VERSION "dbc-export 1 2026.26.6.5"

NS_ :

BS_:

BU_: ADSP APSB CMP DAS EPAS3P GTW OCS1P PTC RCM TCU TCU2 TRCM UDS UI UIS VCLEFT

BO_ 971 APSB_status: 8 APSB
 SG_ APSB_appStatusMonitorState : 0|3@1+ (1,0) [0|7] "" Vector__XXX
 SG_ APSB_vehBehaviorState : 4|4@1+ (1,0) [0|15] "" Vector__XXX
 SG_ APSB_canMaster : 8|2@1+ (1,0) [0|2] "" Vector__XXX
 SG_ APSB_appGpioState : 10|2@1+ (1,0) [0|3] "" Vector__XXX
 SG_ APSB_eacInternalState : 12|3@1+ (1,0) [0|7] "" Vector__XXX
 SG_ APSB_switchState : 15|1@1+ (1,0) [0|1] "" Vector__XXX
 SG_ APSB_apbStatusMonitorState : 16|3@1+ (1,0) [0|7] "" Vector__XXX
 SG_ APSB_apbGpioState : 20|2@1+ (1,0) [0|3] "" Vector__XXX
 SG_ APSB_statusCounter : 22|4@1+ (1,0) [0|15] "" Vector__XXX
 SG_ APSB_locLimitReason : 26|3@1+ (1,0) [0|7] "" Vector__XXX
 SG_ APSB_appPowerStateRequest : 29|2@1+ (1,0) [0|3] "" Vector__XXX
 SG_ APSB_appPowerStateReason : 31|4@1+ (1,0) [0|15] "" Vector__XXX
 SG_ APSB_apbPowerStateRequest : 36|2@1+ (1,0) [0|3] "" Vector__XXX
 SG_ APSB_apbPowerStateReason : 38|4@1+ (1,0) [0|15] "" Vector__XXX
 SG_ APSB_heaterStateDebug : 43|3@1+ (1,0) [0|6] "" Vector__XXX
 SG_ APSB_autosummonCounter : 46|3@1+ (1,0) [0|7] "" Vector__XXX
 SG_ APSB_autosummonAlert : 49|1@1+ (1,0) [0|1] "" Vector__XXX
 SG_ APSB_gpsAntennaState : 50|2@1+ (1,0) [0|3] "" Vector__XXX
 SG_ APSB_arbState : 52|3@1+ (1,0) [0|7] "" Vector__XXX
 SG_ APSB_socPowerOperatingMode : 55|2@1+ (1,0) [0|3] "" Vector__XXX

BO_ 845 APSB_warningMatrix0: 8 APSB
 SG_ APSB_w001_DEPRECATED : 0|1@1+ (1,0) [0|1] "" Vector__XXX
 SG_ APSB_w002_ldwDisabled : 1|1@1+ (1,0) [0|1] "" Vector__XXX
 SG_ APSB_w003_isaDisabled : 2|1@1+ (1,0) [0|1] "" Vector__XXX
 SG_ APSB_w004_accDisabled : 3|1@1+ (1,0) [0|1] "" Vector__XXX
 SG_ APSB_w005_fcwCancelled : 4|1@1+ (1,0) [0|1] "" Vector__XXX
 SG_ APSB_w006_aebCancelled : 5|1@1+ (1,0) [0|1] "" Vector__XXX
 SG_ APSB_w007_ahlbDisabled : 6|1@1+ (1,0) [0|1] "" Vector__XXX
 SG_ APSB_w008_parkDisabled : 7|1@1+ (1,0) [0|1] "" Vector__XXX
 SG_ APSB_w009_aebFault : 8|1@1+ (1,0) [0|1] "" Vector__XXX
 SG_ APSB_w010_radcCalibIssue : 9|1@1+ (1,0) [0|1] "" Vector__XXX
 SG_ APSB_w011_scaEvent : 10|1@1+ (1,0) [0|1] "" Vector__XXX
 SG_ APSB_w012_Cam_BootFailure : 11|1@1+ (1,0) [0|1] "" Vector__XXX
 SG_ APSB_w013_Cam_Watchdog : 12|1@1+ (1,0) [0|1] "" Vector__XXX
 SG_ APSB_w014_swAssert : 13|1@1+ (1,0) [0|1] "" Vector__XXX
 SG_ APSB_w015_Camera_Failsafes : 14|1@1+ (1,0) [0|1] "" Vector__XXX
 SG_ APSB_w016_aeb_e_event : 15|1@1+ (1,0) [0|1] "" Vector__XXX
 SG_ APSB_w017_Cam_Msg_MIA : 16|1@1+ (1,0) [0|1] "" Vector__XXX
 SG_ APSB_w018_ECU_Power_Issue : 17|1@1+ (1,0) [0|1] "" Vector__XXX
 SG_ APSB_w019_ECU_Stack_Overflow : 18|1@1+ (1,0) [0|1] "" Vector__XXX
 SG_ APSB_w020_ECU_checkstopError : 19|1@1+ (1,0) [0|1] "" Vector__XXX
 SG_ APSB_w021_ECU_Temperature_Issue : 20|1@1+ (1,0) [0|1] "" Vector__XXX
 SG_ APSB_w022_ECU_EEPROM_Failure : 21|1@1+ (1,0) [0|1] "" Vector__XXX
 SG_ APSB_w023_ECU_Cam_Statemismatc : 22|1@1+ (1,0) [0|1] "" Vector__XXX
 SG_ APSB_w024_ECU_Watchdog_Reset : 23|1@1+ (1,0) [0|1] "" Vector__XXX
 SG_ APSB_w025_LC_Steering_Override : 24|1@1+ (1,0) [0|1] "" Vector__XXX
 SG_ APSB_w026_ECU_timingIssue : 25|1@1+ (1,0) [0|1] "" Vector__XXX
 SG_ APSB_w027_ECU_Reset_Fault : 26|1@1+ (1,0) [0|1] "" Vector__XXX
 SG_ APSB_w028_spi_rx_error : 27|1@1+ (1,0) [0|1] "" Vector__XXX
 SG_ APSB_w029_spi_tx_error : 28|1@1+ (1,0) [0|1] "" Vector__XXX
 SG_ APSB_w030_Heater_Issue : 29|1@1+ (1,0) [0|1] "" Vector__XXX
 SG_ APSB_w031_canRxError : 30|1@1+ (1,0) [0|1] "" Vector__XXX
 SG_ APSB_w032_canTxError : 31|1@1+ (1,0) [0|1] "" Vector__XXX
 SG_ APSB_w033_gtwMia : 32|1@1+ (1,0) [0|1] "" Vector__XXX
 SG_ APSB_w034_sccmMia : 33|1@1+ (1,0) [0|1] "" Vector__XXX
 SG_ APSB_w035_espMia : 34|1@1+ (1,0) [0|1] "" Vector__XXX
 SG_ APSB_w036_bdyMia : 35|1@1+ (1,0) [0|1] "" Vector__XXX
 SG_ APSB_w037_camTacIssue : 36|1@1+ (1,0) [0|1] "" Vector__XXX
 SG_ APSB_w038_camFailure : 37|1@1+ (1,0) [0|1] "" Vector__XXX
 SG_ APSB_w039_sdm_rcm_Mia : 38|1@1+ (1,0) [0|1] "" Vector__XXX
 SG_ APSB_w040_autopilotAngleSaturate : 39|1@1+ (1,0) [0|1] "" Vector__XXX
 SG_ APSB_w041_autopilotRateSaturated : 40|1@1+ (1,0) [0|1] "" Vector__XXX
 SG_ APSB_w042_autopilotAborting : 41|1@1+ (1,0) [0|1] "" Vector__XXX
 SG_ APSB_w043_camLongRunTime : 42|1@1+ (1,0) [0|1] "" Vector__XXX
 SG_ APSB_w044_appMobileyeFailure : 43|1@1+ (1,0) [0|1] "" Vector__XXX
 SG_ APSB_w045_radMia : 44|1@1+ (1,0) [0|1] "" Vector__XXX
 SG_ APSB_w046_eepromRecordAbsent : 45|1@1+ (1,0) [0|1] "" Vector__XXX
 SG_ APSB_w047_edrEvent : 46|1@1+ (1,0) [0|1] "" Vector__XXX
 SG_ APSB_w048_DAS_Features_Disabled : 47|1@1+ (1,0) [0|1] "" Vector__XXX
 SG_ APSB_w049_eyeqVersionMismatch : 48|1@1+ (1,0) [0|1] "" Vector__XXX
 SG_ APSB_w050_aeb_event : 49|1@1+ (1,0) [0|1] "" Vector__XXX
 SG_ APSB_w051_radcEcuIssue : 50|1@1+ (1,0) [0|1] "" Vector__XXX
 SG_ APSB_w052_radcSensorIssue : 51|1@1+ (1,0) [0|1] "" Vector__XXX
 SG_ APSB_w053_radcCommIssue : 52|1@1+ (1,0) [0|1] "" Vector__XXX
 SG_ APSB_w054_camAutofix : 53|1@1+ (1,0) [0|1] "" Vector__XXX
 SG_ APSB_w055_radcVersionMismatch : 54|1@1+ (1,0) [0|1] "" Vector__XXX
 SG_ APSB_w056_diMia : 55|1@1+ (1,0) [0|1] "" Vector__XXX
 SG_ APSB_w057_mcuMia : 56|1@1+ (1,0) [0|1] "" Vector__XXX
 SG_ APSB_w058_epbMia : 57|1@1+ (1,0) [0|1] "" Vector__XXX
 SG_ APSB_w059_parkMia : 58|1@1+ (1,0) [0|1] "" Vector__XXX
 SG_ APSB_w060_fcw_event : 59|1@1+ (1,0) [0|1] "" Vector__XXX
 SG_ APSB_w061_tasMia : 60|1@1+ (1,0) [0|1] "" Vector__XXX
 SG_ APSB_w062_radcAlignment : 61|1@1+ (1,0) [0|1] "" Vector__XXX
 SG_ APSB_w063_parkVersionMismatch : 62|1@1+ (1,0) [0|1] "" Vector__XXX
 SG_ APSB_w064_epasMia : 63|1@1+ (1,0) [0|1] "" Vector__XXX

BO_ 1143 APSB_warningMatrix1: 8 APSB
 SG_ APSB_w065_deserializerOvercurren : 0|1@1+ (1,0) [0|1] "" Vector__XXX
 SG_ APSB_w066_deserializerLockLost : 1|1@1+ (1,0) [0|1] "" Vector__XXX
 SG_ APSB_w067_steeringAlignment : 2|1@1+ (1,0) [0|1] "" Vector__XXX
 SG_ APSB_w068_vlInconsistency : 3|1@1+ (1,0) [0|1] "" Vector__XXX
 SG_ APSB_w069_apcSpaceMasked : 4|1@1+ (1,0) [0|1] "" Vector__XXX
 SG_ APSB_w070_apcIncompleteCal : 5|1@1+ (1,0) [0|1] "" Vector__XXX
 SG_ APSB_w071_selfparkStarted : 6|1@1+ (1,0) [0|1] "" Vector__XXX
 SG_ APSB_w072_selfparkComplete : 7|1@1+ (1,0) [0|1] "" Vector__XXX
 SG_ APSB_w073_issueEscalatedLDW : 8|1@1+ (1,0) [0|1] "" Vector__XXX
 SG_ APSB_w074_inPathStationaryObst : 9|1@1+ (1,0) [0|1] "" Vector__XXX
 SG_ APSB_w075_scMia : 10|1@1+ (1,0) [0|1] "" Vector__XXX
 SG_ APSB_w076_mobilEyeSetC : 11|1@1+ (1,0) [0|1] "" Vector__XXX
 SG_ APSB_w077_pmmActive : 12|1@1+ (1,0) [0|1] "" Vector__XXX
 SG_ APSB_w078_pmmActive2 : 13|1@1+ (1,0) [0|1] "" Vector__XXX
 SG_ APSB_w079_edrAvailable : 14|1@1+ (1,0) [0|1] "" Vector__XXX
 SG_ APSB_w080_accFailedActivation : 15|1@1+ (1,0) [0|1] "" Vector__XXX
 SG_ APSB_w081_pmmActiveBraking : 16|1@1+ (1,0) [0|1] "" Vector__XXX
 SG_ APSB_w082_inPathFSviolation : 17|1@1+ (1,0) [0|1] "" Vector__XXX
 SG_ APSB_w083_inPathRADObject : 18|1@1+ (1,0) [0|1] "" Vector__XXX
 SG_ APSB_w084_pmmIPSO : 19|1@1+ (1,0) [0|1] "" Vector__XXX
 SG_ APSB_w085_pmmSteering : 20|1@1+ (1,0) [0|1] "" Vector__XXX
 SG_ APSB_w086_robCollision : 21|1@1+ (1,0) [0|1] "" Vector__XXX
 SG_ APSB_w087_DEPRECATED : 22|1@1+ (1,0) [0|1] "" Vector__XXX
 SG_ APSB_w088_DEPRECATED : 23|1@1+ (1,0) [0|1] "" Vector__XXX
 SG_ APSB_w089_DEPRECATED : 24|1@1+ (1,0) [0|1] "" Vector__XXX
 SG_ APSB_w090_DEPRECATED : 25|1@1+ (1,0) [0|1] "" Vector__XXX
 SG_ APSB_w091_DEPRECATED : 26|1@1+ (1,0) [0|1] "" Vector__XXX
 SG_ APSB_w092_DEPRECATED : 27|1@1+ (1,0) [0|1] "" Vector__XXX
 SG_ APSB_w093_DEPRECATED : 28|1@1+ (1,0) [0|1] "" Vector__XXX
 SG_ APSB_w094_DEPRECATED : 29|1@1+ (1,0) [0|1] "" Vector__XXX
 SG_ APSB_w095_DEPRECATED : 30|1@1+ (1,0) [0|1] "" Vector__XXX
 SG_ APSB_w096_DEPRECATED : 31|1@1+ (1,0) [0|1] "" Vector__XXX
 SG_ APSB_w097_DEPRECATED : 32|1@1+ (1,0) [0|1] "" Vector__XXX
 SG_ APSB_w098_DEPRECATED : 33|1@1+ (1,0) [0|1] "" Vector__XXX
 SG_ APSB_w099_DEPRECATED : 34|1@1+ (1,0) [0|1] "" Vector__XXX
 SG_ APSB_w100_DEPRECATED : 35|1@1+ (1,0) [0|1] "" Vector__XXX
 SG_ APSB_w101_DEPRECATED : 36|1@1+ (1,0) [0|1] "" Vector__XXX
 SG_ APSB_w102_DEPRECATED : 37|1@1+ (1,0) [0|1] "" Vector__XXX
 SG_ APSB_w103_robExperimentalAEB : 38|1@1+ (1,0) [0|1] "" Vector__XXX
 SG_ APSB_w104_DEPRECATED : 39|1@1+ (1,0) [0|1] "" Vector__XXX
 SG_ APSB_w105_DEPRECATED : 40|1@1+ (1,0) [0|1] "" Vector__XXX
 SG_ APSB_w106_torsionBarOffset : 41|1@1+ (1,0) [0|1] "" Vector__XXX

BO_ 942 APSB_warningMatrix2: 8 APSB
 SG_ APSB_w129_ECU_Power_Issue : 0|1@1+ (1,0) [0|1] "" Vector__XXX
 SG_ APSB_w130_ECU_Thermal_Issue : 1|1@1+ (1,0) [0|1] "" Vector__XXX
 SG_ APSB_w131_trap_exception : 2|1@1+ (1,0) [0|1] "" Vector__XXX
 SG_ APSB_w132_appVersionMismatch : 3|1@1+ (1,0) [0|1] "" Vector__XXX
 SG_ APSB_w133_ETHSwitchError : 4|1@1+ (1,0) [0|1] "" Vector__XXX
 SG_ APSB_w134_appMia : 5|1@1+ (1,0) [0|1] "" Vector__XXX
 SG_ APSB_w135_appCritical : 6|1@1+ (1,0) [0|1] "" Vector__XXX
 SG_ APSB_w136_gpsDisabled : 7|1@1+ (1,0) [0|1] "" Vector__XXX
 SG_ APSB_w137_gpsFaultReset : 8|1@1+ (1,0) [0|1] "" Vector__XXX
 SG_ APSB_w138_gpsComIssue : 9|1@1+ (1,0) [0|1] "" Vector__XXX
 SG_ APSB_w139_udpBufferOverflow : 10|1@1+ (1,0) [0|1] "" Vector__XXX
 SG_ APSB_w140_vcfrontMiaVehicleBus : 11|1@1+ (1,0) [0|1] "" Vector__XXX
 SG_ APSB_w141_rcmMiaPartyBus : 12|1@1+ (1,0) [0|1] "" Vector__XXX
 SG_ APSB_w142_diMiaPartyBus : 13|1@1+ (1,0) [0|1] "" Vector__XXX
 SG_ APSB_w143_espMiaPartyBus : 14|1@1+ (1,0) [0|1] "" Vector__XXX
 SG_ APSB_w144_vcleftMiaPartyBus : 15|1@1+ (1,0) [0|1] "" Vector__XXX
 SG_ APSB_w145_vcrightMiaPartyBus : 16|1@1+ (1,0) [0|1] "" Vector__XXX
 SG_ APSB_w146_epas3pMiaPartyBus : 17|1@1+ (1,0) [0|1] "" Vector__XXX
 SG_ APSB_w147_vcleftMiaVehBus : 18|1@1+ (1,0) [0|1] "" Vector__XXX
 SG_ APSB_w148_vcrightMiaVehBus : 19|1@1+ (1,0) [0|1] "" Vector__XXX
 SG_ APSB_w149_epblMiaVehBus : 20|1@1+ (1,0) [0|1] "" Vector__XXX
 SG_ APSB_w150_sccmMiaVehBus : 21|1@1+ (1,0) [0|1] "" Vector__XXX
 SG_ APSB_w151_apRecovered : 22|1@1+ (1,0) [0|1] "" Vector__XXX
 SG_ APSB_w152_gpsFusionStatus : 23|1@1+ (1,0) [0|1] "" Vector__XXX
 SG_ APSB_w153_eacInhibit : 24|1@1+ (1,0) [0|1] "" Vector__XXX
 SG_ APSB_w155_ethLwipError : 26|1@1+ (1,0) [0|1] "" Vector__XXX
 SG_ APSB_w156_lwipAssert : 27|1@1+ (1,0) [0|1] "" Vector__XXX
 SG_ APSB_w157_autopilotReboot : 28|1@1+ (1,0) [0|1] "" Vector__XXX
 SG_ APSB_w158_apbMia : 29|1@1+ (1,0) [0|1] "" Vector__XXX
 SG_ APSB_w159_apbCritical : 30|1@1+ (1,0) [0|1] "" Vector__XXX
 SG_ APSB_w160_apbVersionMismatch : 31|1@1+ (1,0) [0|1] "" Vector__XXX
 SG_ APSB_w161_gpsAntennaDisconnected : 32|1@1+ (1,0) [0|1] "" Vector__XXX
 SG_ APSB_w162_TurboA_DisRegPgoodErr : 33|1@1+ (1,0) [0|1] "" Vector__XXX
 SG_ APSB_w163_TurboA_DisRegNFault : 34|1@1+ (1,0) [0|1] "" Vector__XXX
 SG_ APSB_w164_TurboA_12VFuseFault : 35|1@1+ (1,0) [0|1] "" Vector__XXX
 SG_ APSB_w165_TurboA_Temp_NOS : 36|1@1+ (1,0) [0|1] "" Vector__XXX
 SG_ APSB_w166_TurboA_SMSLockStepErr : 37|1@1+ (1,0) [0|1] "" Vector__XXX
 SG_ APSB_w167_TurboA_TMU_Throttle : 38|1@1+ (1,0) [0|1] "" Vector__XXX
 SG_ APSB_w168_TurboA_SMS_WDOG : 39|1@1+ (1,0) [0|1] "" Vector__XXX
 SG_ APSB_w169_TurboA_SCS_LKUP : 40|1@1+ (1,0) [0|1] "" Vector__XXX
 SG_ APSB_w170_TurboA_A72_watchdog : 41|1@1+ (1,0) [0|1] "" Vector__XXX
 SG_ APSB_w171_TurboA_SMS_taskUtilErr : 42|1@1+ (1,0) [0|1] "" Vector__XXX
 SG_ APSB_w172_apFeaturesUnavailable : 43|1@1+ (1,0) [0|1] "" Vector__XXX
 SG_ APSB_w178_TurboB_DisRegPgoodErr : 49|1@1+ (1,0) [0|1] "" Vector__XXX
 SG_ APSB_w179_TurboB_DisRegNFault : 50|1@1+ (1,0) [0|1] "" Vector__XXX
 SG_ APSB_w180_TurboB_12VFuseFault : 51|1@1+ (1,0) [0|1] "" Vector__XXX
 SG_ APSB_w181_TurboB_Temp_NOS : 52|1@1+ (1,0) [0|1] "" Vector__XXX
 SG_ APSB_w182_TurboB_SMSLockStepErr : 53|1@1+ (1,0) [0|1] "" Vector__XXX
 SG_ APSB_w183_TurboB_TMU_Throttle : 54|1@1+ (1,0) [0|1] "" Vector__XXX
 SG_ APSB_w184_TurboB_SMS_WDOG : 55|1@1+ (1,0) [0|1] "" Vector__XXX
 SG_ APSB_w185_TurboB_SCS_LKUP : 56|1@1+ (1,0) [0|1] "" Vector__XXX
 SG_ APSB_w186_TurboB_A72_watchdog : 57|1@1+ (1,0) [0|1] "" Vector__XXX
 SG_ APSB_w187_TurboB_SMS_taskUtilErr : 58|1@1+ (1,0) [0|1] "" Vector__XXX
 SG_ APSB_w188_otherTurboUartMIA : 59|1@1+ (1,0) [0|1] "" Vector__XXX
 SG_ APSB_w189_vcfrontMiaPartyBus : 60|1@1+ (1,0) [0|1] "" Vector__XXX
 SG_ APSB_w190_iboosterMia : 61|1@1+ (1,0) [0|1] "" Vector__XXX
 SG_ APSB_w191_timesyncError : 62|1@1+ (1,0) [0|1] "" Vector__XXX
 SG_ APSB_w192_CANFault : 63|1@1+ (1,0) [0|1] "" Vector__XXX

BO_ 976 APSB_warningMatrix3: 8 APSB
 SG_ APSB_w193_camWindshieldUnclean : 0|1@1+ (1,0) [0|1] "" Vector__XXX
 SG_ APSB_w194_accDriverResumeRqrd : 1|1@1+ (1,0) [0|1] "" Vector__XXX
 SG_ APSB_w195_scwUnavailable : 2|1@1+ (1,0) [0|1] "" Vector__XXX
 SG_ APSB_w196_stopSignWarning : 3|1@1+ (1,0) [0|1] "" Vector__XXX
 SG_ APSB_w197_redLightWarning : 4|1@1+ (1,0) [0|1] "" Vector__XXX
 SG_ APSB_w198_tsrUnavailable : 5|1@1+ (1,0) [0|1] "" Vector__XXX
 SG_ APSB_w199_apcAbort : 6|1@1+ (1,0) [0|1] "" Vector__XXX
 SG_ APSB_w200_lcSlowdown : 7|1@1+ (1,0) [0|1] "" Vector__XXX
 SG_ APSB_w201_lcAborting : 8|1@1+ (1,0) [0|1] "" Vector__XXX
 SG_ APSB_w202_scwNoisyEnvironment : 9|1@1+ (1,0) [0|1] "" Vector__XXX
 SG_ APSB_w203_apcActivation : 10|1@1+ (1,0) [0|1] "" Vector__XXX
 SG_ APSB_w204_apcFinalFront : 11|1@1+ (1,0) [0|1] "" Vector__XXX
 SG_ APSB_w205_apcFinalRear : 12|1@1+ (1,0) [0|1] "" Vector__XXX
 SG_ APSB_w206_autosteerNotEnabled : 13|1@1+ (1,0) [0|1] "" Vector__XXX
 SG_ APSB_w207_autosteerUnavailable : 14|1@1+ (1,0) [0|1] "" Vector__XXX
 SG_ APSB_w208_rackDetected : 15|1@1+ (1,0) [0|1] "" Vector__XXX
 SG_ APSB_w209_autoSummonRequest : 16|1@1+ (1,0) [0|1] "" Vector__XXX
 SG_ APSB_w210_camObstrcted : 17|1@1+ (1,0) [0|1] "" Vector__XXX
 SG_ APSB_w211_accNoSeatBelt : 18|1@1+ (1,0) [0|1] "" Vector__XXX
 SG_ APSB_w212_lcUnavailableStrikeOut : 19|1@1+ (1,0) [0|1] "" Vector__XXX
 SG_ APSB_w213_autosteerStruckOut : 20|1@1+ (1,0) [0|1] "" Vector__XXX
 SG_ APSB_w214_driverNotIntracting : 21|1@1+ (1,0) [0|1] "" Vector__XXX
 SG_ APSB_w215_contDriverNotIntractin : 22|1@1+ (1,0) [0|1] "" Vector__XXX
 SG_ APSB_w216_driverOverriding : 23|1@1+ (1,0) [0|1] "" Vector__XXX
 SG_ APSB_w217_lcUnavailableSpeeding : 24|1@1+ (1,0) [0|1] "" Vector__XXX
 SG_ APSB_w218_lcSpeedExceededLimit : 25|1@1+ (1,0) [0|1] "" Vector__XXX
 SG_ APSB_w219_lcTempUnavailableSpeed : 26|1@1+ (1,0) [0|1] "" Vector__XXX
 SG_ APSB_w220_lcTempUnavailableRoad : 27|1@1+ (1,0) [0|1] "" Vector__XXX
 SG_ APSB_w221_accRadarBlind : 28|1@1+ (1,0) [0|1] "" Vector__XXX
 SG_ APSB_w222_accCameraBlind : 29|1@1+ (1,0) [0|1] "" Vector__XXX
 SG_ APSB_w223_accObjectInPath : 30|1@1+ (1,0) [0|1] "" Vector__XXX
 SG_ APSB_w224_accCameraCalibration : 31|1@1+ (1,0) [0|1] "" Vector__XXX
 SG_ APSB_w225_lcDegradedVisSpeedLmt : 32|1@1+ (1,0) [0|1] "" Vector__XXX
 SG_ APSB_w226_lcCamCalNeededSpeedLmt : 33|1@1+ (1,0) [0|1] "" Vector__XXX
 SG_ APSB_w227_virtualWallBlocked : 34|1@1+ (1,0) [0|1] "" Vector__XXX
 SG_ APSB_w228_DEPRECATED : 35|1@1+ (1,0) [0|1] "" Vector__XXX
 SG_ APSB_w229_alcUltrasoundDamaged : 36|1@1+ (1,0) [0|1] "" Vector__XXX
 SG_ APSB_w230_alcUltrasoundBlocked : 37|1@1+ (1,0) [0|1] "" Vector__XXX
 SG_ APSB_w231_idfEvent : 38|1@1+ (1,0) [0|1] "" Vector__XXX
 SG_ APSB_w232_laneChangeRequested : 39|1@1+ (1,0) [0|1] "" Vector__XXX
 SG_ APSB_w235_a72LoopDetected : 42|1@1+ (1,0) [0|1] "" Vector__XXX
 SG_ APSB_w236_canSharedMemError : 43|1@1+ (1,0) [0|1] "" Vector__XXX
 SG_ APSB_w237_faultMgrEventDetected : 44|1@1+ (1,0) [0|1] "" Vector__XXX
 SG_ APSB_w238_resetReason : 45|1@1+ (1,0) [0|1] "" Vector__XXX
 SG_ APSB_w241_ddrInitFailures : 48|1@1+ (1,0) [0|1] "" Vector__XXX
 SG_ APSB_w242_tripMBISTFailure : 49|1@1+ (1,0) [0|1] "" Vector__XXX
 SG_ APSB_w243_tripHWErrorStatus : 50|1@1+ (1,0) [0|1] "" Vector__XXX
 SG_ APSB_w244_gpuHWFaultStatus : 51|1@1+ (1,0) [0|1] "" Vector__XXX
 SG_ APSB_w245_eloopRxFromUnexpectedS : 52|1@1+ (1,0) [0|1] "" Vector__XXX
 SG_ APSB_w246_ethloopSwitchPortLinkD : 53|1@1+ (1,0) [0|1] "" Vector__XXX
 SG_ APSB_w247_ethernetFrameError : 54|1@1+ (1,0) [0|1] "" Vector__XXX
 SG_ APSB_w248_ethloopSwitchPoorSqi : 55|1@1+ (1,0) [0|1] "" Vector__XXX
 SG_ APSB_w249_ufsFailures : 56|1@1+ (1,0) [0|1] "" Vector__XXX
 SG_ APSB_w250_ethloopSwitchMemUsageT : 57|1@1+ (1,0) [0|1] "" Vector__XXX
 SG_ APSB_w251_ethloopSwitchMemUsageT : 58|1@1+ (1,0) [0|1] "" Vector__XXX
 SG_ APSB_w252_ethSwitchPortLinkDown : 59|1@1+ (1,0) [0|1] "" Vector__XXX
 SG_ APSB_w253_powerStateTimeout : 60|1@1+ (1,0) [0|1] "" Vector__XXX
 SG_ APSB_w254_sleepStateTimeout : 61|1@1+ (1,0) [0|1] "" Vector__XXX
 SG_ APSB_w255_bootHealth : 62|1@1+ (1,0) [0|1] "" Vector__XXX

BO_ 1003 APSB_warningMatrix4: 8 APSB
 SG_ APSB_w257_assertFailure : 0|1@1+ (1,0) [0|1] "" Vector__XXX
 SG_ APSB_w258_qspiFlashSectorChecksu : 1|1@1+ (1,0) [0|1] "" Vector__XXX
 SG_ APSB_w259_qspiFailure : 2|1@1+ (1,0) [0|1] "" Vector__XXX
 SG_ APSB_w260_pgoodFailure : 3|1@1+ (1,0) [0|1] "" Vector__XXX
 SG_ APSB_w261_vrmFaultGrpA : 4|1@1+ (1,0) [0|1] "" Vector__XXX
 SG_ APSB_w262_vrmFaultGrpB : 5|1@1+ (1,0) [0|1] "" Vector__XXX
 SG_ APSB_w263_vrmFaultGrpC : 6|1@1+ (1,0) [0|1] "" Vector__XXX
 SG_ APSB_w264_ddrPhy0Failures : 7|1@1+ (1,0) [0|1] "" Vector__XXX
 SG_ APSB_w265_ddrPhy1Failures : 8|1@1+ (1,0) [0|1] "" Vector__XXX
 SG_ APSB_w266_ddrPhy2Failures : 9|1@1+ (1,0) [0|1] "" Vector__XXX
 SG_ APSB_w267_ddrPhy3Failures : 10|1@1+ (1,0) [0|1] "" Vector__XXX
 SG_ APSB_w268_ddrControllerFailures : 11|1@1+ (1,0) [0|1] "" Vector__XXX
 SG_ APSB_w269_ethSwitchRxPageCountTo : 12|1@1+ (1,0) [0|1] "" Vector__XXX
 SG_ APSB_w270_ethSwitchRxPageCountTo : 13|1@1+ (1,0) [0|1] "" Vector__XXX
 SG_ APSB_w271_ddrScheduler0EccErrors : 14|1@1+ (1,0) [0|1] "" Vector__XXX
 SG_ APSB_w272_ddrScheduler1EccErrors : 15|1@1+ (1,0) [0|1] "" Vector__XXX
 SG_ APSB_w273_ddrScheduler2EccErrors : 16|1@1+ (1,0) [0|1] "" Vector__XXX
 SG_ APSB_w274_ddrScheduler3EccErrors : 17|1@1+ (1,0) [0|1] "" Vector__XXX
 SG_ APSB_w275_ddrScheduler4EccErrors : 18|1@1+ (1,0) [0|1] "" Vector__XXX
 SG_ APSB_w276_ddrScheduler5EccErrors : 19|1@1+ (1,0) [0|1] "" Vector__XXX
 SG_ APSB_w277_ddrScheduler6EccErrors : 20|1@1+ (1,0) [0|1] "" Vector__XXX
 SG_ APSB_w278_ddrScheduler7EccErrors : 21|1@1+ (1,0) [0|1] "" Vector__XXX
 SG_ APSB_w279_ufsPartitionError : 22|1@1+ (1,0) [0|1] "" Vector__XXX
 SG_ APSB_w280_pepsMia : 23|1@1+ (1,0) [0|1] "" Vector__XXX
 SG_ APSB_w281_rsaMia : 24|1@1+ (1,0) [0|1] "" Vector__XXX
 SG_ APSB_w282_smmuError : 25|1@1+ (1,0) [0|1] "" Vector__XXX
 SG_ APSB_w283_psfaMia : 26|1@1+ (1,0) [0|1] "" Vector__XXX
 SG_ APSB_w284_cam12VBuckBoostAPwrIss : 27|1@1+ (1,0) [0|1] "" Vector__XXX
 SG_ APSB_w285_cam12VBuckBoostBPwrIss : 28|1@1+ (1,0) [0|1] "" Vector__XXX
 SG_ APSB_w286_cam12VEFuseAPrimaryIss : 29|1@1+ (1,0) [0|1] "" Vector__XXX
 SG_ APSB_w287_cam12VEFuseASecondaryI : 30|1@1+ (1,0) [0|1] "" Vector__XXX
 SG_ APSB_w288_brakeboosterMia : 31|1@1+ (1,0) [0|1] "" Vector__XXX
 SG_ APSB_w289_turboTemperatureWarnin : 32|1@1+ (1,0) [0|1] "" Vector__XXX
 SG_ APSB_w290_cam12VBuckBoostBPwrRin : 33|1@1+ (1,0) [0|1] "" Vector__XXX
 SG_ APSB_w291_eplannerError : 34|1@1+ (1,0) [0|1] "" Vector__XXX
 SG_ APSB_w292_CH_busOff : 35|1@1+ (1,0) [0|1] "" Vector__XXX
 SG_ APSB_w293_PARTY_busOff : 36|1@1+ (1,0) [0|1] "" Vector__XXX
 SG_ APSB_w294_VEH_busOff : 37|1@1+ (1,0) [0|1] "" Vector__XXX
 SG_ APSB_w295_PT_busOff : 38|1@1+ (1,0) [0|1] "" Vector__XXX
 SG_ APSB_w296_wdogMonTaskDeadlineMis : 39|1@1+ (1,0) [0|1] "" Vector__XXX
 SG_ APSB_w297_earlyWDogAlert : 40|1@1+ (1,0) [0|1] "" Vector__XXX
 SG_ APSB_w298_cpuToApCanSharedMemErr : 41|1@1+ (1,0) [0|1] "" Vector__XXX
 SG_ APSB_w299_apToCpuCanSharedMemErr : 42|1@1+ (1,0) [0|1] "" Vector__XXX
 SG_ APSB_w300_sharedMemoryAccessErro : 43|1@1+ (1,0) [0|1] "" Vector__XXX
 SG_ APSB_w301_nocTimeoutDetected : 44|1@1+ (1,0) [0|1] "" Vector__XXX
 SG_ APSB_w302_canAPShmFifoFull : 45|1@1+ (1,0) [0|1] "" Vector__XXX
 SG_ APSB_w303_canAPShmFifoEmpty : 46|1@1+ (1,0) [0|1] "" Vector__XXX
 SG_ APSB_w304_dataAbort : 47|1@1+ (1,0) [0|1] "" Vector__XXX
 SG_ APSB_w305_gpsPgoodFailure : 48|1@1+ (1,0) [0|1] "" Vector__XXX
 SG_ APSB_w306_ethPgoodFailure : 49|1@1+ (1,0) [0|1] "" Vector__XXX
 SG_ APSB_w307_eccEventDetected : 50|1@1+ (1,0) [0|1] "" Vector__XXX
 SG_ APSB_w308_pmicErrorDetected : 51|1@1+ (1,0) [0|1] "" Vector__XXX
 SG_ APSB_w309_ethBridgeDown : 52|1@1+ (1,0) [0|1] "" Vector__XXX
 SG_ APSB_w310_wakeBootMetrics : 53|1@1+ (1,0) [0|1] "" Vector__XXX
 SG_ APSB_w311_apbdgDasMia : 54|1@1+ (1,0) [0|1] "" Vector__XXX
 SG_ APSB_w312_apbdgApMia : 55|1@1+ (1,0) [0|1] "" Vector__XXX
 SG_ APSB_w313_BDY_busOff : 56|1@1+ (1,0) [0|1] "" Vector__XXX
 SG_ APSB_w315_epas3pMiaBdyBus : 58|1@1+ (1,0) [0|1] "" Vector__XXX
 SG_ APSB_w316_apBootHealth : 59|1@1+ (1,0) [0|1] "" Vector__XXX
 SG_ APSB_w317_uiMia : 60|1@1+ (1,0) [0|1] "" Vector__XXX
 SG_ APSB_w318_ethernetNetworkBufferH : 61|1@1+ (1,0) [0|1] "" Vector__XXX
 SG_ APSB_w319_vehDasImposterDetected : 62|1@1+ (1,0) [0|1] "" Vector__XXX
 SG_ APSB_w320_eplannerPreconditionsM : 63|1@1+ (1,0) [0|1] "" Vector__XXX

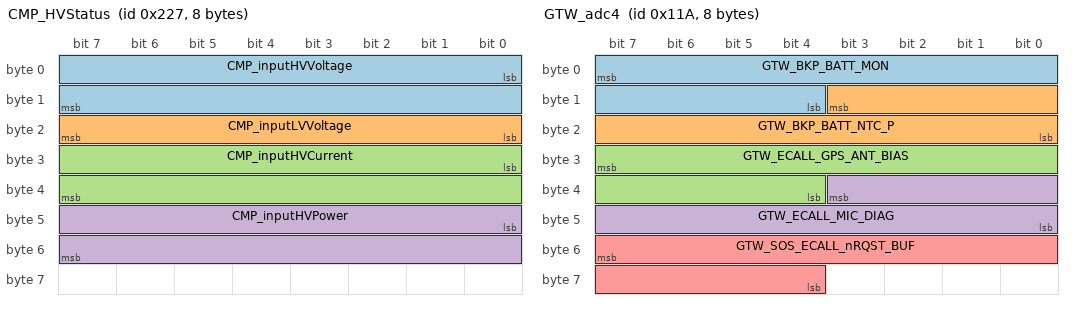
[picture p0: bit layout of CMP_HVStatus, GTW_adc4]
BO_ 551 CMP_HVStatus: 8 CMP
 SG_ CMP_inputHVVoltage : 0|16@1+ (0.1,0) [0|6553.4] "V" Vector__XXX
 SG_ CMP_inputLVVoltage : 16|8@1+ (0.1,0) [0|25.5] "V" Vector__XXX
 SG_ CMP_inputHVCurrent : 24|16@1+ (0.1,0) [0|6553.4] "A" Vector__XXX
 SG_ CMP_inputHVPower : 40|16@1+ (1,0) [0|65534] "W" Vector__XXX

BO_ 778 DAS_object: 8 DAS
 SG_ DAS_objectId M : 0|3@1+ (1,0) [0|7] "" Vector__XXX
 SG_ DAS_leadVehType m0 : 3|3@1+ (1,0) [0|7] "" Vector__XXX
 SG_ DAS_leadVehRelevantForControl m0 : 7|1@1+ (1,0) [0|1] "" Vector__XXX
 SG_ DAS_leadVehDx m0 : 8|8@1+ (0.5,0) [0|127] "m" Vector__XXX
 SG_ DAS_leadVehVxRel m0 : 16|4@1+ (4,-30) [-30|26] "m/s" Vector__XXX
 SG_ DAS_leadVehDy m0 : 20|7@1+ (0.35,-22.05) [-22.05|22.4] "m" Vector__XXX
 SG_ DAS_leadVehId m0 : 27|7@1+ (1,0) [0|126] "" Vector__XXX
 SG_ DAS_leadVeh2Type m0 : 34|3@1+ (1,0) [0|7] "" Vector__XXX
 SG_ DAS_leadVeh2RelevantForControl m0 : 38|1@1+ (1,0) [0|1] "" Vector__XXX
 SG_ DAS_leadVeh2Dx m0 : 39|8@1+ (0.5,0) [0|127] "m" Vector__XXX
 SG_ DAS_leadVeh2VxRel m0 : 47|4@1+ (4,-30) [-30|26] "m/s" Vector__XXX
 SG_ DAS_leadVeh2Dy m0 : 51|7@1+ (0.35,-22.05) [-22.05|22.4] "m" Vector__XXX
 SG_ DAS_leadVeh2Id m0 : 58|6@1+ (1,0) [1|63] "" Vector__XXX
 SG_ DAS_leftVehType m1 : 3|3@1+ (1,0) [0|7] "" Vector__XXX
 SG_ DAS_leftVehRelevantForControl m1 : 7|1@1+ (1,0) [0|1] "" Vector__XXX
 SG_ DAS_leftVehDx m1 : 8|8@1+ (0.5,0) [0|127] "m" Vector__XXX
 SG_ DAS_leftVehVxRel m1 : 16|4@1+ (4,-30) [-30|26] "m/s" Vector__XXX
 SG_ DAS_leftVehDy m1 : 20|7@1+ (0.35,-22.05) [-22.05|22.4] "m" Vector__XXX
 SG_ DAS_leftVehId m1 : 27|7@1+ (1,0) [0|126] "" Vector__XXX
 SG_ DAS_leftVeh2Type m1 : 34|3@1+ (1,0) [0|7] "" Vector__XXX
 SG_ DAS_leftVeh2RelevantForControl m1 : 38|1@1+ (1,0) [0|1] "" Vector__XXX
 SG_ DAS_leftVeh2Dx m1 : 39|8@1+ (0.5,0) [0|127] "m" Vector__XXX
 SG_ DAS_leftVeh2VxRel m1 : 47|4@1+ (4,-30) [-30|26] "m/s" Vector__XXX
 SG_ DAS_leftVeh2Dy m1 : 51|7@1+ (0.35,-22.05) [-22.05|22.4] "m" Vector__XXX
 SG_ DAS_leftVeh2Id m1 : 58|6@1+ (1,0) [1|63] "" Vector__XXX
 SG_ DAS_rightVehType m2 : 3|3@1+ (1,0) [0|7] "" Vector__XXX
 SG_ DAS_rightVehRelevantForControl m2 : 7|1@1+ (1,0) [0|1] "" Vector__XXX
 SG_ DAS_rightVehDx m2 : 8|8@1+ (0.5,0) [0|127] "m" Vector__XXX
 SG_ DAS_rightVehVxRel m2 : 16|4@1+ (4,-30) [-30|26] "m/s" Vector__XXX
 SG_ DAS_rightVehDy m2 : 20|7@1+ (0.35,-22.05) [-22.05|22.4] "m" Vector__XXX
 SG_ DAS_rightVehId m2 : 27|7@1+ (1,0) [0|126] "" Vector__XXX
 SG_ DAS_rightVeh2Type m2 : 34|3@1+ (1,0) [0|7] "" Vector__XXX
 SG_ DAS_rightVeh2RelevantForControl m2 : 38|1@1+ (1,0) [0|1] "" Vector__XXX
 SG_ DAS_rightVeh2Dx m2 : 39|8@1+ (0.5,0) [0|127] "m" Vector__XXX
 SG_ DAS_rightVeh2VxRel m2 : 47|4@1+ (4,-30) [-30|26] "m/s" Vector__XXX
 SG_ DAS_rightVeh2Dy m2 : 51|7@1+ (0.35,-22.05) [-22.05|22.4] "m" Vector__XXX
 SG_ DAS_rightVeh2Id m2 : 58|6@1+ (1,0) [1|63] "" Vector__XXX
 SG_ DAS_cutinVehType m3 : 3|3@1+ (1,0) [0|7] "" Vector__XXX
 SG_ DAS_cutinVehRelevantForControl m3 : 7|1@1+ (1,0) [0|1] "" Vector__XXX
 SG_ DAS_cutinVehDx m3 : 8|8@1+ (0.5,0) [0|127] "m" Vector__XXX
 SG_ DAS_cutinVehVxRel m3 : 16|4@1+ (4,-30) [-30|26] "m/s" Vector__XXX
 SG_ DAS_cutinVehDy m3 : 20|7@1+ (0.35,-22.05) [-22.05|22.4] "m" Vector__XXX
 SG_ DAS_cutinVehId m3 : 27|7@1+ (1,0) [0|126] "" Vector__XXX
 SG_ DAS_roadSignColor m4 : 3|3@1+ (1,0) [0|7] "" Vector__XXX
 SG_ DAS_roadSignId m4 : 6|8@1+ (1,0) [0|254] "" Vector__XXX
 SG_ DAS_roadSignStopLineDist m4 : 14|10@1+ (0.2,-20) [-20|184.4] "m" Vector__XXX
 SG_ DAS_roadSignControlActive m4 : 24|1@1+ (1,0) [0|1] "" Vector__XXX
 SG_ DAS_roadSignSource m4 : 25|2@1+ (1,0) [0|3] "" Vector__XXX
 SG_ DAS_roadSignArrow m4 : 27|3@1+ (1,0) [0|7] "" Vector__XXX
 SG_ DAS_roadSignOrientation m4 : 30|2@1+ (1,0) [0|3] "" Vector__XXX

BO_ 781 DAS_positioningEngineStatus: 8 DAS
 SG_ DAS_positioningEngineStatusMulti M : 0|4@1+ (1,0) [0|15] "" Vector__XXX
 SG_ DAS_meoSolverNumRuns m2 : 4|2@1+ (1,0) [0|3] "" Vector__XXX
 SG_ DAS_meoSolverReportTerminationTy m2 : 6|3@1+ (1,0) [0|7] "" Vector__XXX
 SG_ DAS_meoSolverReportTotalTimeS m2 : 9|3@1+ (1,0) [0|7] "" Vector__XXX
 SG_ DAS_meoHorizontalAccuracyM m2 : 12|6@1+ (1,0) [0|63] "m" Vector__XXX
 SG_ DAS_meoVerticalAccuracyM m2 : 18|6@1+ (1,0) [0|63] "m" Vector__XXX
 SG_ DAS_meoHeadingAccuracyDeg m2 : 24|3@1+ (1,0) [0|7] "deg" Vector__XXX
 SG_ DAS_meoHeadingValid m2 : 27|1@1+ (1,0) [0|1] "" Vector__XXX
 SG_ DAS_meoNumSatellitesUsed m2 : 28|5@1+ (1,0) [0|31] "" Vector__XXX
 SG_ DAS_meoGpsQualityLevel m2 : 33|3@1+ (1,0) [0|7] "" Vector__XXX
 SG_ DAS_meoFixType m2 : 36|3@1+ (1,0) [0|7] "" Vector__XXX
 SG_ DAS_meoResetCount m2 : 39|3@1+ (1,0) [0|7] "" Vector__XXX
 SG_ DAS_lastMeoResetReason m2 : 42|2@1+ (1,0) [0|3] "" Vector__XXX
 SG_ DAS_vioMultiGpsSelectedSource m3 : 4|3@1+ (1,0) [0|7] "" Vector__XXX
 SG_ DAS_vioMultiGpsPeCooldownActive m3 : 7|1@1+ (1,0) [0|1] "" Vector__XXX
 SG_ DAS_vioMultiGpsPeSppTdcpConsiste m3 : 8|1@1+ (1,0) [0|1] "" Vector__XXX
 SG_ DAS_vioMultiGpsPeMeoConsistentWi m3 : 9|1@1+ (1,0) [0|1] "" Vector__XXX
 SG_ DAS_vioMultiGpsPeSppTdcpVsR_0001 m3 : 10|4@1+ (1,0) [0|15] "m" Vector__XXX
 SG_ DAS_vioMultiGpsPeMeoVsRawGpsTran m3 : 14|4@1+ (1,0) [0|15] "m" Vector__XXX
 SG_ DAS_vioMultiGpsPeSppTdcpVsRawGps m3 : 18|3@1+ (1,0) [0|7] "deg" Vector__XXX
 SG_ DAS_vioMultiGpsPeMeoVsRawGpsRotD m3 : 21|3@1+ (1,0) [0|7] "deg" Vector__XXX
 SG_ DAS_publishedGpsSource m3 : 24|2@1+ (1,0) [0|3] "" Vector__XXX
 SG_ DAS_bluefinEnabled m3 : 26|1@1+ (1,0) [0|1] "" Vector__XXX
 SG_ DAS_orioleDisabled m3 : 27|1@1+ (1,0) [0|1] "" Vector__XXX
 SG_ DAS_disableMonarch m3 : 28|1@1+ (1,0) [0|1] "" Vector__XXX

BO_ 1548 DAS_telemetryRadar: 8 DAS
 SG_ DAS_TR_ObjIndex M : 0|5@1+ (1,0) [0|31] "" Vector__XXX
 SG_ DAS_TR_Counter : 54|2@1+ (1,0) [0|3] "" Vector__XXX
 SG_ DAS_TR_Obj00_Class m0 : 5|3@1+ (1,0) [0|7] "" Vector__XXX
 SG_ DAS_TR_Obj00_Dx m0 : 8|10@1+ (0.15625,0) [0|159.84375] "m" Vector__XXX
 SG_ DAS_TR_Obj00_Dy m0 : 18|6@1+ (0.5,-15.5) [-15.5|16] "m" Vector__XXX
 SG_ DAS_TR_Obj00_Vx m0 : 24|8@1+ (0.5,-63.5) [-63.5|64] "m/s" Vector__XXX
 SG_ DAS_TR_Obj00_RCS m0 : 32|8@1+ (0.25,-14) [-14|49.75] "dB" Vector__XXX
 SG_ DAS_TR_Obj00_Length m0 : 40|6@1+ (0.125,0) [0|7.875] "m" Vector__XXX
 SG_ DAS_TR_Obj00_MovingState m0 : 46|2@1+ (1,0) [0|3] "" Vector__XXX
 SG_ DAS_TR_Obj00_Dz m0 : 48|6@1+ (0.25,-5) [-5|10.75] "m" Vector__XXX
 SG_ DAS_TR_Obj00_Exist m0 : 56|5@1+ (3.125,0) [0|96.875] "%" Vector__XXX

BO_ 1592 EPAS3P_udsResponseCH: 8 EPAS3P
 SG_ EPAS3P_udsResponseDataCH : 7|64@0+ (1,0) [0|1.84467440737e+19] "" Vector__XXX

BO_ 888 GTW_ECall: 1 GTW
 SG_ GTW_GTW_SOS_ECALL_RQST : 0|1@1+ (1,0) [0|1] "" Vector__XXX
 SG_ GTW_LTE_ECALL_LOCK : 1|1@1+ (1,0) [0|1] "" Vector__XXX

BO_ 282 GTW_adc4: 8 GTW
 SG_ GTW_BKP_BATT_MON : 7|12@0+ (1,0) [0|4094] "mV" Vector__XXX
 SG_ GTW_BKP_BATT_NTC_P : 11|12@0+ (1,0) [0|4094] "mV" Vector__XXX
 SG_ GTW_ECALL_GPS_ANT_BIAS : 31|12@0+ (1,0) [0|4094] "mV" Vector__XXX
 SG_ GTW_ECALL_MIC_DIAG : 35|12@0+ (1,0) [0|4094] "mV" Vector__XXX
 SG_ GTW_SOS_ECALL_nRQST_BUF : 55|12@0+ (1,0) [0|4094] "mV" Vector__XXX

BO_ 1384 GTW_alertLog: 8 GTW
 SG_ GTW_alertID M : 0|9@1+ (1,0) [0|511] "" Vector__XXX
 SG_ GTW_alertState : 15|1@1+ (1,0) [0|1] "" Vector__XXX
 SG_ GTW_a014_crcVersion m14 : 16|32@1+ (1,0) [0|4294967295] "" Vector__XXX
 SG_ GTW_a015_crcVersion m15 : 16|32@1+ (1,0) [0|4294967295] "" Vector__XXX
 SG_ GTW_a016_crcVersion m16 : 16|32@1+ (1,0) [0|4294967295] "" Vector__XXX
 SG_ GTW_a017_crcVersion m17 : 16|32@1+ (1,0) [0|4294967295] "" Vector__XXX
 SG_ GTW_a018_crcVersion m18 : 16|32@1+ (1,0) [0|4294967295] "" Vector__XXX
 SG_ GTW_a019_crcVersion m19 : 16|32@1+ (1,0) [0|4294967295] "" Vector__XXX
 SG_ GTW_a020_crcVersion m20 : 16|32@1+ (1,0) [0|4294967295] "" Vector__XXX
 SG_ GTW_a021_crcVersion m21 : 16|32@1+ (1,0) [0|4294967295] "" Vector__XXX
 SG_ GTW_a022_crcVersion m22 : 16|32@1+ (1,0) [0|4294967295] "" Vector__XXX
 SG_ GTW_a023_crcVersion m23 : 16|32@1+ (1,0) [0|4294967295] "" Vector__XXX
 SG_ GTW_a024_crcVersion m24 : 16|32@1+ (1,0) [0|4294967295] "" Vector__XXX
 SG_ GTW_a025_crcVersion m25 : 16|32@1+ (1,0) [0|4294967295] "" Vector__XXX
 SG_ GTW_a026_crcVersion m26 : 16|32@1+ (1,0) [0|4294967295] "" Vector__XXX
 SG_ GTW_a027_crcVersion m27 : 16|32@1+ (1,0) [0|4294967295] "" Vector__XXX
 SG_ GTW_a028_crcVersion m28 : 16|32@1+ (1,0) [0|4294967295] "" Vector__XXX
 SG_ GTW_a029_crcVersion m29 : 16|32@1+ (1,0) [0|4294967295] "" Vector__XXX
 SG_ GTW_a030_crcVersion m30 : 16|32@1+ (1,0) [0|4294967295] "" Vector__XXX
 SG_ GTW_a031_crcVersion m31 : 16|32@1+ (1,0) [0|4294967295] "" Vector__XXX
 SG_ GTW_a032_crcVersion m32 : 16|32@1+ (1,0) [0|4294967295] "" Vector__XXX
 SG_ GTW_a033_crcVersion m33 : 16|32@1+ (1,0) [0|4294967295] "" Vector__XXX
 SG_ GTW_a034_crcVersion m34 : 16|32@1+ (1,0) [0|4294967295] "" Vector__XXX
 SG_ GTW_a035_crcVersion m35 : 16|32@1+ (1,0) [0|4294967295] "" Vector__XXX
 SG_ GTW_a036_crcVersion m36 : 16|32@1+ (1,0) [0|4294967295] "" Vector__XXX
 SG_ GTW_a037_crcVersion m37 : 16|32@1+ (1,0) [0|4294967295] "" Vector__XXX
 SG_ GTW_a038_crcVersion m38 : 16|32@1+ (1,0) [0|4294967295] "" Vector__XXX
 SG_ GTW_a039_crcVersion m39 : 16|32@1+ (1,0) [0|4294967295] "" Vector__XXX
 SG_ GTW_a040_crcVersion m40 : 16|32@1+ (1,0) [0|4294967295] "" Vector__XXX
 SG_ GTW_a041_crcVersion m41 : 16|32@1+ (1,0) [0|4294967295] "" Vector__XXX
 SG_ GTW_a042_crcVersion m42 : 16|32@1+ (1,0) [0|4294967295] "" Vector__XXX
 SG_ GTW_a043_crcVersion m43 : 16|32@1+ (1,0) [0|4294967295] "" Vector__XXX
 SG_ GTW_a045_crcVersion m45 : 16|32@1+ (1,0) [0|4294967295] "" Vector__XXX
 SG_ GTW_a046_crcVersion m46 : 16|32@1+ (1,0) [0|4294967295] "" Vector__XXX
 SG_ GTW_a047_crcVersion m47 : 16|32@1+ (1,0) [0|4294967295] "" Vector__XXX
 SG_ GTW_a048_crcVersion m48 : 16|32@1+ (1,0) [0|4294967295] "" Vector__XXX
 SG_ GTW_a049_headerError m49 : 16|2@1+ (1,0) [0|3] "" Vector__XXX
 SG_ GTW_a054_crcVersion m54 : 16|32@1+ (1,0) [0|4294967295] "" Vector__XXX
 SG_ GTW_a055_crcVersion m55 : 16|32@1+ (1,0) [0|4294967295] "" Vector__XXX
 SG_ GTW_a062_bmpWatchdogReason m62 : 16|3@1+ (1,0) [0|7] "" Vector__XXX
 SG_ GTW_a063_VEH_faultConfinement m63 : 16|2@1+ (1,0) [0|3] "" Vector__XXX
 SG_ GTW_a064_CH_faultConfinement m64 : 16|2@1+ (1,0) [0|3] "" Vector__XXX
 SG_ GTW_a065_PARTY_faultConfinement m65 : 16|2@1+ (1,0) [0|3] "" Vector__XXX
 SG_ GTW_a066_type m66 : 16|5@1+ (1,0) [0|31] "" Vector__XXX
 SG_ GTW_a066_exceptionCfgId m66 : 21|8@1+ (1,0) [0|255] "" Vector__XXX
 SG_ GTW_a066_uptime m66 : 29|32@1+ (1,0) [0|4294967295] "" Vector__XXX
 SG_ GTW_a066_core m66 : 61|3@1+ (1,0) [0|7] "" Vector__XXX
 SG_ GTW_a068_codeKeyMissing m68 : 16|1@1+ (1,0) [0|1] "" Vector__XXX
 SG_ GTW_a068_cmdKeyMissing m68 : 17|1@1+ (1,0) [0|1] "" Vector__XXX
 SG_ GTW_a069_sdIntStatusErrs m69 : 16|1@1+ (1,0) [0|1] "" Vector__XXX
 SG_ GTW_a069_sdTimeout m69 : 17|1@1+ (1,0) [0|1] "" Vector__XXX
 SG_ GTW_a069_sdCmdErr m69 : 18|1@1+ (1,0) [0|1] "" Vector__XXX
 SG_ GTW_a069_sdWriteErr m69 : 19|1@1+ (1,0) [0|1] "" Vector__XXX
 SG_ GTW_a069_sdReadErr m69 : 20|1@1+ (1,0) [0|1] "" Vector__XXX
 SG_ GTW_a069_autoCmd12Err m69 : 21|1@1+ (1,0) [0|1] "" Vector__XXX
 SG_ GTW_a072_updtFailureMask m72 : 16|32@1+ (1,0) [0|4294967295] "" Vector__XXX
 SG_ GTW_a073_SOCResetRequestor m73 : 16|3@1+ (1,0) [0|7] "" Vector__XXX
 SG_ GTW_a077_bmpPmicErrorType m77 : 16|3@1+ (1,0) [0|7] "" Vector__XXX
 SG_ GTW_a097_crcVersion m97 : 16|32@1+ (1,0) [0|4294967295] "" Vector__XXX
 SG_ GTW_a098_crcVersion m98 : 16|32@1+ (1,0) [0|4294967295] "" Vector__XXX
 SG_ GTW_a099_crcVersion m99 : 16|32@1+ (1,0) [0|4294967295] "" Vector__XXX
 SG_ GTW_a100_crcVersion m100 : 16|32@1+ (1,0) [0|4294967295] "" Vector__XXX
 SG_ GTW_a101_switchStuck m101 : 16|1@1+ (1,0) [0|1] "" Vector__XXX
 SG_ GTW_a101_ETH_SW_nINT m101 : 17|1@1+ (1,0) [0|1] "" Vector__XXX
 SG_ GTW_a106_crcVersion m106 : 16|32@1+ (1,0) [0|4294967295] "" Vector__XXX
 SG_ GTW_a107_crcVersion m107 : 16|32@1+ (1,0) [0|4294967295] "" Vector__XXX
 SG_ GTW_a108_crcVersion m108 : 16|32@1+ (1,0) [0|4294967295] "" Vector__XXX
 SG_ GTW_a117_MC_RGM_DES m117 : 16|32@1+ (1,0) [0|4294967295] "" Vector__XXX
 SG_ GTW_a118_MC_RGM_FES m118 : 16|32@1+ (1,0) [0|4294967295] "" Vector__XXX
 SG_ GTW_a122_BDY_faultConfinement m122 : 16|2@1+ (1,0) [0|3] "" Vector__XXX
 SG_ GTW_a129_crcVersion m129 : 16|32@1+ (1,0) [0|4294967295] "" Vector__XXX
 SG_ GTW_a138_sdLifetimeUsed m138 : 16|8@1+ (1,0) [0|255] "" Vector__XXX
 SG_ GTW_a139_crcVersion m139 : 16|32@1+ (1,0) [0|4294967295] "" Vector__XXX
 SG_ GTW_a150_crcVersion m150 : 16|32@1+ (1,0) [0|4294967295] "" Vector__XXX
 SG_ GTW_a151_crcVersion m151 : 16|32@1+ (1,0) [0|4294967295] "" Vector__XXX
 SG_ GTW_a155_crcVersion m155 : 16|32@1+ (1,0) [0|4294967295] "" Vector__XXX
 SG_ GTW_a164_crcVersion m164 : 16|32@1+ (1,0) [0|4294967295] "" Vector__XXX
 SG_ GTW_a165_crcVersion m165 : 16|32@1+ (1,0) [0|4294967295] "" Vector__XXX
 SG_ GTW_a169_TPMS_pressureFL m169 : 16|8@1+ (1,0) [0|255] "" Vector__XXX
 SG_ GTW_a170_TPMS_pressureFR m170 : 16|8@1+ (1,0) [0|255] "" Vector__XXX
 SG_ GTW_a171_TPMS_pressureRL m171 : 16|8@1+ (1,0) [0|255] "" Vector__XXX
 SG_ GTW_a172_TPMS_pressureRR m172 : 16|8@1+ (1,0) [0|255] "" Vector__XXX
 SG_ GTW_a173_TPMS_pressureFL m173 : 16|8@1+ (1,0) [0|255] "" Vector__XXX
 SG_ GTW_a174_TPMS_pressureFR m174 : 16|8@1+ (1,0) [0|255] "" Vector__XXX
 SG_ GTW_a175_TPMS_pressureRL m175 : 16|8@1+ (1,0) [0|255] "" Vector__XXX
 SG_ GTW_a176_TPMS_pressureRR m176 : 16|8@1+ (1,0) [0|255] "" Vector__XXX
 SG_ GTW_a219_crcVersion m219 : 16|32@1+ (1,0) [0|4294967295] "" Vector__XXX
 SG_ GTW_a223_crcVersion m223 : 16|32@1+ (1,0) [0|4294967295] "" Vector__XXX
 SG_ GTW_a226_crcVersion m226 : 16|32@1+ (1,0) [0|4294967295] "" Vector__XXX
 SG_ GTW_a227_crcVersion m227 : 16|32@1+ (1,0) [0|4294967295] "" Vector__XXX
 SG_ GTW_a228_crcVersion m228 : 16|32@1+ (1,0) [0|4294967295] "" Vector__XXX
 SG_ GTW_a244_crcVersion m244 : 16|32@1+ (1,0) [0|4294967295] "" Vector__XXX
 SG_ GTW_a245_page0ControlValue m245 : 16|16@1+ (1,0) [0|65535] "" Vector__XXX
 SG_ GTW_a245_page1ControlValue m245 : 32|16@1+ (1,0) [0|65535] "" Vector__XXX
 SG_ GTW_a261_failureReason m261 : 16|3@1+ (1,0) [0|7] "" Vector__XXX
 SG_ GTW_a261_failureData1 m261 : 24|16@1+ (1,0) [0|65535] "" Vector__XXX
 SG_ GTW_a261_failureData2 m261 : 40|16@1+ (1,0) [0|65535] "" Vector__XXX
 SG_ GTW_a273_crcVersion m273 : 16|32@1+ (1,0) [0|4294967295] "" Vector__XXX
 SG_ GTW_a274_crcVersion m274 : 16|32@1+ (1,0) [0|4294967295] "" Vector__XXX
 SG_ GTW_a277_mitigationFailureReason m277 : 16|3@1+ (1,0) [0|7] "" Vector__XXX
 SG_ GTW_a279_repeatCount m279 : 16|8@1+ (1,0) [0|255] "" Vector__XXX
 SG_ GTW_a279_failureReason m279 : 24|3@1+ (1,0) [0|7] "" Vector__XXX
 SG_ GTW_a279_failureData1 m279 : 32|16@1+ (1,0) [0|65535] "" Vector__XXX
 SG_ GTW_a279_failureData2 m279 : 48|16@1+ (1,0) [0|65535] "" Vector__XXX
 SG_ GTW_a309_crcVersion m309 : 16|32@1+ (1,0) [0|4294967295] "" Vector__XXX
 SG_ GTW_a317_status m317 : 16|3@1+ (1,0) [0|7] "" Vector__XXX
 SG_ GTW_a317_errorCode m317 : 19|5@1+ (1,0) [0|31] "" Vector__XXX
 SG_ GTW_a329_crcVersion m329 : 16|32@1+ (1,0) [0|4294967295] "" Vector__XXX
 SG_ GTW_a330_crcVersion m330 : 16|32@1+ (1,0) [0|4294967295] "" Vector__XXX
 SG_ GTW_a331_crcVersion m331 : 16|32@1+ (1,0) [0|4294967295] "" Vector__XXX
 SG_ GTW_a342_crcVersion m342 : 16|32@1+ (1,0) [0|4294967295] "" Vector__XXX
 SG_ GTW_a348_crcVersion m348 : 16|32@1+ (1,0) [0|4294967295] "" Vector__XXX
 SG_ GTW_a349_crcVersion m349 : 16|32@1+ (1,0) [0|4294967295] "" Vector__XXX
 SG_ GTW_a354_crcVersion m354 : 16|32@1+ (1,0) [0|4294967295] "" Vector__XXX
 SG_ GTW_a355_crcVersion m355 : 16|32@1+ (1,0) [0|4294967295] "" Vector__XXX
 SG_ GTW_a358_crcVersion m358 : 16|32@1+ (1,0) [0|4294967295] "" Vector__XXX
 SG_ GTW_a359_crcVersion m359 : 16|32@1+ (1,0) [0|4294967295] "" Vector__XXX
 SG_ GTW_a360_crcVersion m360 : 16|32@1+ (1,0) [0|4294967295] "" Vector__XXX
 SG_ GTW_a361_crcVersion m361 : 16|32@1+ (1,0) [0|4294967295] "" Vector__XXX
 SG_ GTW_a362_crcVersion m362 : 16|32@1+ (1,0) [0|4294967295] "" Vector__XXX
 SG_ GTW_a363_crcVersion m363 : 16|32@1+ (1,0) [0|4294967295] "" Vector__XXX
 SG_ GTW_a364_crcVersion m364 : 16|32@1+ (1,0) [0|4294967295] "" Vector__XXX
 SG_ GTW_a380_crcVersion m380 : 16|32@1+ (1,0) [0|4294967295] "" Vector__XXX
 SG_ GTW_a381_crcVersion m381 : 16|32@1+ (1,0) [0|4294967295] "" Vector__XXX
 SG_ GTW_a382_crcVersion m382 : 16|32@1+ (1,0) [0|4294967295] "" Vector__XXX
 SG_ GTW_a383_crcVersion m383 : 16|32@1+ (1,0) [0|4294967295] "" Vector__XXX
 SG_ GTW_a384_crcVersion m384 : 16|32@1+ (1,0) [0|4294967295] "" Vector__XXX
 SG_ GTW_a385_crcVersion m385 : 16|32@1+ (1,0) [0|4294967295] "" Vector__XXX
 SG_ GTW_a386_crcVersion m386 : 16|32@1+ (1,0) [0|4294967295] "" Vector__XXX
 SG_ GTW_a394_crcVersion m394 : 16|32@1+ (1,0) [0|4294967295] "" Vector__XXX
 SG_ GTW_a401_crcVersion m401 : 16|32@1+ (1,0) [0|4294967295] "" Vector__XXX
 SG_ GTW_a402_crcVersion m402 : 16|32@1+ (1,0) [0|4294967295] "" Vector__XXX
 SG_ GTW_a409_RES_CAUSE m409 : 16|32@1+ (1,0) [0|4294967295] "" Vector__XXX
 SG_ GTW_a410_RES_CAUSE2 m410 : 16|32@1+ (1,0) [0|4294967295] "" Vector__XXX
 SG_ GTW_a418_crcVersion m418 : 16|32@1+ (1,0) [0|4294967295] "" Vector__XXX
 SG_ GTW_a427_crcVersion m427 : 16|32@1+ (1,0) [0|4294967295] "" Vector__XXX
 SG_ GTW_a428_crcVersion m428 : 16|32@1+ (1,0) [0|4294967295] "" Vector__XXX
 SG_ GTW_a429_crcVersion m429 : 16|32@1+ (1,0) [0|4294967295] "" Vector__XXX
 SG_ GTW_a439_crcVersion m439 : 16|32@1+ (1,0) [0|4294967295] "" Vector__XXX

BO_ 62 GTW_alertMatrix: 8 GTW
 SG_ GTW_matrixIndex M : 0|4@1+ (1,0) [0|15] "" Vector__XXX
 SG_ GTW_w001_canEthTxQueue m0 : 4|1@1+ (1,0) [0|1] "" Vector__XXX
 SG_ GTW_w002_taskError m0 : 5|1@1+ (1,0) [0|1] "" Vector__XXX
 SG_ GTW_w003_logWriteRecord m0 : 6|1@1+ (1,0) [0|1] "" Vector__XXX
 SG_ GTW_w004_mallocHook m0 : 7|1@1+ (1,0) [0|1] "" Vector__XXX
 SG_ GTW_w005_stackOverflowHook m0 : 8|1@1+ (1,0) [0|1] "" Vector__XXX
 SG_ GTW_w006_ifTxOutputFull m0 : 9|1@1+ (1,0) [0|1] "" Vector__XXX
 SG_ GTW_w007_ifRxBufError m0 : 10|1@1+ (1,0) [0|1] "" Vector__XXX
 SG_ GTW_w008_ifPbufAllocError m0 : 11|1@1+ (1,0) [0|1] "" Vector__XXX
 SG_ GTW_w009_lateTask m0 : 12|1@1+ (1,0) [0|1] "" Vector__XXX
 SG_ GTW_w010_wdTaskCount m0 : 13|1@1+ (1,0) [0|1] "" Vector__XXX
 SG_ GTW_w011_cancoreWatchdog m0 : 14|1@1+ (1,0) [0|1] "" Vector__XXX
 SG_ GTW_w012_maincoreWatchdog m0 : 15|1@1+ (1,0) [0|1] "" Vector__XXX
 SG_ GTW_w014_APSversionMismatch m0 : 17|1@1+ (1,0) [0|1] "" Vector__XXX
 SG_ GTW_w015_DIFversionMismatch m0 : 18|1@1+ (1,0) [0|1] "" Vector__XXX
 SG_ GTW_w016_BLEEPCENTERversionMisma m0 : 19|1@1+ (1,0) [0|1] "" Vector__XXX
 SG_ GTW_w017_BMSversionMismatch m0 : 20|1@1+ (1,0) [0|1] "" Vector__XXX
 SG_ GTW_w018_CMPversionMismatch m0 : 21|1@1+ (1,0) [0|1] "" Vector__XXX
 SG_ GTW_w019_CPversionMismatch m0 : 22|1@1+ (1,0) [0|1] "" Vector__XXX
 SG_ GTW_w020_DIRversionMismatch m0 : 23|1@1+ (1,0) [0|1] "" Vector__XXX
 SG_ GTW_w021_EPAS3PversionMismatch m0 : 24|1@1+ (1,0) [0|1] "" Vector__XXX
 SG_ GTW_w022_EPBLversionMismatch m0 : 25|1@1+ (1,0) [0|1] "" Vector__XXX
 SG_ GTW_w023_EPBRversionMismatch m0 : 26|1@1+ (1,0) [0|1] "" Vector__XXX
 SG_ GTW_w024_ESPversionMismatch m0 : 27|1@1+ (1,0) [0|1] "" Vector__XXX
 SG_ GTW_w025_ESPCALversionMismatch m0 : 28|1@1+ (1,0) [0|1] "" Vector__XXX
 SG_ GTW_w026_GTWversionMismatch m0 : 29|1@1+ (1,0) [0|1] "" Vector__XXX
 SG_ GTW_w027_HVPversionMismatch m0 : 30|1@1+ (1,0) [0|1] "" Vector__XXX
 SG_ GTW_w028_IBSTversionMismatch m0 : 31|1@1+ (1,0) [0|1] "" Vector__XXX
 SG_ GTW_w029_IBSTCALversionMismatch m0 : 32|1@1+ (1,0) [0|1] "" Vector__XXX
 SG_ GTW_w030_OCS1PversionMismatch m0 : 33|1@1+ (1,0) [0|1] "" Vector__XXX
 SG_ GTW_w031_PARKversionMismatch m0 : 34|1@1+ (1,0) [0|1] "" Vector__XXX
 SG_ GTW_w032_PCSversionMismatch m0 : 35|1@1+ (1,0) [0|1] "" Vector__XXX
 SG_ GTW_w033_PCSCPU2versionMismatch m0 : 36|1@1+ (1,0) [0|1] "" Vector__XXX
 SG_ GTW_w034_PMRversionMismatch m0 : 37|1@1+ (1,0) [0|1] "" Vector__XXX
 SG_ GTW_w035_PMFversionMismatch m0 : 38|1@1+ (1,0) [0|1] "" Vector__XXX
 SG_ GTW_w036_PTCversionMismatch m0 : 39|1@1+ (1,0) [0|1] "" Vector__XXX
 SG_ GTW_w037_RADCversionMismatch m0 : 40|1@1+ (1,0) [0|1] "" Vector__XXX
 SG_ GTW_w038_RCMversionMismatch m0 : 41|1@1+ (1,0) [0|1] "" Vector__XXX
 SG_ GTW_w039_RCMCALversionMismatch m0 : 42|1@1+ (1,0) [0|1] "" Vector__XXX
 SG_ GTW_w040_SCCMversionMismatch m0 : 43|1@1+ (1,0) [0|1] "" Vector__XXX
 SG_ GTW_w041_VCSECversionMismatch m0 : 44|1@1+ (1,0) [0|1] "" Vector__XXX
 SG_ GTW_w042_TASversionMismatch m0 : 45|1@1+ (1,0) [0|1] "" Vector__XXX
 SG_ GTW_w043_THSversionMismatch m0 : 46|1@1+ (1,0) [0|1] "" Vector__XXX
 SG_ GTW_w045_VCFRONTversionMismatch m0 : 48|1@1+ (1,0) [0|1] "" Vector__XXX
 SG_ GTW_w046_VCLEFTversionMismatch m0 : 49|1@1+ (1,0) [0|1] "" Vector__XXX
 SG_ GTW_w047_VCRIGHTversionMismatch m0 : 50|1@1+ (1,0) [0|1] "" Vector__XXX
 SG_ GTW_w048_EPAS3SversionMismatch m0 : 51|1@1+ (1,0) [0|1] "" Vector__XXX
 SG_ GTW_w049_corruptedManifest m0 : 52|1@1+ (1,0) [0|1] "" Vector__XXX
 SG_ GTW_w050_sdCardInitFailure m0 : 53|1@1+ (1,0) [0|1] "" Vector__XXX
 SG_ GTW_w051_sdCardFileSystemFailure m0 : 54|1@1+ (1,0) [0|1] "" Vector__XXX
 SG_ GTW_w052_ifTxSpans m0 : 55|1@1+ (1,0) [0|1] "" Vector__XXX
 SG_ GTW_w053_busSleepFailure m0 : 56|1@1+ (1,0) [0|1] "" Vector__XXX
 SG_ GTW_w054_OPCRversionMismatch m0 : 57|1@1+ (1,0) [0|1] "" Vector__XXX
 SG_ GTW_w055_OPCFversionMismatch m0 : 58|1@1+ (1,0) [0|1] "" Vector__XXX
 SG_ GTW_w057_i2cFailure m0 : 60|1@1+ (1,0) [0|1] "" Vector__XXX
 SG_ GTW_w058_rtcAlarmFailure m0 : 61|1@1+ (1,0) [0|1] "" Vector__XXX
 SG_ GTW_w059_inFactoryMode m0 : 62|1@1+ (1,0) [0|1] "" Vector__XXX
 SG_ GTW_w060_unFused m0 : 63|1@1+ (1,0) [0|1] "" Vector__XXX
 SG_ GTW_w061_bmpSleepFailure m1 : 4|1@1+ (1,0) [0|1] "" Vector__XXX
 SG_ GTW_w062_bmpWatchdog m1 : 5|1@1+ (1,0) [0|1] "" Vector__XXX
 SG_ GTW_w063_VEH_canFault m1 : 6|1@1+ (1,0) [0|1] "" Vector__XXX
 SG_ GTW_w064_CH_canFault m1 : 7|1@1+ (1,0) [0|1] "" Vector__XXX
 SG_ GTW_w065_PARTY_canFault m1 : 8|1@1+ (1,0) [0|1] "" Vector__XXX
 SG_ GTW_w066_exception m1 : 9|1@1+ (1,0) [0|1] "" Vector__XXX
 SG_ GTW_w067_tcpDebug m1 : 10|1@1+ (1,0) [0|1] "" Vector__XXX
 SG_ GTW_w068_prodKeyMissing m1 : 11|1@1+ (1,0) [0|1] "" Vector__XXX
 SG_ GTW_w069_diskioErr m1 : 12|1@1+ (1,0) [0|1] "" Vector__XXX
 SG_ GTW_w070_hrlDump m1 : 13|1@1+ (1,0) [0|1] "" Vector__XXX
 SG_ GTW_w071_hrlTrigger m1 : 14|1@1+ (1,0) [0|1] "" Vector__XXX
 SG_ GTW_w072_updateFailure m1 : 15|1@1+ (1,0) [0|1] "" Vector__XXX
 SG_ GTW_w073_steeringWheelReset m1 : 16|1@1+ (1,0) [0|1] "" Vector__XXX
 SG_ GTW_w074_epas3pMIA m1 : 17|1@1+ (1,0) [0|1] "" Vector__XXX
 SG_ GTW_w075_epas3sMIA m1 : 18|1@1+ (1,0) [0|1] "" Vector__XXX
 SG_ GTW_w076_ethInterfaceReset m1 : 19|1@1+ (1,0) [0|1] "" Vector__XXX
 SG_ GTW_w077_bmpPmicError m1 : 20|1@1+ (1,0) [0|1] "" Vector__XXX
 SG_ GTW_w078_VEHbusOverloaded m1 : 21|1@1+ (1,0) [0|1] "" Vector__XXX
 SG_ GTW_w079_PARTYbusOverloaded m1 : 22|1@1+ (1,0) [0|1] "" Vector__XXX
 SG_ GTW_w080_CHbusOverloaded m1 : 23|1@1+ (1,0) [0|1] "" Vector__XXX
 SG_ GTW_w081_udsMessageRejected m1 : 24|1@1+ (1,0) [0|1] "" Vector__XXX
 SG_ GTW_w082_sdCardBSCorrupted m1 : 25|1@1+ (1,0) [0|1] "" Vector__XXX
 SG_ GTW_w083_udsMsgDroppedByTcpStack m1 : 26|1@1+ (1,0) [0|1] "" Vector__XXX
 SG_ GTW_w084_canFrameDropped m1 : 27|1@1+ (1,0) [0|1] "" Vector__XXX
 SG_ GTW_w085_fuseStateUnknown m1 : 28|1@1+ (1,0) [0|1] "" Vector__XXX
 SG_ GTW_w086_ocu m1 : 29|1@1+ (1,0) [0|1] "" Vector__XXX
 SG_ GTW_w087_ocuInProgress m1 : 30|1@1+ (1,0) [0|1] "" Vector__XXX
 SG_ GTW_w088_sdCardInvReqParallel m1 : 31|1@1+ (1,0) [0|1] "" Vector__XXX
 SG_ GTW_w089_sdCardWatchdog m1 : 32|1@1+ (1,0) [0|1] "" Vector__XXX
 SG_ GTW_w090_ocuFailed m1 : 33|1@1+ (1,0) [0|1] "" Vector__XXX
 SG_ GTW_w091_lowStack m1 : 34|1@1+ (1,0) [0|1] "" Vector__XXX
 SG_ GTW_w092_sdCardInvReqZero m1 : 35|1@1+ (1,0) [0|1] "" Vector__XXX
 SG_ GTW_w093_sdCardInvReqOverflowBas m1 : 36|1@1+ (1,0) [0|1] "" Vector__XXX
 SG_ GTW_w094_sdCardInvReqOverflowCou m1 : 37|1@1+ (1,0) [0|1] "" Vector__XXX
 SG_ GTW_w095_sdCardFull m1 : 38|1@1+ (1,0) [0|1] "" Vector__XXX
 SG_ GTW_w096_sdCardFatCorrupted m1 : 39|1@1+ (1,0) [0|1] "" Vector__XXX
 SG_ GTW_w097_HCMLversionMismatch m1 : 40|1@1+ (1,0) [0|1] "" Vector__XXX
 SG_ GTW_w098_HCMRversionMismatch m1 : 41|1@1+ (1,0) [0|1] "" Vector__XXX
 SG_ GTW_w099_SWCversionMismatch m1 : 42|1@1+ (1,0) [0|1] "" Vector__XXX
 SG_ GTW_w100_CBCversionMismatch m1 : 43|1@1+ (1,0) [0|1] "" Vector__XXX
 SG_ GTW_w101_switchWatchdog m1 : 44|1@1+ (1,0) [0|1] "" Vector__XXX
 SG_ GTW_w103_sdCardFormatted m1 : 46|1@1+ (1,0) [0|1] "" Vector__XXX
 SG_ GTW_w104_sdCardDriverArgCorrupte m1 : 47|1@1+ (1,0) [0|1] "" Vector__XXX
 SG_ GTW_w105_eBuckConfigured m1 : 48|1@1+ (1,0) [0|1] "" Vector__XXX
 SG_ GTW_w106_BLEEPLEFTversionMismatc m1 : 49|1@1+ (1,0) [0|1] "" Vector__XXX
 SG_ GTW_w107_BLEEPRIGHTversionMismat m1 : 50|1@1+ (1,0) [0|1] "" Vector__XXX
 SG_ GTW_w108_BLEEPREARversionMismatc m1 : 51|1@1+ (1,0) [0|1] "" Vector__XXX
 SG_ GTW_w109_failedToStartUpdater m1 : 52|1@1+ (1,0) [0|1] "" Vector__XXX
 SG_ GTW_w110_readMdioFailed m1 : 53|1@1+ (1,0) [0|1] "" Vector__XXX
 SG_ GTW_w111_writeMdioFailed m1 : 54|1@1+ (1,0) [0|1] "" Vector__XXX
 SG_ GTW_w112_z4bDisabled m1 : 55|1@1+ (1,0) [0|1] "" Vector__XXX
 SG_ GTW_w113_unrecognizedCanMessage m1 : 56|1@1+ (1,0) [0|1] "" Vector__XXX
 SG_ GTW_w114_updtRetried m1 : 57|1@1+ (1,0) [0|1] "" Vector__XXX
 SG_ GTW_w115_hrlEventFileAvail m1 : 58|1@1+ (1,0) [0|1] "" Vector__XXX
 SG_ GTW_w116_switchInitFailed m1 : 59|1@1+ (1,0) [0|1] "" Vector__XXX
 SG_ GTW_w117_unexpectedDestructiveRe m1 : 60|1@1+ (1,0) [0|1] "" Vector__XXX
 SG_ GTW_w118_unexpectedFunctionalRes m1 : 61|1@1+ (1,0) [0|1] "" Vector__XXX
 SG_ GTW_w120_switchUnlocked m1 : 63|1@1+ (1,0) [0|1] "" Vector__XXX
 SG_ GTW_w122_BDY_canFault m2 : 5|1@1+ (1,0) [0|1] "" Vector__XXX
 SG_ GTW_w123_BDYbusOverloaded m2 : 6|1@1+ (1,0) [0|1] "" Vector__XXX
 SG_ GTW_w125_switchReplayUnlocked m2 : 8|1@1+ (1,0) [0|1] "" Vector__XXX
 SG_ GTW_w127_noFilePointersAvailable m2 : 10|1@1+ (1,0) [0|1] "" Vector__XXX
 SG_ GTW_w129_ICRversionMismatch m2 : 12|1@1+ (1,0) [0|1] "" Vector__XXX
 SG_ GTW_w133_adspFaultDetected m2 : 16|1@1+ (1,0) [0|1] "" Vector__XXX
 SG_ GTW_w134_disableFeatureFailed m2 : 17|1@1+ (1,0) [0|1] "" Vector__XXX
 SG_ GTW_w135_canLogQueueFull m2 : 18|1@1+ (1,0) [0|1] "" Vector__XXX
 SG_ GTW_w136_hrlGameModeFileAvail m2 : 19|1@1+ (1,0) [0|1] "" Vector__XXX
 SG_ GTW_w137_lowHeap m2 : 20|1@1+ (1,0) [0|1] "" Vector__XXX
 SG_ GTW_w138_sdCardEndOfLife m2 : 21|1@1+ (1,0) [0|1] "" Vector__XXX
 SG_ GTW_w139_CMPDversionMismatch m2 : 22|1@1+ (1,0) [0|1] "" Vector__XXX
 SG_ GTW_w140_cancoreHeartbeat m2 : 23|1@1+ (1,0) [0|1] "" Vector__XXX
 SG_ GTW_w141_teleCANETHis m2 : 24|1@1+ (1,0) [0|1] "" Vector__XXX
 SG_ GTW_w143_possibleCanWakeIssue m2 : 26|1@1+ (1,0) [0|1] "" Vector__XXX
 SG_ GTW_w144_hrlStateMachine m2 : 27|1@1+ (1,0) [0|1] "" Vector__XXX
 SG_ GTW_w145_carConfigsNotWritten m2 : 28|1@1+ (1,0) [0|1] "" Vector__XXX
 SG_ GTW_w146_performancePackageMisma m2 : 29|1@1+ (1,0) [0|1] "" Vector__XXX
 SG_ GTW_w147_updateAbortFor12v m2 : 30|1@1+ (1,0) [0|1] "" Vector__XXX
 SG_ GTW_w149_rtcTimeSetInPast m2 : 32|1@1+ (1,0) [0|1] "" Vector__XXX
 SG_ GTW_w150_HCM3LversionMismatch m2 : 33|1@1+ (1,0) [0|1] "" Vector__XXX
 SG_ GTW_w151_HCM3RversionMismatch m2 : 34|1@1+ (1,0) [0|1] "" Vector__XXX
 SG_ GTW_w153_externalRtcAlarmFailure m2 : 36|1@1+ (1,0) [0|1] "" Vector__XXX
 SG_ GTW_w155_PMversionMismatch m2 : 38|1@1+ (1,0) [0|1] "" Vector__XXX
 SG_ GTW_w164_VCBATTversionMismatch m2 : 47|1@1+ (1,0) [0|1] "" Vector__XXX
 SG_ GTW_w165_USMversionMismatch m2 : 48|1@1+ (1,0) [0|1] "" Vector__XXX
 SG_ GTW_w166_nErrCanFaultVeh m2 : 49|1@1+ (1,0) [0|1] "" Vector__XXX
 SG_ GTW_w167_nErrCanFaultCh m2 : 50|1@1+ (1,0) [0|1] "" Vector__XXX
 SG_ GTW_w168_nErrCanFaultParty m2 : 51|1@1+ (1,0) [0|1] "" Vector__XXX
 SG_ GTW_w169_TPMSsoftWarnFrontLeft m2 : 52|1@1+ (1,0) [0|1] "" Vector__XXX
 SG_ GTW_w170_TPMSsoftWarnFrontRight m2 : 53|1@1+ (1,0) [0|1] "" Vector__XXX
 SG_ GTW_w171_TPMSsoftWarnRearLeft m2 : 54|1@1+ (1,0) [0|1] "" Vector__XXX
 SG_ GTW_w172_TPMSsoftWarnRearRight m2 : 55|1@1+ (1,0) [0|1] "" Vector__XXX
 SG_ GTW_w173_TPMShardWarnFrontLeft m2 : 56|1@1+ (1,0) [0|1] "" Vector__XXX
 SG_ GTW_w174_TPMShardWarnFrontRight m2 : 57|1@1+ (1,0) [0|1] "" Vector__XXX
 SG_ GTW_w175_TPMShardWarnRearLeft m2 : 58|1@1+ (1,0) [0|1] "" Vector__XXX
 SG_ GTW_w176_TPMShardWarnRearRight m2 : 59|1@1+ (1,0) [0|1] "" Vector__XXX
 SG_ GTW_w186_swrPrecaution m3 : 9|1@1+ (1,0) [0|1] "" Vector__XXX
 SG_ GTW_w218_switchOTPIncorrect m3 : 41|1@1+ (1,0) [0|1] "" Vector__XXX
 SG_ GTW_w219_CMPSversionMismatch m3 : 42|1@1+ (1,0) [0|1] "" Vector__XXX
 SG_ GTW_w223_LVBMSversionMismatch m3 : 46|1@1+ (1,0) [0|1] "" Vector__XXX
 SG_ GTW_w224_sdCardUpgradeNeeded m3 : 47|1@1+ (1,0) [0|1] "" Vector__XXX
 SG_ GTW_w225_resetOnSleepWake m3 : 48|1@1+ (1,0) [0|1] "" Vector__XXX
 SG_ GTW_w226_DISPversionMismatch m3 : 49|1@1+ (1,0) [0|1] "" Vector__XXX
 SG_ GTW_w227_DISPTOUCHversionMismatc m3 : 50|1@1+ (1,0) [0|1] "" Vector__XXX
 SG_ GTW_w228_DISPOSDversionMismatch m3 : 51|1@1+ (1,0) [0|1] "" Vector__XXX
 SG_ GTW_w229_displaySoftsetConnectio m3 : 52|1@1+ (1,0) [0|1] "" Vector__XXX
 SG_ GTW_w230_touchInterruptStorm m3 : 53|1@1+ (1,0) [0|1] "" Vector__XXX
 SG_ GTW_w244_SDCRversionMismatch m4 : 7|1@1+ (1,0) [0|1] "" Vector__XXX
 SG_ GTW_w245_apsNotDisabled m4 : 8|1@1+ (1,0) [0|1] "" Vector__XXX
 SG_ GTW_w246_touchcoreHeartbeat m4 : 9|1@1+ (1,0) [0|1] "" Vector__XXX
 SG_ GTW_w255_rtc32KHzWatchdog m4 : 18|1@1+ (1,0) [0|1] "" Vector__XXX
 SG_ GTW_w260_unknownPN m4 : 23|1@1+ (1,0) [0|1] "" Vector__XXX
 SG_ GTW_w261_adspWatchdog m4 : 24|1@1+ (1,0) [0|1] "" Vector__XXX
 SG_ GTW_w262_canLogBlockDropped m4 : 25|1@1+ (1,0) [0|1] "" Vector__XXX
 SG_ GTW_w263_hrlUdpFileAvail m4 : 26|1@1+ (1,0) [0|1] "" Vector__XXX
 SG_ GTW_w264_hrlPseudoFileAvail m4 : 27|1@1+ (1,0) [0|1] "" Vector__XXX
 SG_ GTW_w265_optionFlagsError m4 : 28|1@1+ (1,0) [0|1] "" Vector__XXX
 SG_ GTW_w266_dpp1MIA m4 : 29|1@1+ (1,0) [0|1] "" Vector__XXX
 SG_ GTW_w267_dpp2MIA m4 : 30|1@1+ (1,0) [0|1] "" Vector__XXX
 SG_ GTW_w268_stoMIA m4 : 31|1@1+ (1,0) [0|1] "" Vector__XXX
 SG_ GTW_w273_BLEEPREARLEFTversionMis m4 : 36|1@1+ (1,0) [0|1] "" Vector__XXX
 SG_ GTW_w274_BLEEPREARRIGHTversionMi m4 : 37|1@1+ (1,0) [0|1] "" Vector__XXX
 SG_ GTW_w275_VDDCORE_DrMOS_Fault m4 : 38|1@1+ (1,0) [0|1] "" Vector__XXX
 SG_ GTW_w276_VDDSOC_DrMOS_Fault m4 : 39|1@1+ (1,0) [0|1] "" Vector__XXX
 SG_ GTW_w277_NonRevCDrMOSMitigationF m4 : 40|1@1+ (1,0) [0|1] "" Vector__XXX
 SG_ GTW_w278_ethSwitchCongested m4 : 41|1@1+ (1,0) [0|1] "" Vector__XXX
 SG_ GTW_w279_adspRepeatedWatchdog m4 : 42|1@1+ (1,0) [0|1] "" Vector__XXX
 SG_ GTW_w280_hrlFrameDropped m4 : 43|1@1+ (1,0) [0|1] "" Vector__XXX
 SG_ GTW_w281_likelyMissedPoke m4 : 44|1@1+ (1,0) [0|1] "" Vector__XXX
 SG_ GTW_w282_tcuPhyConfigurationFail m4 : 45|1@1+ (1,0) [0|1] "" Vector__XXX
 SG_ GTW_w309_VCUSBversionMismatch m5 : 12|1@1+ (1,0) [0|1] "" Vector__XXX
 SG_ GTW_w311_canLogQueueFullBeforeFs m5 : 14|1@1+ (1,0) [0|1] "" Vector__XXX
 SG_ GTW_w312_hrlFileIncomplete m5 : 15|1@1+ (1,0) [0|1] "" Vector__XXX
 SG_ GTW_w313_OSDActive m5 : 16|1@1+ (1,0) [0|1] "" Vector__XXX
 SG_ GTW_w314_canLogBlockWriteErr m5 : 17|1@1+ (1,0) [0|1] "" Vector__XXX
 SG_ GTW_w316_sdCardChkdskRepair m5 : 19|1@1+ (1,0) [0|1] "" Vector__XXX
 SG_ GTW_w317_sdCardChkdskRepairFaile m5 : 20|1@1+ (1,0) [0|1] "" Vector__XXX
 SG_ GTW_w322_gestureUnrecognizedFrom m5 : 25|1@1+ (1,0) [0|1] "" Vector__XXX
 SG_ GTW_w323_gestureStartOutOfStrip m5 : 26|1@1+ (1,0) [0|1] "" Vector__XXX
 SG_ GTW_w328_smartShiftDisabled m5 : 31|1@1+ (1,0) [0|1] "" Vector__XXX
 SG_ GTW_w329_FOHMversionMismatch m5 : 32|1@1+ (1,0) [0|1] "" Vector__XXX
 SG_ GTW_w330_SWSLversionMismatch m5 : 33|1@1+ (1,0) [0|1] "" Vector__XXX
 SG_ GTW_w331_SWSRversionMismatch m5 : 34|1@1+ (1,0) [0|1] "" Vector__XXX
 SG_ GTW_w332_unknownDisplayPN m5 : 35|1@1+ (1,0) [0|1] "" Vector__XXX
 SG_ GTW_w334_hrlFolderSpaceLow m5 : 37|1@1+ (1,0) [0|1] "" Vector__XXX
 SG_ GTW_w336_possibleCanTxIssue m5 : 39|1@1+ (1,0) [0|1] "" Vector__XXX
 SG_ GTW_w342_VCBLDCPPversionMismatch m5 : 45|1@1+ (1,0) [0|1] "" Vector__XXX
 SG_ GTW_w348_VCBLDCFversionMismatch m5 : 51|1@1+ (1,0) [0|1] "" Vector__XXX
 SG_ GTW_w349_VCBLDCPBversionMismatch m5 : 52|1@1+ (1,0) [0|1] "" Vector__XXX
 SG_ GTW_w350_mOSDCrcCheck m5 : 53|1@1+ (1,0) [0|1] "" Vector__XXX
 SG_ GTW_w351_sOSDCrcCheck m5 : 54|1@1+ (1,0) [0|1] "" Vector__XXX
 SG_ GTW_w352_mASILStatusCheck m5 : 55|1@1+ (1,0) [0|1] "" Vector__XXX
 SG_ GTW_w353_sASILStatusCheck m5 : 56|1@1+ (1,0) [0|1] "" Vector__XXX
 SG_ GTW_w354_EPASTPversionMismatch m5 : 57|1@1+ (1,0) [0|1] "" Vector__XXX
 SG_ GTW_w355_EPASTSversionMismatch m5 : 58|1@1+ (1,0) [0|1] "" Vector__XXX
 SG_ GTW_w356_touchGPIOStatusCheck m5 : 59|1@1+ (1,0) [0|1] "" Vector__XXX
 SG_ GTW_w358_RGBIPFLversionMismatch m5 : 61|1@1+ (1,0) [0|1] "" Vector__XXX
 SG_ GTW_w359_RGBIPFRversionMismatch m5 : 62|1@1+ (1,0) [0|1] "" Vector__XXX
 SG_ GTW_w360_RGBDOORFLversionMismatc m5 : 63|1@1+ (1,0) [0|1] "" Vector__XXX
 SG_ GTW_w361_RGBDOORRLversionMismatc m6 : 4|1@1+ (1,0) [0|1] "" Vector__XXX
 SG_ GTW_w362_RGBDOORFRversionMismatc m6 : 5|1@1+ (1,0) [0|1] "" Vector__XXX
 SG_ GTW_w363_RGBDOORRRversionMismatc m6 : 6|1@1+ (1,0) [0|1] "" Vector__XXX
 SG_ GTW_w364_BLEEPCRADLEversionMisma m6 : 7|1@1+ (1,0) [0|1] "" Vector__XXX
 SG_ GTW_w366_uiGearRequestMismatch m6 : 9|1@1+ (1,0) [0|1] "" Vector__XXX
 SG_ GTW_w376_blFailedToExecBootImg m6 : 19|1@1+ (1,0) [0|1] "" Vector__XXX
 SG_ GTW_w380_DPBversionMismatch m6 : 23|1@1+ (1,0) [0|1] "" Vector__XXX
 SG_ GTW_w381_DPBCALversionMismatch m6 : 24|1@1+ (1,0) [0|1] "" Vector__XXX
 SG_ GTW_w382_IDBversionMismatch m6 : 25|1@1+ (1,0) [0|1] "" Vector__XXX
 SG_ GTW_w383_IDB1versionMismatch m6 : 26|1@1+ (1,0) [0|1] "" Vector__XXX
 SG_ GTW_w384_IDBCALversionMismatch m6 : 27|1@1+ (1,0) [0|1] "" Vector__XXX
 SG_ GTW_w385_RCUversionMismatch m6 : 28|1@1+ (1,0) [0|1] "" Vector__XXX
 SG_ GTW_w386_RCUCALversionMismatch m6 : 29|1@1+ (1,0) [0|1] "" Vector__XXX
 SG_ GTW_w387_externalRtcReadFailure m6 : 30|1@1+ (1,0) [0|1] "" Vector__XXX
 SG_ GTW_w388_adspWatchdogSkipped m6 : 31|1@1+ (1,0) [0|1] "" Vector__XXX
 SG_ GTW_w389_rcmEventDetected m6 : 32|1@1+ (1,0) [0|1] "" Vector__XXX
 SG_ GTW_w390_displayFwQueryFailed m6 : 33|1@1+ (1,0) [0|1] "" Vector__XXX
 SG_ GTW_w391_adspMacAddrCheckFailed m6 : 34|1@1+ (1,0) [0|1] "" Vector__XXX
 SG_ GTW_w393_osdSramCrcMismatch m6 : 36|1@1+ (1,0) [0|1] "" Vector__XXX
 SG_ GTW_w394_WIPERversionMismatch m6 : 37|1@1+ (1,0) [0|1] "" Vector__XXX
 SG_ GTW_w395_lwipIcmpError m6 : 38|1@1+ (1,0) [0|1] "" Vector__XXX
 SG_ GTW_w396_alreadyInReverse m6 : 39|1@1+ (1,0) [0|1] "" Vector__XXX
 SG_ GTW_w397_alreadyInDrive m6 : 40|1@1+ (1,0) [0|1] "" Vector__XXX
 SG_ GTW_w398_awakeForExtendedTime m6 : 41|1@1+ (1,0) [0|1] "" Vector__XXX
 SG_ GTW_w399_ethIfRxTcpipQueueDrop m6 : 42|1@1+ (1,0) [0|1] "" Vector__XXX
 SG_ GTW_w400_ethlSwitchOTPIncorrect m6 : 43|1@1+ (1,0) [0|1] "" Vector__XXX
 SG_ GTW_w401_VCSEAT2LversionMismatch m6 : 44|1@1+ (1,0) [0|1] "" Vector__XXX
 SG_ GTW_w402_VCSEAT2RversionMismatch m6 : 45|1@1+ (1,0) [0|1] "" Vector__XXX
 SG_ GTW_w409_unexpectedResetCause m6 : 52|1@1+ (1,0) [0|1] "" Vector__XXX
 SG_ GTW_w410_unexpectedResetCause2 m6 : 53|1@1+ (1,0) [0|1] "" Vector__XXX
 SG_ GTW_w411_tASILStatusCheck m6 : 54|1@1+ (1,0) [0|1] "" Vector__XXX
 SG_ GTW_w414_socHeldInReset m6 : 57|1@1+ (1,0) [0|1] "" Vector__XXX
 SG_ GTW_w418_TRCMversionMismatch m6 : 61|1@1+ (1,0) [0|1] "" Vector__XXX
 SG_ GTW_w420_unexpectedCanMessageLen m6 : 63|1@1+ (1,0) [0|1] "" Vector__XXX
 SG_ GTW_w421_ModemEthLinkDown m7 : 4|1@1+ (1,0) [0|1] "" Vector__XXX
 SG_ GTW_w422_ethSwitchSevereCongesti m7 : 5|1@1+ (1,0) [0|1] "" Vector__XXX
 SG_ GTW_w427_DISPBRIDGEversionMismat m7 : 10|1@1+ (1,0) [0|1] "" Vector__XXX
 SG_ GTW_w428_LUMBAR32LversionMismatc m7 : 11|1@1+ (1,0) [0|1] "" Vector__XXX
 SG_ GTW_w429_LUMBAR32RversionMismatc m7 : 12|1@1+ (1,0) [0|1] "" Vector__XXX
 SG_ GTW_w436_possibleCanRxIssue m7 : 19|1@1+ (1,0) [0|1] "" Vector__XXX
 SG_ GTW_w437_softFlowControlNotRunni m7 : 20|1@1+ (1,0) [0|1] "" Vector__XXX
 SG_ GTW_w438_wakeSourceUnknown m7 : 21|1@1+ (1,0) [0|1] "" Vector__XXX
 SG_ GTW_w439_VCCCversionMismatch m7 : 22|1@1+ (1,0) [0|1] "" Vector__XXX
 SG_ GTW_w450_unexpectedAutopilotCont m7 : 33|1@1+ (1,0) [0|1] "" Vector__XXX
 SG_ GTW_w451_diagCanBufferExhausted m7 : 34|1@1+ (1,0) [0|1] "" Vector__XXX
 SG_ GTW_w452_diagCanStaleSocket m7 : 35|1@1+ (1,0) [0|1] "" Vector__XXX
 SG_ GTW_w453_diagCanFdSetDesync m7 : 36|1@1+ (1,0) [0|1] "" Vector__XXX
 SG_ GTW_w454_diagCanFrameOverread m7 : 37|1@1+ (1,0) [0|1] "" Vector__XXX
 SG_ GTW_w455_hrlDumpPageOwnershipErr m7 : 38|1@1+ (1,0) [0|1] "" Vector__XXX
 SG_ GTW_w456_hrlStateMachinePageOwne m7 : 39|1@1+ (1,0) [0|1] "" Vector__XXX
 SG_ GTW_w463_displayEdidReadFailed m7 : 46|1@1+ (1,0) [0|1] "" Vector__XXX
 SG_ GTW_w469_backlightFsmUnhealthy m7 : 52|1@1+ (1,0) [0|1] "" Vector__XXX

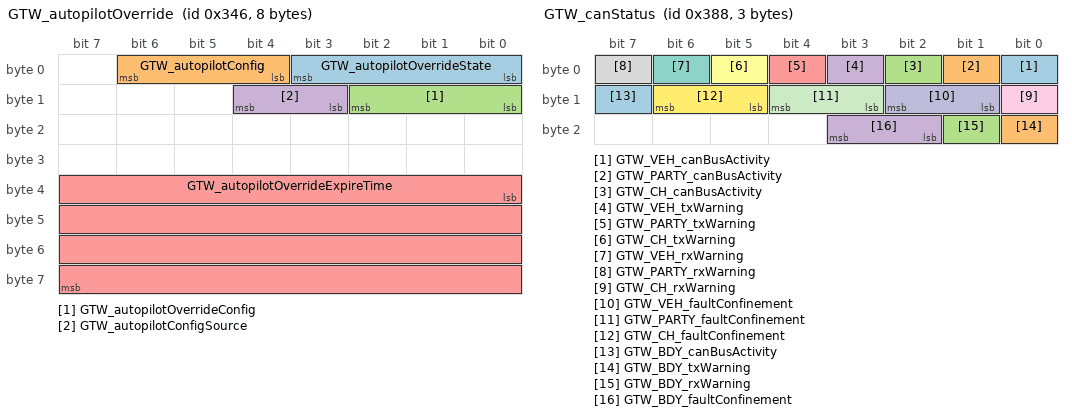
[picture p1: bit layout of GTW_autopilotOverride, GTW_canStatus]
BO_ 838 GTW_autopilotOverride: 8 GTW
 SG_ GTW_autopilotOverrideState : 0|4@1+ (1,0) [0|15] "" Vector__XXX
 SG_ GTW_autopilotConfig : 4|3@1+ (1,0) [0|7] "" Vector__XXX
 SG_ GTW_autopilotOverrideConfig : 8|3@1+ (1,0) [0|7] "" Vector__XXX
 SG_ GTW_autopilotConfigSource : 11|2@1+ (1,0) [0|3] "" Vector__XXX
 SG_ GTW_autopilotOverrideExpireTime : 32|32@1+ (1,0) [0|4294967295] "" Vector__XXX

BO_ 904 GTW_canStatus: 3 GTW
 SG_ GTW_VEH_canBusActivity : 0|1@1+ (1,0) [0|1] "" Vector__XXX
 SG_ GTW_PARTY_canBusActivity : 1|1@1+ (1,0) [0|1] "" Vector__XXX
 SG_ GTW_CH_canBusActivity : 2|1@1+ (1,0) [0|1] "" Vector__XXX
 SG_ GTW_VEH_txWarning : 3|1@1+ (1,0) [0|1] "" Vector__XXX
 SG_ GTW_PARTY_txWarning : 4|1@1+ (1,0) [0|1] "" Vector__XXX
 SG_ GTW_CH_txWarning : 5|1@1+ (1,0) [0|1] "" Vector__XXX
 SG_ GTW_VEH_rxWarning : 6|1@1+ (1,0) [0|1] "" Vector__XXX
 SG_ GTW_PARTY_rxWarning : 7|1@1+ (1,0) [0|1] "" Vector__XXX
 SG_ GTW_CH_rxWarning : 8|1@1+ (1,0) [0|1] "" Vector__XXX
 SG_ GTW_VEH_faultConfinement : 9|2@1+ (1,0) [0|3] "" Vector__XXX
 SG_ GTW_PARTY_faultConfinement : 11|2@1+ (1,0) [0|3] "" Vector__XXX
 SG_ GTW_CH_faultConfinement : 13|2@1+ (1,0) [0|3] "" Vector__XXX
 SG_ GTW_BDY_canBusActivity : 15|1@1+ (1,0) [0|1] "" Vector__XXX
 SG_ GTW_BDY_txWarning : 16|1@1+ (1,0) [0|1] "" Vector__XXX
 SG_ GTW_BDY_rxWarning : 17|1@1+ (1,0) [0|1] "" Vector__XXX
 SG_ GTW_BDY_faultConfinement : 18|2@1+ (1,0) [0|3] "" Vector__XXX

BO_ 792 GTW_carState: 8 GTW
 SG_ GTW_factoryGated : 48|1@1+ (1,0) [0|1] "" Vector__XXX

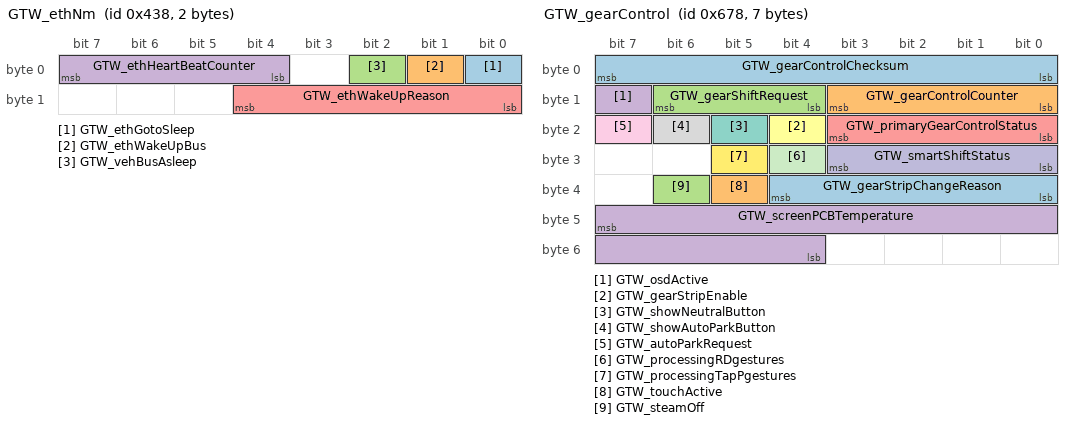
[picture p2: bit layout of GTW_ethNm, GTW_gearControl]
BO_ 1080 GTW_ethNm: 2 GTW
 SG_ GTW_ethGotoSleep : 0|1@1+ (1,0) [0|1] "" Vector__XXX
 SG_ GTW_ethWakeUpBus : 1|1@1+ (1,0) [0|1] "" Vector__XXX
 SG_ GTW_vehBusAsleep : 2|1@1+ (1,0) [0|1] "" Vector__XXX
 SG_ GTW_ethHeartBeatCounter : 4|4@1+ (1,0) [0|15] "" Vector__XXX
 SG_ GTW_ethWakeUpReason : 8|5@1+ (1,0) [0|31] "" Vector__XXX

BO_ 1376 GTW_factoryEcuPresent: 4 GTW
 SG_ GTW_OCS1Ppresent : 0|1@1+ (1,0) [0|1] "" Vector__XXX
 SG_ GTW_PCSpresent : 1|1@1+ (1,0) [0|1] "" Vector__XXX
 SG_ GTW_HVPpresent : 2|1@1+ (1,0) [0|1] "" Vector__XXX
 SG_ GTW_BMSpresent : 3|1@1+ (1,0) [0|1] "" Vector__XXX
 SG_ GTW_CPpresent : 4|1@1+ (1,0) [0|1] "" Vector__XXX
 SG_ GTW_RCMpresent : 5|1@1+ (1,0) [0|1] "" Vector__XXX
 SG_ GTW_SCCMpresent : 6|1@1+ (1,0) [0|1] "" Vector__XXX
 SG_ GTW_VCSECpresent : 7|1@1+ (1,0) [0|1] "" Vector__XXX
 SG_ GTW_EPAS3Ppresent : 8|1@1+ (1,0) [0|1] "" Vector__XXX
 SG_ GTW_EPBLpresent : 9|1@1+ (1,0) [0|1] "" Vector__XXX
 SG_ GTW_EPBRpresent : 10|1@1+ (1,0) [0|1] "" Vector__XXX
 SG_ GTW_ESPpresent : 11|1@1+ (1,0) [0|1] "" Vector__XXX
 SG_ GTW_IBSTpresent : 12|1@1+ (1,0) [0|1] "" Vector__XXX
 SG_ GTW_PARKpresent : 13|1@1+ (1,0) [0|1] "" Vector__XXX
 SG_ GTW_RADCpresent : 14|1@1+ (1,0) [0|1] "" Vector__XXX
 SG_ GTW_TPMSpresent : 15|1@1+ (1,0) [0|1] "" Vector__XXX
 SG_ GTW_VCFRONTpresent : 16|1@1+ (1,0) [0|1] "" Vector__XXX
 SG_ GTW_VCLEFTpresent : 17|1@1+ (1,0) [0|1] "" Vector__XXX
 SG_ GTW_VCRIGHTpresent : 18|1@1+ (1,0) [0|1] "" Vector__XXX
 SG_ GTW_EPAS3Spresent : 19|1@1+ (1,0) [0|1] "" Vector__XXX
 SG_ GTW_CMPpresent : 20|1@1+ (1,0) [0|1] "" Vector__XXX
 SG_ GTW_DASpresent : 21|1@1+ (1,0) [0|1] "" Vector__XXX
 SG_ GTW_PTCpresent : 22|1@1+ (1,0) [0|1] "" Vector__XXX
 SG_ GTW_SWCpresent : 23|1@1+ (1,0) [0|1] "" Vector__XXX
 SG_ GTW_PMRpresent : 25|1@1+ (1,0) [0|1] "" Vector__XXX
 SG_ GTW_PMFpresent : 26|1@1+ (1,0) [0|1] "" Vector__XXX
 SG_ GTW_DIRpresent : 27|1@1+ (1,0) [0|1] "" Vector__XXX
 SG_ GTW_DIFpresent : 28|1@1+ (1,0) [0|1] "" Vector__XXX

BO_ 1656 GTW_gearControl: 7 GTW
 SG_ GTW_gearControlChecksum : 0|8@1+ (1,0) [0|255] "" Vector__XXX
 SG_ GTW_gearControlCounter : 8|4@1+ (1,0) [0|15] "" Vector__XXX
 SG_ GTW_gearShiftRequest : 12|3@1+ (1,0) [1|7] "" Vector__XXX
 SG_ GTW_osdActive : 15|1@1+ (1,0) [0|1] "" Vector__XXX
 SG_ GTW_primaryGearControlStatus : 16|4@1+ (1,0) [0|15] "" Vector__XXX
 SG_ GTW_gearStripEnable : 20|1@1+ (1,0) [0|1] "" Vector__XXX
 SG_ GTW_showNeutralButton : 21|1@1+ (1,0) [0|1] "" Vector__XXX
 SG_ GTW_showAutoParkButton : 22|1@1+ (1,0) [0|1] "" Vector__XXX
 SG_ GTW_autoParkRequest : 23|1@1+ (1,0) [0|1] "" Vector__XXX
 SG_ GTW_smartShiftStatus : 24|4@1+ (1,0) [1|15] "" Vector__XXX
 SG_ GTW_processingRDgestures : 28|1@1+ (1,0) [0|1] "" Vector__XXX
 SG_ GTW_processingTapPgestures : 29|1@1+ (1,0) [0|1] "" Vector__XXX
 SG_ GTW_gearStripChangeReason : 32|5@1+ (1,0) [1|31] "" Vector__XXX
 SG_ GTW_touchActive : 37|1@1+ (1,0) [0|1] "" Vector__XXX
 SG_ GTW_steamOff : 38|1@1+ (1,0) [0|1] "" Vector__XXX
 SG_ GTW_screenPCBTemperature : 47|12@0- (0.0625,0) [-128|127.875] "degC" Vector__XXX

BO_TX_BU_ 971 : APSB;
BO_TX_BU_ 845 : APSB;
BO_TX_BU_ 1143 : APSB;
BO_TX_BU_ 942 : APSB;
BO_TX_BU_ 976 : APSB;
BO_TX_BU_ 1003 : APSB;
BO_TX_BU_ 551 : CMP;
BO_TX_BU_ 778 : DAS;
BO_TX_BU_ 781 : DAS;
BO_TX_BU_ 1548 : DAS;
BO_TX_BU_ 1592 : EPAS3P;
BO_TX_BU_ 888 : GTW;
BO_TX_BU_ 282 : GTW;
BO_TX_BU_ 1384 : GTW;
BO_TX_BU_ 62 : GTW;
BO_TX_BU_ 838 : GTW;
BO_TX_BU_ 904 : GTW;
BO_TX_BU_ 792 : GTW;
BO_TX_BU_ 1080 : GTW;
BO_TX_BU_ 1376 : GTW;
BO_TX_BU_ 1656 : GTW;
CM_ BO_ 971 "APSB ECU message: status";
CM_ SG_ 971 APSB_appStatusMonitorState "APSB ECU: app status monitor state";
CM_ SG_ 971 APSB_vehBehaviorState "APSB ECU: veh behavior state";
CM_ SG_ 971 APSB_canMaster "Indicates which of the autopilot computers is currently controlling outgoing CAN traffic; raw 3 = signal not available (SNA)";
CM_ SG_ 971 APSB_appGpioState "APSB ECU: app gpio state";
CM_ SG_ 971 APSB_eacInternalState "APSB ECU: eac internal state";
CM_ SG_ 971 APSB_switchState "APSB ECU: switch state";
CM_ SG_ 971 APSB_apbStatusMonitorState "APSB ECU: apb status monitor state";
CM_ SG_ 971 APSB_apbGpioState "APSB ECU: apb gpio state";
CM_ SG_ 971 APSB_statusCounter "APSB ECU: status counter";
CM_ SG_ 971 APSB_locLimitReason "APSB ECU: loc limit reason";
CM_ SG_ 971 APSB_appPowerStateRequest "APSB ECU: app power state request";
CM_ SG_ 971 APSB_appPowerStateReason "APSB ECU: app power state reason";
CM_ SG_ 971 APSB_apbPowerStateRequest "APSB ECU: apb power state request";
CM_ SG_ 971 APSB_apbPowerStateReason "APSB ECU: apb power state reason";
CM_ SG_ 971 APSB_heaterStateDebug "APSB ECU: heater state debug; raw 7 = signal not available (SNA)";
CM_ SG_ 971 APSB_autosummonCounter "APSB ECU: autosummon counter";
CM_ SG_ 971 APSB_autosummonAlert "APSB ECU: autosummon alert";
CM_ SG_ 971 APSB_gpsAntennaState "APSB ECU: gps antenna state";
CM_ SG_ 971 APSB_arbState "APSB ECU: arb state";
CM_ SG_ 971 APSB_socPowerOperatingMode "APSB ECU: soc power operating mode";
CM_ BO_ 845 "APSB ECU message: warning matrix0";
CM_ SG_ 845 APSB_w001_DEPRECATED "APSB ECU: w001 DEPRECATED";
CM_ SG_ 845 APSB_w002_ldwDisabled "APSB ECU: w002 ldw disabled";
CM_ SG_ 845 APSB_w003_isaDisabled "APSB ECU: w003 isa disabled";
CM_ SG_ 845 APSB_w004_accDisabled "APSB ECU: w004 acc disabled";
CM_ SG_ 845 APSB_w005_fcwCancelled "APSB ECU: w005 fcw cancelled";
CM_ SG_ 845 APSB_w006_aebCancelled "APSB ECU: w006 aeb cancelled";
CM_ SG_ 845 APSB_w007_ahlbDisabled "APSB ECU: w007 ahlb disabled";
CM_ SG_ 845 APSB_w008_parkDisabled "APSB ECU: w008 park disabled";
CM_ SG_ 845 APSB_w009_aebFault "APSB ECU: w009 aeb fault";
CM_ SG_ 845 APSB_w010_radcCalibIssue "APSB ECU: w010 radc calib issue";
CM_ SG_ 845 APSB_w011_scaEvent "APSB ECU: w011 sca event";
CM_ SG_ 845 APSB_w012_Cam_BootFailure "APSB ECU: w012 cam boot failure";
CM_ SG_ 845 APSB_w013_Cam_Watchdog "APSB ECU: w013 cam watchdog";
CM_ SG_ 845 APSB_w014_swAssert "APSB ECU: w014 sw assert";
CM_ SG_ 845 APSB_w015_Camera_Failsafes "APSB ECU: w015 camera failsafes";
CM_ SG_ 845 APSB_w016_aeb_e_event "APSB ECU: w016 aeb e event";
CM_ SG_ 845 APSB_w017_Cam_Msg_MIA "APSB ECU: w017 cam msg MIA";
CM_ SG_ 845 APSB_w018_ECU_Power_Issue "APSB ECU: w018 ECU power issue";
CM_ SG_ 845 APSB_w019_ECU_Stack_Overflow "APSB ECU: w019 ECU stack overflow";
CM_ SG_ 845 APSB_w020_ECU_checkstopError "APSB ECU: w020 ECU checkstop error";
CM_ SG_ 845 APSB_w021_ECU_Temperature_Issue "APSB ECU: w021 ECU temperature issue";
CM_ SG_ 845 APSB_w022_ECU_EEPROM_Failure "APSB ECU: w022 ECU EEPROM failure";
CM_ SG_ 845 APSB_w023_ECU_Cam_Statemismatc "APSB ECU: w023 ECU cam statemismatc";
CM_ SG_ 845 APSB_w024_ECU_Watchdog_Reset "APSB ECU: w024 ECU watchdog reset";
CM_ SG_ 845 APSB_w025_LC_Steering_Override "APSB ECU: w025 LC steering override";
CM_ SG_ 845 APSB_w026_ECU_timingIssue "APSB ECU: w026 ECU timing issue";
CM_ SG_ 845 APSB_w027_ECU_Reset_Fault "APSB ECU: w027 ECU reset fault";
CM_ SG_ 845 APSB_w028_spi_rx_error "APSB ECU: w028 spi rx error";
CM_ SG_ 845 APSB_w029_spi_tx_error "APSB ECU: w029 spi tx error";
CM_ SG_ 845 APSB_w030_Heater_Issue "APSB ECU: w030 heater issue";
CM_ SG_ 845 APSB_w031_canRxError "APSB ECU: w031 can rx error";
CM_ SG_ 845 APSB_w032_canTxError "APSB ECU: w032 can tx error";
CM_ SG_ 845 APSB_w033_gtwMia "APSB ECU: w033 gtw mia";
CM_ SG_ 845 APSB_w034_sccmMia "APSB ECU: w034 sccm mia";
CM_ SG_ 845 APSB_w035_espMia "APSB ECU: w035 esp mia";
CM_ SG_ 845 APSB_w036_bdyMia "APSB ECU: w036 bdy mia";
CM_ SG_ 845 APSB_w037_camTacIssue "APSB ECU: w037 cam tac issue";
CM_ SG_ 845 APSB_w038_camFailure "APSB ECU: w038 cam failure";
CM_ SG_ 845 APSB_w039_sdm_rcm_Mia "APSB ECU: w039 sdm rcm mia";
CM_ SG_ 845 APSB_w040_autopilotAngleSaturate "APSB ECU: w040 autopilot angle saturated";
CM_ SG_ 845 APSB_w041_autopilotRateSaturated "APSB ECU: w041 autopilot rate saturated";
CM_ SG_ 845 APSB_w042_autopilotAborting "APSB ECU: w042 autopilot aborting";
CM_ SG_ 845 APSB_w043_camLongRunTime "APSB ECU: w043 cam long run time";
CM_ SG_ 845 APSB_w044_appMobileyeFailure "APSB ECU: w044 app mobileye failure";
CM_ SG_ 845 APSB_w045_radMia "APSB ECU: w045 rad mia";
CM_ SG_ 845 APSB_w046_eepromRecordAbsent "APSB ECU: w046 eeprom record absent";
CM_ SG_ 845 APSB_w047_edrEvent "APSB ECU: w047 edr event";
CM_ SG_ 845 APSB_w048_DAS_Features_Disabled "APSB ECU: w048 DAS features disabled";
CM_ SG_ 845 APSB_w049_eyeqVersionMismatch "APSB ECU: w049 eyeq version mismatch";
CM_ SG_ 845 APSB_w050_aeb_event "APSB ECU: w050 aeb event";
CM_ SG_ 845 APSB_w051_radcEcuIssue "APSB ECU: w051 radc ecu issue";
CM_ SG_ 845 APSB_w052_radcSensorIssue "APSB ECU: w052 radc sensor issue";
CM_ SG_ 845 APSB_w053_radcCommIssue "APSB ECU: w053 radc comm issue";
CM_ SG_ 845 APSB_w054_camAutofix "APSB ECU: w054 cam autofix";
CM_ SG_ 845 APSB_w055_radcVersionMismatch "APSB ECU: w055 radc version mismatch";
CM_ SG_ 845 APSB_w056_diMia "APSB ECU: w056 di mia";
CM_ SG_ 845 APSB_w057_mcuMia "APSB ECU: w057 mcu mia";
CM_ SG_ 845 APSB_w058_epbMia "APSB ECU: w058 epb mia";
CM_ SG_ 845 APSB_w059_parkMia "APSB ECU: w059 park mia";
CM_ SG_ 845 APSB_w060_fcw_event "APSB ECU: w060 fcw event";
CM_ SG_ 845 APSB_w061_tasMia "APSB ECU: w061 tas mia";
CM_ SG_ 845 APSB_w062_radcAlignment "APSB ECU: w062 radc alignment";
CM_ SG_ 845 APSB_w063_parkVersionMismatch "APSB ECU: w063 park version mismatch";
CM_ SG_ 845 APSB_w064_epasMia "APSB ECU: w064 epas mia";
CM_ BO_ 1143 "APSB ECU message: warning matrix1";
CM_ SG_ 1143 APSB_w065_deserializerOvercurren "APSB ECU: w065 deserializer overcurrent";
CM_ SG_ 1143 APSB_w066_deserializerLockLost "APSB ECU: w066 deserializer lock lost";
CM_ SG_ 1143 APSB_w067_steeringAlignment "APSB ECU: w067 steering alignment";
CM_ SG_ 1143 APSB_w068_vlInconsistency "APSB ECU: w068 vl inconsistency";
CM_ SG_ 1143 APSB_w069_apcSpaceMasked "APSB ECU: w069 apc space masked";
CM_ SG_ 1143 APSB_w070_apcIncompleteCal "APSB ECU: w070 apc incomplete cal";
CM_ SG_ 1143 APSB_w071_selfparkStarted "APSB ECU: w071 selfpark started";
CM_ SG_ 1143 APSB_w072_selfparkComplete "APSB ECU: w072 selfpark complete";
CM_ SG_ 1143 APSB_w073_issueEscalatedLDW "APSB ECU: w073 issue escalated LDW";
CM_ SG_ 1143 APSB_w074_inPathStationaryObst "APSB ECU: w074 in path stationary obst";
CM_ SG_ 1143 APSB_w075_scMia "APSB ECU: w075 sc mia";
CM_ SG_ 1143 APSB_w076_mobilEyeSetC "APSB ECU: w076 mobil eye set c";
CM_ SG_ 1143 APSB_w077_pmmActive "APSB ECU: w077 pmm active";
CM_ SG_ 1143 APSB_w078_pmmActive2 "APSB ECU: w078 pmm active2";
CM_ SG_ 1143 APSB_w079_edrAvailable "APSB ECU: w079 edr available";
CM_ SG_ 1143 APSB_w080_accFailedActivation "APSB ECU: w080 acc failed activation";
CM_ SG_ 1143 APSB_w081_pmmActiveBraking "APSB ECU: w081 pmm active braking";
CM_ SG_ 1143 APSB_w082_inPathFSviolation "APSB ECU: w082 in path f sviolation";
CM_ SG_ 1143 APSB_w083_inPathRADObject "APSB ECU: w083 in path RAD object";
CM_ SG_ 1143 APSB_w084_pmmIPSO "APSB ECU: w084 pmm IPSO";
CM_ SG_ 1143 APSB_w085_pmmSteering "APSB ECU: w085 pmm steering";
CM_ SG_ 1143 APSB_w086_robCollision "APSB ECU: w086 rob collision";
CM_ SG_ 1143 APSB_w087_DEPRECATED "APSB ECU: w087 DEPRECATED";
CM_ SG_ 1143 APSB_w088_DEPRECATED "APSB ECU: w088 DEPRECATED";
CM_ SG_ 1143 APSB_w089_DEPRECATED "APSB ECU: w089 DEPRECATED";
CM_ SG_ 1143 APSB_w090_DEPRECATED "APSB ECU: w090 DEPRECATED";
CM_ SG_ 1143 APSB_w091_DEPRECATED "APSB ECU: w091 DEPRECATED";
CM_ SG_ 1143 APSB_w092_DEPRECATED "APSB ECU: w092 DEPRECATED";
CM_ SG_ 1143 APSB_w093_DEPRECATED "APSB ECU: w093 DEPRECATED";
CM_ SG_ 1143 APSB_w094_DEPRECATED "APSB ECU: w094 DEPRECATED";
CM_ SG_ 1143 APSB_w095_DEPRECATED "APSB ECU: w095 DEPRECATED";
CM_ SG_ 1143 APSB_w096_DEPRECATED "APSB ECU: w096 DEPRECATED";
CM_ SG_ 1143 APSB_w097_DEPRECATED "APSB ECU: w097 DEPRECATED";
CM_ SG_ 1143 APSB_w098_DEPRECATED "APSB ECU: w098 DEPRECATED";
CM_ SG_ 1143 APSB_w099_DEPRECATED "APSB ECU: w099 DEPRECATED";
CM_ SG_ 1143 APSB_w100_DEPRECATED "APSB ECU: w100 DEPRECATED";
CM_ SG_ 1143 APSB_w101_DEPRECATED "APSB ECU: w101 DEPRECATED";
CM_ SG_ 1143 APSB_w102_DEPRECATED "APSB ECU: w102 DEPRECATED";
CM_ SG_ 1143 APSB_w103_robExperimentalAEB "APSB ECU: w103 rob experimental AEB";
CM_ SG_ 1143 APSB_w104_DEPRECATED "APSB ECU: w104 DEPRECATED";
CM_ SG_ 1143 APSB_w105_DEPRECATED "APSB ECU: w105 DEPRECATED";
CM_ SG_ 1143 APSB_w106_torsionBarOffset "APSB ECU: w106 torsion bar offset";
CM_ BO_ 942 "APSB ECU message: warning matrix2";
CM_ SG_ 942 APSB_w129_ECU_Power_Issue "APSB ECU: w129 ECU power issue";
CM_ SG_ 942 APSB_w130_ECU_Thermal_Issue "APSB ECU: w130 ECU thermal issue";
CM_ SG_ 942 APSB_w131_trap_exception "APSB ECU: w131 trap exception";
CM_ SG_ 942 APSB_w132_appVersionMismatch "APSB ECU: w132 app version mismatch";
CM_ SG_ 942 APSB_w133_ETHSwitchError "APSB ECU: w133 ETH switch error";
CM_ SG_ 942 APSB_w134_appMia "APSB ECU: w134 app mia";
CM_ SG_ 942 APSB_w135_appCritical "APSB ECU: w135 app critical";
CM_ SG_ 942 APSB_w136_gpsDisabled "APSB ECU: w136 gps disabled";
CM_ SG_ 942 APSB_w137_gpsFaultReset "APSB ECU: w137 gps fault reset";
CM_ SG_ 942 APSB_w138_gpsComIssue "APSB ECU: w138 gps com issue";
CM_ SG_ 942 APSB_w139_udpBufferOverflow "APSB ECU: w139 udp buffer overflow";
CM_ SG_ 942 APSB_w140_vcfrontMiaVehicleBus "APSB ECU: w140 vcfront mia vehicle bus";
CM_ SG_ 942 APSB_w141_rcmMiaPartyBus "APSB ECU: w141 rcm mia party bus";
CM_ SG_ 942 APSB_w142_diMiaPartyBus "APSB ECU: w142 di mia party bus";
CM_ SG_ 942 APSB_w143_espMiaPartyBus "APSB ECU: w143 esp mia party bus";
CM_ SG_ 942 APSB_w144_vcleftMiaPartyBus "APSB ECU: w144 vcleft mia party bus";
CM_ SG_ 942 APSB_w145_vcrightMiaPartyBus "APSB ECU: w145 vcright mia party bus";
CM_ SG_ 942 APSB_w146_epas3pMiaPartyBus "APSB ECU: w146 epas3p mia party bus";
CM_ SG_ 942 APSB_w147_vcleftMiaVehBus "APSB ECU: w147 vcleft mia veh bus";
CM_ SG_ 942 APSB_w148_vcrightMiaVehBus "APSB ECU: w148 vcright mia veh bus";
CM_ SG_ 942 APSB_w149_epblMiaVehBus "APSB ECU: w149 epbl mia veh bus";
CM_ SG_ 942 APSB_w150_sccmMiaVehBus "APSB ECU: w150 sccm mia veh bus";
CM_ SG_ 942 APSB_w151_apRecovered "APSB ECU: w151 ap recovered";
CM_ SG_ 942 APSB_w152_gpsFusionStatus "APSB ECU: w152 gps fusion status";
CM_ SG_ 942 APSB_w153_eacInhibit "APSB ECU: w153 eac inhibit";
CM_ SG_ 942 APSB_w155_ethLwipError "APSB ECU: w155 eth lwip error";
CM_ SG_ 942 APSB_w156_lwipAssert "APSB ECU: w156 lwip assert";
CM_ SG_ 942 APSB_w157_autopilotReboot "APSB ECU: w157 autopilot reboot";
CM_ SG_ 942 APSB_w158_apbMia "APSB ECU: w158 apb mia";
CM_ SG_ 942 APSB_w159_apbCritical "APSB ECU: w159 apb critical";
CM_ SG_ 942 APSB_w160_apbVersionMismatch "APSB ECU: w160 apb version mismatch";
CM_ SG_ 942 APSB_w161_gpsAntennaDisconnected "APSB ECU: w161 gps antenna disconnected";
CM_ SG_ 942 APSB_w162_TurboA_DisRegPgoodErr "APSB ECU: w162 turbo a dis reg pgood err";
CM_ SG_ 942 APSB_w163_TurboA_DisRegNFault "APSB ECU: w163 turbo a dis reg n fault";
CM_ SG_ 942 APSB_w164_TurboA_12VFuseFault "APSB ECU: w164 turbo a 12 v fuse fault";
CM_ SG_ 942 APSB_w165_TurboA_Temp_NOS "APSB ECU: w165 turbo a temp NOS";
CM_ SG_ 942 APSB_w166_TurboA_SMSLockStepErr "APSB ECU: w166 turbo a SMS lock step err";
CM_ SG_ 942 APSB_w167_TurboA_TMU_Throttle "APSB ECU: w167 turbo a TMU throttle";
CM_ SG_ 942 APSB_w168_TurboA_SMS_WDOG "APSB ECU: w168 turbo a SMS WDOG";
CM_ SG_ 942 APSB_w169_TurboA_SCS_LKUP "APSB ECU: w169 turbo a SCS LKUP";
CM_ SG_ 942 APSB_w170_TurboA_A72_watchdog "APSB ECU: w170 turbo a A72 watchdog";
CM_ SG_ 942 APSB_w171_TurboA_SMS_taskUtilErr "APSB ECU: w171 turbo a SMS task util err";
CM_ SG_ 942 APSB_w172_apFeaturesUnavailable "APSB ECU: w172 ap features unavailable";
CM_ SG_ 942 APSB_w178_TurboB_DisRegPgoodErr "APSB ECU: w178 turbo b dis reg pgood err";
CM_ SG_ 942 APSB_w179_TurboB_DisRegNFault "APSB ECU: w179 turbo b dis reg n fault";
CM_ SG_ 942 APSB_w180_TurboB_12VFuseFault "APSB ECU: w180 turbo b 12 v fuse fault";
CM_ SG_ 942 APSB_w181_TurboB_Temp_NOS "APSB ECU: w181 turbo b temp NOS";
CM_ SG_ 942 APSB_w182_TurboB_SMSLockStepErr "APSB ECU: w182 turbo b SMS lock step err";
CM_ SG_ 942 APSB_w183_TurboB_TMU_Throttle "APSB ECU: w183 turbo b TMU throttle";
CM_ SG_ 942 APSB_w184_TurboB_SMS_WDOG "APSB ECU: w184 turbo b SMS WDOG";
CM_ SG_ 942 APSB_w185_TurboB_SCS_LKUP "APSB ECU: w185 turbo b SCS LKUP";
CM_ SG_ 942 APSB_w186_TurboB_A72_watchdog "APSB ECU: w186 turbo b A72 watchdog";
CM_ SG_ 942 APSB_w187_TurboB_SMS_taskUtilErr "APSB ECU: w187 turbo b SMS task util err";
CM_ SG_ 942 APSB_w188_otherTurboUartMIA "APSB ECU: w188 other turbo uart MIA";
CM_ SG_ 942 APSB_w189_vcfrontMiaPartyBus "APSB ECU: w189 vcfront mia party bus";
CM_ SG_ 942 APSB_w190_iboosterMia "APSB ECU: w190 ibooster mia";
CM_ SG_ 942 APSB_w191_timesyncError "APSB ECU: w191 timesync error";
CM_ SG_ 942 APSB_w192_CANFault "APSB ECU: w192 CAN fault";
CM_ BO_ 976 "APSB ECU message: warning matrix3";
CM_ SG_ 976 APSB_w193_camWindshieldUnclean "APSB ECU: w193 cam windshield unclean";
CM_ SG_ 976 APSB_w194_accDriverResumeRqrd "APSB ECU: w194 acc driver resume rqrd";
CM_ SG_ 976 APSB_w195_scwUnavailable "APSB ECU: w195 scw unavailable";
CM_ SG_ 976 APSB_w196_stopSignWarning "APSB ECU: w196 stop sign warning";
CM_ SG_ 976 APSB_w197_redLightWarning "APSB ECU: w197 red light warning";
CM_ SG_ 976 APSB_w198_tsrUnavailable "APSB ECU: w198 tsr unavailable";
CM_ SG_ 976 APSB_w199_apcAbort "APSB ECU: w199 apc abort";
CM_ SG_ 976 APSB_w200_lcSlowdown "APSB ECU: w200 lc slowdown";
CM_ SG_ 976 APSB_w201_lcAborting "APSB ECU: w201 lc aborting";
CM_ SG_ 976 APSB_w202_scwNoisyEnvironment "APSB ECU: w202 scw noisy environment";
CM_ SG_ 976 APSB_w203_apcActivation "APSB ECU: w203 apc activation";
CM_ SG_ 976 APSB_w204_apcFinalFront "APSB ECU: w204 apc final front";
CM_ SG_ 976 APSB_w205_apcFinalRear "APSB ECU: w205 apc final rear";
CM_ SG_ 976 APSB_w206_autosteerNotEnabled "APSB ECU: w206 autosteer not enabled";
CM_ SG_ 976 APSB_w207_autosteerUnavailable "APSB ECU: w207 autosteer unavailable";
CM_ SG_ 976 APSB_w208_rackDetected "APSB ECU: w208 rack detected";
CM_ SG_ 976 APSB_w209_autoSummonRequest "APSB ECU: w209 auto summon request";
CM_ SG_ 976 APSB_w210_camObstrcted "APSB ECU: w210 cam obstrcted";
CM_ SG_ 976 APSB_w211_accNoSeatBelt "APSB ECU: w211 acc no seat belt";
CM_ SG_ 976 APSB_w212_lcUnavailableStrikeOut "APSB ECU: w212 lc unavailable strike out";
CM_ SG_ 976 APSB_w213_autosteerStruckOut "APSB ECU: w213 autosteer struck out";
CM_ SG_ 976 APSB_w214_driverNotIntracting "APSB ECU: w214 driver not intracting";
CM_ SG_ 976 APSB_w215_contDriverNotIntractin "APSB ECU: w215 cont driver not intracting";
CM_ SG_ 976 APSB_w216_driverOverriding "APSB ECU: w216 driver overriding";
CM_ SG_ 976 APSB_w217_lcUnavailableSpeeding "APSB ECU: w217 lc unavailable speeding";
CM_ SG_ 976 APSB_w218_lcSpeedExceededLimit "APSB ECU: w218 lc speed exceeded limit";
CM_ SG_ 976 APSB_w219_lcTempUnavailableSpeed "APSB ECU: w219 lc temp unavailable speed";
CM_ SG_ 976 APSB_w220_lcTempUnavailableRoad "APSB ECU: w220 lc temp unavailable road";
CM_ SG_ 976 APSB_w221_accRadarBlind "APSB ECU: w221 acc radar blind";
CM_ SG_ 976 APSB_w222_accCameraBlind "APSB ECU: w222 acc camera blind";
CM_ SG_ 976 APSB_w223_accObjectInPath "APSB ECU: w223 acc object in path";
CM_ SG_ 976 APSB_w224_accCameraCalibration "APSB ECU: w224 acc camera calibration";
CM_ SG_ 976 APSB_w225_lcDegradedVisSpeedLmt "APSB ECU: w225 lc degraded vis speed lmt";
CM_ SG_ 976 APSB_w226_lcCamCalNeededSpeedLmt "APSB ECU: w226 lc cam cal needed speed lmt";
CM_ SG_ 976 APSB_w227_virtualWallBlocked "APSB ECU: w227 virtual wall blocked";
CM_ SG_ 976 APSB_w228_DEPRECATED "APSB ECU: w228 DEPRECATED";
CM_ SG_ 976 APSB_w229_alcUltrasoundDamaged "APSB ECU: w229 alc ultrasound damaged";
CM_ SG_ 976 APSB_w230_alcUltrasoundBlocked "APSB ECU: w230 alc ultrasound blocked";
CM_ SG_ 976 APSB_w231_idfEvent "APSB ECU: w231 idf event";
CM_ SG_ 976 APSB_w232_laneChangeRequested "APSB ECU: w232 lane change requested";
CM_ SG_ 976 APSB_w235_a72LoopDetected "APSB ECU: w235 a72 loop detected";
CM_ SG_ 976 APSB_w236_canSharedMemError "APSB ECU: w236 can shared mem error";
CM_ SG_ 976 APSB_w237_faultMgrEventDetected "APSB ECU: w237 fault mgr event detected";
CM_ SG_ 976 APSB_w238_resetReason "APSB ECU: w238 reset reason";
CM_ SG_ 976 APSB_w241_ddrInitFailures "APSB ECU: w241 ddr init failures";
CM_ SG_ 976 APSB_w242_tripMBISTFailure "APSB ECU: w242 trip MBIST failure";
CM_ SG_ 976 APSB_w243_tripHWErrorStatus "APSB ECU: w243 trip HW error status";
CM_ SG_ 976 APSB_w244_gpuHWFaultStatus "APSB ECU: w244 gpu HW fault status";
CM_ SG_ 976 APSB_w245_eloopRxFromUnexpectedS "APSB ECU: w245 eloop rx from unexpected source MAC";
CM_ SG_ 976 APSB_w246_ethloopSwitchPortLinkD "APSB ECU: w246 ethloop switch port link down";
CM_ SG_ 976 APSB_w247_ethernetFrameError "APSB ECU: w247 ethernet frame error";
CM_ SG_ 976 APSB_w248_ethloopSwitchPoorSqi "APSB ECU: w248 ethloop switch poor sqi";
CM_ SG_ 976 APSB_w249_ufsFailures "APSB ECU: w249 ufs failures";
CM_ SG_ 976 APSB_w250_ethloopSwitchMemUsageT "APSB ECU: w250 ethloop switch mem usage too high port2";
CM_ SG_ 976 APSB_w251_ethloopSwitchMemUsageT "APSB ECU: w251 ethloop switch mem usage too high port3";
CM_ SG_ 976 APSB_w252_ethSwitchPortLinkDown "APSB ECU: w252 eth switch port link down";
CM_ SG_ 976 APSB_w253_powerStateTimeout "APSB ECU: w253 power state timeout";
CM_ SG_ 976 APSB_w254_sleepStateTimeout "APSB ECU: w254 sleep state timeout";
CM_ SG_ 976 APSB_w255_bootHealth "APSB ECU: w255 boot health";
CM_ BO_ 1003 "APSB ECU message: warning matrix4";
CM_ SG_ 1003 APSB_w257_assertFailure "APSB ECU: w257 assert failure";
CM_ SG_ 1003 APSB_w258_qspiFlashSectorChecksu "APSB ECU: w258 qspi flash sector checksum mismatch";
CM_ SG_ 1003 APSB_w259_qspiFailure "APSB ECU: w259 qspi failure";
CM_ SG_ 1003 APSB_w260_pgoodFailure "APSB ECU: w260 pgood failure";
CM_ SG_ 1003 APSB_w261_vrmFaultGrpA "APSB ECU: w261 vrm fault grp a";
CM_ SG_ 1003 APSB_w262_vrmFaultGrpB "APSB ECU: w262 vrm fault grp b";
CM_ SG_ 1003 APSB_w263_vrmFaultGrpC "APSB ECU: w263 vrm fault grp c";
CM_ SG_ 1003 APSB_w264_ddrPhy0Failures "APSB ECU: w264 ddr phy0 failures";
CM_ SG_ 1003 APSB_w265_ddrPhy1Failures "APSB ECU: w265 ddr phy1 failures";
CM_ SG_ 1003 APSB_w266_ddrPhy2Failures "APSB ECU: w266 ddr phy2 failures";
CM_ SG_ 1003 APSB_w267_ddrPhy3Failures "APSB ECU: w267 ddr phy3 failures";
CM_ SG_ 1003 APSB_w268_ddrControllerFailures "APSB ECU: w268 ddr controller failures";
CM_ SG_ 1003 APSB_w269_ethSwitchRxPageCountTo "APSB ECU: w269 eth switch rx page count too high port0 3";
CM_ SG_ 1003 APSB_w270_ethSwitchRxPageCountTo "APSB ECU: w270 eth switch rx page count too high port4 7";
CM_ SG_ 1003 APSB_w271_ddrScheduler0EccErrors "APSB ECU: w271 ddr scheduler0 ecc errors";
CM_ SG_ 1003 APSB_w272_ddrScheduler1EccErrors "APSB ECU: w272 ddr scheduler1 ecc errors";
CM_ SG_ 1003 APSB_w273_ddrScheduler2EccErrors "APSB ECU: w273 ddr scheduler2 ecc errors";
CM_ SG_ 1003 APSB_w274_ddrScheduler3EccErrors "APSB ECU: w274 ddr scheduler3 ecc errors";
CM_ SG_ 1003 APSB_w275_ddrScheduler4EccErrors "APSB ECU: w275 ddr scheduler4 ecc errors";
CM_ SG_ 1003 APSB_w276_ddrScheduler5EccErrors "APSB ECU: w276 ddr scheduler5 ecc errors";
CM_ SG_ 1003 APSB_w277_ddrScheduler6EccErrors "APSB ECU: w277 ddr scheduler6 ecc errors";
CM_ SG_ 1003 APSB_w278_ddrScheduler7EccErrors "APSB ECU: w278 ddr scheduler7 ecc errors";
CM_ SG_ 1003 APSB_w279_ufsPartitionError "APSB ECU: w279 ufs partition error";
CM_ SG_ 1003 APSB_w280_pepsMia "APSB ECU: w280 peps mia";
CM_ SG_ 1003 APSB_w281_rsaMia "APSB ECU: w281 rsa mia";
CM_ SG_ 1003 APSB_w282_smmuError "APSB ECU: w282 smmu error";
CM_ SG_ 1003 APSB_w283_psfaMia "APSB ECU: w283 psfa mia";
CM_ SG_ 1003 APSB_w284_cam12VBuckBoostAPwrIss "APSB ECU: w284 cam12 v buck boost a pwr issue";
CM_ SG_ 1003 APSB_w285_cam12VBuckBoostBPwrIss "APSB ECU: w285 cam12 v buck boost b pwr issue";
CM_ SG_ 1003 APSB_w286_cam12VEFuseAPrimaryIss "APSB ECU: w286 cam12 VE fuse a primary issue";
CM_ SG_ 1003 APSB_w287_cam12VEFuseASecondaryI "APSB ECU: w287 cam12 VE fuse a secondary issue";
CM_ SG_ 1003 APSB_w288_brakeboosterMia "APSB ECU: w288 brakebooster mia";
CM_ SG_ 1003 APSB_w289_turboTemperatureWarnin "APSB ECU: w289 turbo temperature warning";
CM_ SG_ 1003 APSB_w290_cam12VBuckBoostBPwrRin "APSB ECU: w290 cam12 v buck boost b pwr ringing";
CM_ SG_ 1003 APSB_w291_eplannerError "APSB ECU: w291 eplanner error";
CM_ SG_ 1003 APSB_w292_CH_busOff "APSB ECU: w292 CH bus off";
CM_ SG_ 1003 APSB_w293_PARTY_busOff "APSB ECU: w293 PARTY bus off";
CM_ SG_ 1003 APSB_w294_VEH_busOff "APSB ECU: w294 VEH bus off";
CM_ SG_ 1003 APSB_w295_PT_busOff "APSB ECU: w295 PT bus off";
CM_ SG_ 1003 APSB_w296_wdogMonTaskDeadlineMis "APSB ECU: w296 wdog mon task deadline miss";
CM_ SG_ 1003 APSB_w297_earlyWDogAlert "APSB ECU: w297 early w dog alert";
CM_ SG_ 1003 APSB_w298_cpuToApCanSharedMemErr "APSB ECU: w298 cpu to ap can shared mem error";
CM_ SG_ 1003 APSB_w299_apToCpuCanSharedMemErr "APSB ECU: w299 ap to cpu can shared mem error";
CM_ SG_ 1003 APSB_w300_sharedMemoryAccessErro "APSB ECU: w300 shared memory access error";
CM_ SG_ 1003 APSB_w301_nocTimeoutDetected "APSB ECU: w301 noc timeout detected";
CM_ SG_ 1003 APSB_w302_canAPShmFifoFull "APSB ECU: w302 can AP shm fifo full";
CM_ SG_ 1003 APSB_w303_canAPShmFifoEmpty "APSB ECU: w303 can AP shm fifo empty";
CM_ SG_ 1003 APSB_w304_dataAbort "APSB ECU: w304 data abort";
CM_ SG_ 1003 APSB_w305_gpsPgoodFailure "APSB ECU: w305 gps pgood failure";
CM_ SG_ 1003 APSB_w306_ethPgoodFailure "APSB ECU: w306 eth pgood failure";
CM_ SG_ 1003 APSB_w307_eccEventDetected "APSB ECU: w307 ecc event detected";
CM_ SG_ 1003 APSB_w308_pmicErrorDetected "APSB ECU: w308 pmic error detected";
CM_ SG_ 1003 APSB_w309_ethBridgeDown "APSB ECU: w309 eth bridge down";
CM_ SG_ 1003 APSB_w310_wakeBootMetrics "APSB ECU: w310 wake boot metrics";
CM_ SG_ 1003 APSB_w311_apbdgDasMia "APSB ECU: w311 apbdg das mia";
CM_ SG_ 1003 APSB_w312_apbdgApMia "APSB ECU: w312 apbdg ap mia";
CM_ SG_ 1003 APSB_w313_BDY_busOff "APSB ECU: w313 BDY bus off";
CM_ SG_ 1003 APSB_w315_epas3pMiaBdyBus "APSB ECU: w315 epas3p mia bdy bus";
CM_ SG_ 1003 APSB_w316_apBootHealth "APSB ECU: w316 ap boot health";
CM_ SG_ 1003 APSB_w317_uiMia "APSB ECU: w317 ui mia";
CM_ SG_ 1003 APSB_w318_ethernetNetworkBufferH "APSB ECU: w318 ethernet network buffer high watermark";
CM_ SG_ 1003 APSB_w319_vehDasImposterDetected "APSB ECU: w319 veh das imposter detected";
CM_ SG_ 1003 APSB_w320_eplannerPreconditionsM "APSB ECU: w320 eplanner preconditions met";
CM_ BO_ 551 "A/C compressor message: HV status";
CM_ SG_ 551 CMP_inputHVVoltage "Compressor high voltage input voltage";
CM_ SG_ 551 CMP_inputLVVoltage "A/C compressor: input LV voltage";
CM_ SG_ 551 CMP_inputHVCurrent "A/C compressor: input HV current";
CM_ SG_ 551 CMP_inputHVPower "Compressor high voltage input power";
CM_ BO_ 778 "Driver assistance computer message: object";
CM_ SG_ 778 DAS_objectId "Driver assistance computer: object id";
CM_ SG_ 778 DAS_leadVehType "Driver assistance computer: lead veh type";
CM_ SG_ 778 DAS_leadVehRelevantForControl "Driver assistance computer: lead veh relevant for control";
CM_ SG_ 778 DAS_leadVehDx "Measures the distance to lead vehicle, or vehicle in the ego lane; raw 255 = signal not available (SNA)";
CM_ SG_ 778 DAS_leadVehVxRel "Driver assistance computer: lead veh vx rel; raw 15 = signal not available (SNA)";
CM_ SG_ 778 DAS_leadVehDy "Driver assistance computer: lead veh dy";
CM_ SG_ 778 DAS_leadVehId "Driver assistance computer: lead veh id; raw 127 = signal not available (SNA)";
CM_ SG_ 778 DAS_leadVeh2Type "Driver assistance computer: lead veh2 type";
CM_ SG_ 778 DAS_leadVeh2RelevantForControl "Driver assistance computer: lead veh2 relevant for control";
CM_ SG_ 778 DAS_leadVeh2Dx "Driver assistance computer: lead veh2 dx; raw 255 = signal not available (SNA)";
CM_ SG_ 778 DAS_leadVeh2VxRel "Driver assistance computer: lead veh2 vx rel; raw 15 = signal not available (SNA)";
CM_ SG_ 778 DAS_leadVeh2Dy "Driver assistance computer: lead veh2 dy";
CM_ SG_ 778 DAS_leadVeh2Id "Driver assistance computer: lead veh2 id; raw 0 = signal not available (SNA)";
CM_ SG_ 778 DAS_leftVehType "Driver assistance computer: left veh type";
CM_ SG_ 778 DAS_leftVehRelevantForControl "Driver assistance computer: left veh relevant for control";
CM_ SG_ 778 DAS_leftVehDx "Driver assistance computer: left veh dx; raw 255 = signal not available (SNA)";
CM_ SG_ 778 DAS_leftVehVxRel "Driver assistance computer: left veh vx rel; raw 15 = signal not available (SNA)";
CM_ SG_ 778 DAS_leftVehDy "Driver assistance computer: left veh dy";
CM_ SG_ 778 DAS_leftVehId "Driver assistance computer: left veh id; raw 127 = signal not available (SNA)";
CM_ SG_ 778 DAS_leftVeh2Type "Driver assistance computer: left veh2 type";
CM_ SG_ 778 DAS_leftVeh2RelevantForControl "Driver assistance computer: left veh2 relevant for control";
CM_ SG_ 778 DAS_leftVeh2Dx "Driver assistance computer: left veh2 dx; raw 255 = signal not available (SNA)";
CM_ SG_ 778 DAS_leftVeh2VxRel "Driver assistance computer: left veh2 vx rel; raw 15 = signal not available (SNA)";
CM_ SG_ 778 DAS_leftVeh2Dy "Driver assistance computer: left veh2 dy";
CM_ SG_ 778 DAS_leftVeh2Id "Driver assistance computer: left veh2 id; raw 0 = signal not available (SNA)";
CM_ SG_ 778 DAS_rightVehType "Driver assistance computer: right veh type";
CM_ SG_ 778 DAS_rightVehRelevantForControl "Driver assistance computer: right veh relevant for control";
CM_ SG_ 778 DAS_rightVehDx "Driver assistance computer: right veh dx; raw 255 = signal not available (SNA)";
CM_ SG_ 778 DAS_rightVehVxRel "Driver assistance computer: right veh vx rel; raw 15 = signal not available (SNA)";
CM_ SG_ 778 DAS_rightVehDy "Driver assistance computer: right veh dy";
CM_ SG_ 778 DAS_rightVehId "Driver assistance computer: right veh id; raw 127 = signal not available (SNA)";
CM_ SG_ 778 DAS_rightVeh2Type "Driver assistance computer: right veh2 type";
CM_ SG_ 778 DAS_rightVeh2RelevantForControl "Driver assistance computer: right veh2 relevant for control";
CM_ SG_ 778 DAS_rightVeh2Dx "Driver assistance computer: right veh2 dx; raw 255 = signal not available (SNA)";
CM_ SG_ 778 DAS_rightVeh2VxRel "Driver assistance computer: right veh2 vx rel; raw 15 = signal not available (SNA)";
CM_ SG_ 778 DAS_rightVeh2Dy "Driver assistance computer: right veh2 dy";
CM_ SG_ 778 DAS_rightVeh2Id "Driver assistance computer: right veh2 id; raw 0 = signal not available (SNA)";
CM_ SG_ 778 DAS_cutinVehType "Driver assistance computer: cutin veh type";
CM_ SG_ 778 DAS_cutinVehRelevantForControl "Driver assistance computer: cutin veh relevant for control";
CM_ SG_ 778 DAS_cutinVehDx "Driver assistance computer: cutin veh dx; raw 255 = signal not available (SNA)";
CM_ SG_ 778 DAS_cutinVehVxRel "Driver assistance computer: cutin veh vx rel; raw 15 = signal not available (SNA)";
CM_ SG_ 778 DAS_cutinVehDy "Driver assistance computer: cutin veh dy";
CM_ SG_ 778 DAS_cutinVehId "Driver assistance computer: cutin veh id; raw 127 = signal not available (SNA)";
CM_ SG_ 778 DAS_roadSignColor "Driver assistance computer: road sign color";
CM_ SG_ 778 DAS_roadSignId "Driver assistance computer: road sign id; raw 255 = signal not available (SNA)";
CM_ SG_ 778 DAS_roadSignStopLineDist "Driver assistance computer: road sign stop line dist; raw 1023 = signal not available (SNA)";
CM_ SG_ 778 DAS_roadSignControlActive "Driver assistance computer: road sign control active";
CM_ SG_ 778 DAS_roadSignSource "Driver assistance computer: road sign source";
CM_ SG_ 778 DAS_roadSignArrow "Driver assistance computer: road sign arrow";
CM_ SG_ 778 DAS_roadSignOrientation "Driver assistance computer: road sign orientation";
CM_ BO_ 781 "Driver assistance computer message: positioning engine status";
CM_ SG_ 781 DAS_positioningEngineStatusMulti "Driver assistance computer: positioning engine status multiplexer";
CM_ SG_ 781 DAS_meoSolverNumRuns "Driver assistance computer: meo solver num runs";
CM_ SG_ 781 DAS_meoSolverReportTerminationTy "Driver assistance computer: meo solver report termination type";
CM_ SG_ 781 DAS_meoSolverReportTotalTimeS "Driver assistance computer: meo solver report total time s";
CM_ SG_ 781 DAS_meoHorizontalAccuracyM "Driver assistance computer: meo horizontal accuracy m";
CM_ SG_ 781 DAS_meoVerticalAccuracyM "Driver assistance computer: meo vertical accuracy m";
CM_ SG_ 781 DAS_meoHeadingAccuracyDeg "Driver assistance computer: meo heading accuracy deg";
CM_ SG_ 781 DAS_meoHeadingValid "Driver assistance computer: meo heading valid";
CM_ SG_ 781 DAS_meoNumSatellitesUsed "Driver assistance computer: meo num satellites used";
CM_ SG_ 781 DAS_meoGpsQualityLevel "Driver assistance computer: meo gps quality level";
CM_ SG_ 781 DAS_meoFixType "Driver assistance computer: meo fix type";
CM_ SG_ 781 DAS_meoResetCount "Driver assistance computer: meo reset count";
CM_ SG_ 781 DAS_lastMeoResetReason "Driver assistance computer: last meo reset reason";
CM_ SG_ 781 DAS_vioMultiGpsSelectedSource "Driver assistance computer: vio multi gps selected source";
CM_ SG_ 781 DAS_vioMultiGpsPeCooldownActive "Driver assistance computer: vio multi gps pe cooldown active";
CM_ SG_ 781 DAS_vioMultiGpsPeSppTdcpConsiste "Driver assistance computer: vio multi gps pe spp tdcp consistent with raw gps";
CM_ SG_ 781 DAS_vioMultiGpsPeMeoConsistentWi "Driver assistance computer: vio multi gps pe meo consistent with raw gps";
CM_ SG_ 781 DAS_vioMultiGpsPeSppTdcpVsR_0001 "Driver assistance computer: vio multi gps pe spp tdcp vs raw gps trans discrep m";
CM_ SG_ 781 DAS_vioMultiGpsPeMeoVsRawGpsTran "Driver assistance computer: vio multi gps pe meo vs raw gps trans discrep m";
CM_ SG_ 781 DAS_vioMultiGpsPeSppTdcpVsRawGps "Driver assistance computer: vio multi gps pe spp tdcp vs raw gps rot discrep deg";
CM_ SG_ 781 DAS_vioMultiGpsPeMeoVsRawGpsRotD "Driver assistance computer: vio multi gps pe meo vs raw gps rot discrep deg";
CM_ SG_ 781 DAS_publishedGpsSource "Driver assistance computer: published gps source";
CM_ SG_ 781 DAS_bluefinEnabled "Driver assistance computer: bluefin enabled";
CM_ SG_ 781 DAS_orioleDisabled "Driver assistance computer: oriole disabled";
CM_ SG_ 781 DAS_disableMonarch "Indicates the state of the Autopilot (AP) monarch positioning engine.";
CM_ BO_ 1548 "Driver assistance computer message: telemetry radar";
CM_ SG_ 1548 DAS_TR_ObjIndex "Driver assistance computer: TR obj index";
CM_ SG_ 1548 DAS_TR_Counter "Driver assistance computer: TR counter";
CM_ SG_ 1548 DAS_TR_Obj00_Class "Driver assistance computer: TR obj00 class";
CM_ SG_ 1548 DAS_TR_Obj00_Dx "Driver assistance computer: TR obj00 dx";
CM_ SG_ 1548 DAS_TR_Obj00_Dy "Driver assistance computer: TR obj00 dy";
CM_ SG_ 1548 DAS_TR_Obj00_Vx "Driver assistance computer: TR obj00 vx";
CM_ SG_ 1548 DAS_TR_Obj00_RCS "Driver assistance computer: TR obj00 RCS";
CM_ SG_ 1548 DAS_TR_Obj00_Length "Driver assistance computer: TR obj00 length";
CM_ SG_ 1548 DAS_TR_Obj00_MovingState "Driver assistance computer: TR obj00 moving state";
CM_ SG_ 1548 DAS_TR_Obj00_Dz "Driver assistance computer: TR obj00 dz";
CM_ SG_ 1548 DAS_TR_Obj00_Exist "Driver assistance computer: TR obj00 exist";
CM_ BO_ 1592 "Electric power steering (primary) message: uds response CH";
CM_ SG_ 1592 EPAS3P_udsResponseDataCH "Electric power steering (primary): uds response data CH";
CM_ BO_ 888 "Gateway message: e call";
CM_ SG_ 888 GTW_GTW_SOS_ECALL_RQST "State of the GTW-SOS-ECALL-RQST pin";
CM_ SG_ 888 GTW_LTE_ECALL_LOCK "State of the LTE-ECALL-LOCK pin";
CM_ BO_ 282 "Gateway message: adc4";
CM_ SG_ 282 GTW_BKP_BATT_MON "Gateway: BKP BATT MON; raw 4095 = signal not available (SNA)";
CM_ SG_ 282 GTW_BKP_BATT_NTC_P "BKP_BATT_NTC_P pni voltage; raw 4095 = signal not available (SNA)";
CM_ SG_ 282 GTW_ECALL_GPS_ANT_BIAS "Gateway: ECALL GPS ANT BIAS; raw 4095 = signal not available (SNA)";
CM_ SG_ 282 GTW_ECALL_MIC_DIAG "ECALL_MIC_DIAG voltage; raw 4095 = signal not available (SNA)";
CM_ SG_ 282 GTW_SOS_ECALL_nRQST_BUF "SOS_ECALL_nRQST_BUF voltage; raw 4095 = signal not available (SNA)";
CM_ BO_ 1384 "Gateway message: alert log";
CM_ SG_ 1384 GTW_alertID "Gateway: alert ID";
CM_ SG_ 1384 GTW_alertState "Gateway: alert state";
CM_ SG_ 1384 GTW_a014_crcVersion "Gateway: a014 crc version";
CM_ SG_ 1384 GTW_a015_crcVersion "Gateway: a015 crc version";
CM_ SG_ 1384 GTW_a016_crcVersion "Gateway: a016 crc version";
CM_ SG_ 1384 GTW_a017_crcVersion "Gateway: a017 crc version";
CM_ SG_ 1384 GTW_a018_crcVersion "Gateway: a018 crc version";
CM_ SG_ 1384 GTW_a019_crcVersion "Gateway: a019 crc version";
CM_ SG_ 1384 GTW_a020_crcVersion "Gateway: a020 crc version";
CM_ SG_ 1384 GTW_a021_crcVersion "Gateway: a021 crc version";
CM_ SG_ 1384 GTW_a022_crcVersion "Gateway: a022 crc version";
CM_ SG_ 1384 GTW_a023_crcVersion "Gateway: a023 crc version";
CM_ SG_ 1384 GTW_a024_crcVersion "Gateway: a024 crc version";
CM_ SG_ 1384 GTW_a025_crcVersion "Gateway: a025 crc version";
CM_ SG_ 1384 GTW_a026_crcVersion "Gateway: a026 crc version";
CM_ SG_ 1384 GTW_a027_crcVersion "Gateway: a027 crc version";
CM_ SG_ 1384 GTW_a028_crcVersion "Gateway: a028 crc version";
CM_ SG_ 1384 GTW_a029_crcVersion "Gateway: a029 crc version";
CM_ SG_ 1384 GTW_a030_crcVersion "Gateway: a030 crc version";
CM_ SG_ 1384 GTW_a031_crcVersion "Gateway: a031 crc version";
CM_ SG_ 1384 GTW_a032_crcVersion "Gateway: a032 crc version";
CM_ SG_ 1384 GTW_a033_crcVersion "Gateway: a033 crc version";
CM_ SG_ 1384 GTW_a034_crcVersion "Gateway: a034 crc version";
CM_ SG_ 1384 GTW_a035_crcVersion "Gateway: a035 crc version";
CM_ SG_ 1384 GTW_a036_crcVersion "Gateway: a036 crc version";
CM_ SG_ 1384 GTW_a037_crcVersion "Gateway: a037 crc version";
CM_ SG_ 1384 GTW_a038_crcVersion "Gateway: a038 crc version";
CM_ SG_ 1384 GTW_a039_crcVersion "Gateway: a039 crc version";
CM_ SG_ 1384 GTW_a040_crcVersion "Gateway: a040 crc version";
CM_ SG_ 1384 GTW_a041_crcVersion "Gateway: a041 crc version";
CM_ SG_ 1384 GTW_a042_crcVersion "Gateway: a042 crc version";
CM_ SG_ 1384 GTW_a043_crcVersion "Gateway: a043 crc version";
CM_ SG_ 1384 GTW_a045_crcVersion "Gateway: a045 crc version";
CM_ SG_ 1384 GTW_a046_crcVersion "Gateway: a046 crc version";
CM_ SG_ 1384 GTW_a047_crcVersion "Gateway: a047 crc version";
CM_ SG_ 1384 GTW_a048_crcVersion "Gateway: a048 crc version";
CM_ SG_ 1384 GTW_a049_headerError "Gateway: a049 header error";
CM_ SG_ 1384 GTW_a054_crcVersion "Gateway: a054 crc version";
CM_ SG_ 1384 GTW_a055_crcVersion "Gateway: a055 crc version";
CM_ SG_ 1384 GTW_a062_bmpWatchdogReason "Gateway: a062 bmp watchdog reason";
CM_ SG_ 1384 GTW_a063_VEH_faultConfinement "Gateway: a063 VEH fault confinement";
CM_ SG_ 1384 GTW_a064_CH_faultConfinement "Gateway: a064 CH fault confinement";
CM_ SG_ 1384 GTW_a065_PARTY_faultConfinement "Gateway: a065 PARTY fault confinement";
CM_ SG_ 1384 GTW_a066_type "Gateway: a066 type";
CM_ SG_ 1384 GTW_a066_exceptionCfgId "Gateway: a066 exception cfg id";
CM_ SG_ 1384 GTW_a066_uptime "Gateway: a066 uptime";
CM_ SG_ 1384 GTW_a066_core "Gateway: a066 core";
CM_ SG_ 1384 GTW_a068_codeKeyMissing "Gateway: a068 code key missing";
CM_ SG_ 1384 GTW_a068_cmdKeyMissing "Gateway: a068 cmd key missing";
CM_ SG_ 1384 GTW_a069_sdIntStatusErrs "Gateway: a069 sd int status errs";
CM_ SG_ 1384 GTW_a069_sdTimeout "Gateway: a069 sd timeout";
CM_ SG_ 1384 GTW_a069_sdCmdErr "Gateway: a069 sd cmd err";
CM_ SG_ 1384 GTW_a069_sdWriteErr "Gateway: a069 sd write err";
CM_ SG_ 1384 GTW_a069_sdReadErr "Gateway: a069 sd read err";
CM_ SG_ 1384 GTW_a069_autoCmd12Err "Gateway: a069 auto cmd12 err";
CM_ SG_ 1384 GTW_a072_updtFailureMask "Gateway: a072 updt failure mask";
CM_ SG_ 1384 GTW_a073_SOCResetRequestor "Gateway: a073 SOC reset requestor";
CM_ SG_ 1384 GTW_a077_bmpPmicErrorType "Gateway: a077 bmp pmic error type";
CM_ SG_ 1384 GTW_a097_crcVersion "Gateway: a097 crc version";
CM_ SG_ 1384 GTW_a098_crcVersion "Gateway: a098 crc version";
CM_ SG_ 1384 GTW_a099_crcVersion "Gateway: a099 crc version";
CM_ SG_ 1384 GTW_a100_crcVersion "Gateway: a100 crc version";
CM_ SG_ 1384 GTW_a101_switchStuck "Gateway: a101 switch stuck";
CM_ SG_ 1384 GTW_a101_ETH_SW_nINT "Gateway: a101 ETH SW n INT";
CM_ SG_ 1384 GTW_a106_crcVersion "Gateway: a106 crc version";
CM_ SG_ 1384 GTW_a107_crcVersion "Gateway: a107 crc version";
CM_ SG_ 1384 GTW_a108_crcVersion "Gateway: a108 crc version";
CM_ SG_ 1384 GTW_a117_MC_RGM_DES "Gateway: a117 MC RGM DES";
CM_ SG_ 1384 GTW_a118_MC_RGM_FES "Gateway: a118 MC RGM FES";
CM_ SG_ 1384 GTW_a122_BDY_faultConfinement "Gateway: a122 BDY fault confinement";
CM_ SG_ 1384 GTW_a129_crcVersion "Gateway: a129 crc version";
CM_ SG_ 1384 GTW_a138_sdLifetimeUsed "Gateway: a138 sd lifetime used";
CM_ SG_ 1384 GTW_a139_crcVersion "Gateway: a139 crc version";
CM_ SG_ 1384 GTW_a150_crcVersion "Gateway: a150 crc version";
CM_ SG_ 1384 GTW_a151_crcVersion "Gateway: a151 crc version";
CM_ SG_ 1384 GTW_a155_crcVersion "Gateway: a155 crc version";
CM_ SG_ 1384 GTW_a164_crcVersion "Gateway: a164 crc version";
CM_ SG_ 1384 GTW_a165_crcVersion "Gateway: a165 crc version";
CM_ SG_ 1384 GTW_a169_TPMS_pressureFL "Gateway: a169 TPMS pressure FL";
CM_ SG_ 1384 GTW_a170_TPMS_pressureFR "Gateway: a170 TPMS pressure FR";
CM_ SG_ 1384 GTW_a171_TPMS_pressureRL "Gateway: a171 TPMS pressure RL";
CM_ SG_ 1384 GTW_a172_TPMS_pressureRR "Gateway: a172 TPMS pressure RR";
CM_ SG_ 1384 GTW_a173_TPMS_pressureFL "Gateway: a173 TPMS pressure FL";
CM_ SG_ 1384 GTW_a174_TPMS_pressureFR "Gateway: a174 TPMS pressure FR";
CM_ SG_ 1384 GTW_a175_TPMS_pressureRL "Gateway: a175 TPMS pressure RL";
CM_ SG_ 1384 GTW_a176_TPMS_pressureRR "Gateway: a176 TPMS pressure RR";
CM_ SG_ 1384 GTW_a219_crcVersion "Gateway: a219 crc version";
CM_ SG_ 1384 GTW_a223_crcVersion "Gateway: a223 crc version";
CM_ SG_ 1384 GTW_a226_crcVersion "Gateway: a226 crc version";
CM_ SG_ 1384 GTW_a227_crcVersion "Gateway: a227 crc version";
CM_ SG_ 1384 GTW_a228_crcVersion "Gateway: a228 crc version";
CM_ SG_ 1384 GTW_a244_crcVersion "Gateway: a244 crc version";
CM_ SG_ 1384 GTW_a245_page0ControlValue "Gateway: a245 page0 control value";
CM_ SG_ 1384 GTW_a245_page1ControlValue "Gateway: a245 page1 control value";
CM_ SG_ 1384 GTW_a261_failureReason "Gateway: a261 failure reason";
CM_ SG_ 1384 GTW_a261_failureData1 "Gateway: a261 failure data1";
CM_ SG_ 1384 GTW_a261_failureData2 "Gateway: a261 failure data2";
CM_ SG_ 1384 GTW_a273_crcVersion "Gateway: a273 crc version";
CM_ SG_ 1384 GTW_a274_crcVersion "Gateway: a274 crc version";
CM_ SG_ 1384 GTW_a277_mitigationFailureReason "Gateway: a277 mitigation failure reason";
CM_ SG_ 1384 GTW_a279_repeatCount "Gateway: a279 repeat count";
CM_ SG_ 1384 GTW_a279_failureReason "Gateway: a279 failure reason";
CM_ SG_ 1384 GTW_a279_failureData1 "Gateway: a279 failure data1";
CM_ SG_ 1384 GTW_a279_failureData2 "Gateway: a279 failure data2";
CM_ SG_ 1384 GTW_a309_crcVersion "Gateway: a309 crc version";
CM_ SG_ 1384 GTW_a317_status "Gateway: a317 status";
CM_ SG_ 1384 GTW_a317_errorCode "Gateway: a317 error code";
CM_ SG_ 1384 GTW_a329_crcVersion "Gateway: a329 crc version";
CM_ SG_ 1384 GTW_a330_crcVersion "Gateway: a330 crc version";
CM_ SG_ 1384 GTW_a331_crcVersion "Gateway: a331 crc version";
CM_ SG_ 1384 GTW_a342_crcVersion "Gateway: a342 crc version";
CM_ SG_ 1384 GTW_a348_crcVersion "Gateway: a348 crc version";
CM_ SG_ 1384 GTW_a349_crcVersion "Gateway: a349 crc version";
CM_ SG_ 1384 GTW_a354_crcVersion "Gateway: a354 crc version";
CM_ SG_ 1384 GTW_a355_crcVersion "Gateway: a355 crc version";
CM_ SG_ 1384 GTW_a358_crcVersion "Gateway: a358 crc version";
CM_ SG_ 1384 GTW_a359_crcVersion "Gateway: a359 crc version";
CM_ SG_ 1384 GTW_a360_crcVersion "Gateway: a360 crc version";
CM_ SG_ 1384 GTW_a361_crcVersion "Gateway: a361 crc version";
CM_ SG_ 1384 GTW_a362_crcVersion "Gateway: a362 crc version";
CM_ SG_ 1384 GTW_a363_crcVersion "Gateway: a363 crc version";
CM_ SG_ 1384 GTW_a364_crcVersion "Gateway: a364 crc version";
CM_ SG_ 1384 GTW_a380_crcVersion "Gateway: a380 crc version";
CM_ SG_ 1384 GTW_a381_crcVersion "Gateway: a381 crc version";
CM_ SG_ 1384 GTW_a382_crcVersion "Gateway: a382 crc version";
CM_ SG_ 1384 GTW_a383_crcVersion "Gateway: a383 crc version";
CM_ SG_ 1384 GTW_a384_crcVersion "Gateway: a384 crc version";
CM_ SG_ 1384 GTW_a385_crcVersion "Gateway: a385 crc version";
CM_ SG_ 1384 GTW_a386_crcVersion "Gateway: a386 crc version";
CM_ SG_ 1384 GTW_a394_crcVersion "Gateway: a394 crc version";
CM_ SG_ 1384 GTW_a401_crcVersion "Gateway: a401 crc version";
CM_ SG_ 1384 GTW_a402_crcVersion "Gateway: a402 crc version";
CM_ SG_ 1384 GTW_a409_RES_CAUSE "Gateway: a409 RES CAUSE";
CM_ SG_ 1384 GTW_a410_RES_CAUSE2 "Gateway: a410 RES CAUSE2";
CM_ SG_ 1384 GTW_a418_crcVersion "Gateway: a418 crc version";
CM_ SG_ 1384 GTW_a427_crcVersion "Gateway: a427 crc version";
CM_ SG_ 1384 GTW_a428_crcVersion "Gateway: a428 crc version";
CM_ SG_ 1384 GTW_a429_crcVersion "Gateway: a429 crc version";
CM_ SG_ 1384 GTW_a439_crcVersion "Gateway: a439 crc version";
CM_ BO_ 62 "Gateway message: alert matrix";
CM_ SG_ 62 GTW_matrixIndex "Gateway: matrix index";
CM_ SG_ 62 GTW_w001_canEthTxQueue "Gateway: w001 can eth tx queue";
CM_ SG_ 62 GTW_w002_taskError "Gateway: w002 task error";
CM_ SG_ 62 GTW_w003_logWriteRecord "Gateway: w003 log write record";
CM_ SG_ 62 GTW_w004_mallocHook "Gateway: w004 malloc hook";
CM_ SG_ 62 GTW_w005_stackOverflowHook "Gateway: w005 stack overflow hook";
CM_ SG_ 62 GTW_w006_ifTxOutputFull "Gateway: w006 if tx output full";
CM_ SG_ 62 GTW_w007_ifRxBufError "Gateway: w007 if rx buf error";
CM_ SG_ 62 GTW_w008_ifPbufAllocError "Gateway: w008 if pbuf alloc error";
CM_ SG_ 62 GTW_w009_lateTask "Gateway: w009 late task";
CM_ SG_ 62 GTW_w010_wdTaskCount "Gateway: w010 wd task count";
CM_ SG_ 62 GTW_w011_cancoreWatchdog "Gateway: w011 cancore watchdog";
CM_ SG_ 62 GTW_w012_maincoreWatchdog "Gateway: w012 maincore watchdog";
CM_ SG_ 62 GTW_w014_APSversionMismatch "Gateway: w014 AP sversion mismatch";
CM_ SG_ 62 GTW_w015_DIFversionMismatch "Gateway: w015 DI fversion mismatch";
CM_ SG_ 62 GTW_w016_BLEEPCENTERversionMisma "Gateway: w016 BLEEPCENTE rversion mismatch";
CM_ SG_ 62 GTW_w017_BMSversionMismatch "Gateway: w017 BM sversion mismatch";
CM_ SG_ 62 GTW_w018_CMPversionMismatch "Gateway: w018 CM pversion mismatch";
CM_ SG_ 62 GTW_w019_CPversionMismatch "Gateway: w019 c pversion mismatch";
CM_ SG_ 62 GTW_w020_DIRversionMismatch "Gateway: w020 DI rversion mismatch";
CM_ SG_ 62 GTW_w021_EPAS3PversionMismatch "Gateway: w021 EPAS3 pversion mismatch";
CM_ SG_ 62 GTW_w022_EPBLversionMismatch "Gateway: w022 EPB lversion mismatch";
CM_ SG_ 62 GTW_w023_EPBRversionMismatch "Gateway: w023 EPB rversion mismatch";
CM_ SG_ 62 GTW_w024_ESPversionMismatch "Gateway: w024 ES pversion mismatch";
CM_ SG_ 62 GTW_w025_ESPCALversionMismatch "Gateway: w025 ESPCA lversion mismatch";
CM_ SG_ 62 GTW_w026_GTWversionMismatch "Gateway: w026 GT wversion mismatch";
CM_ SG_ 62 GTW_w027_HVPversionMismatch "Gateway: w027 HV pversion mismatch";
CM_ SG_ 62 GTW_w028_IBSTversionMismatch "Gateway: w028 IBS tversion mismatch";
CM_ SG_ 62 GTW_w029_IBSTCALversionMismatch "Gateway: w029 IBSTCA lversion mismatch";
CM_ SG_ 62 GTW_w030_OCS1PversionMismatch "Gateway: w030 OCS1 pversion mismatch";
CM_ SG_ 62 GTW_w031_PARKversionMismatch "Gateway: w031 PAR kversion mismatch";
CM_ SG_ 62 GTW_w032_PCSversionMismatch "Gateway: w032 PC sversion mismatch";
CM_ SG_ 62 GTW_w033_PCSCPU2versionMismatch "Gateway: w033 pcscpu2version mismatch";
CM_ SG_ 62 GTW_w034_PMRversionMismatch "Gateway: w034 PM rversion mismatch";
CM_ SG_ 62 GTW_w035_PMFversionMismatch "Gateway: w035 PM fversion mismatch";
CM_ SG_ 62 GTW_w036_PTCversionMismatch "Gateway: w036 PT cversion mismatch";
CM_ SG_ 62 GTW_w037_RADCversionMismatch "Gateway: w037 RAD cversion mismatch";
CM_ SG_ 62 GTW_w038_RCMversionMismatch "Gateway: w038 RC mversion mismatch";
CM_ SG_ 62 GTW_w039_RCMCALversionMismatch "Gateway: w039 RCMCA lversion mismatch";
CM_ SG_ 62 GTW_w040_SCCMversionMismatch "Gateway: w040 SCC mversion mismatch";
CM_ SG_ 62 GTW_w041_VCSECversionMismatch "Gateway: w041 VCSE cversion mismatch";
CM_ SG_ 62 GTW_w042_TASversionMismatch "Gateway: w042 TA sversion mismatch";
CM_ SG_ 62 GTW_w043_THSversionMismatch "Gateway: w043 TH sversion mismatch";
CM_ SG_ 62 GTW_w045_VCFRONTversionMismatch "Gateway: w045 VCFRON tversion mismatch";
CM_ SG_ 62 GTW_w046_VCLEFTversionMismatch "Gateway: w046 VCLEF tversion mismatch";
CM_ SG_ 62 GTW_w047_VCRIGHTversionMismatch "Gateway: w047 VCRIGH tversion mismatch";
CM_ SG_ 62 GTW_w048_EPAS3SversionMismatch "Gateway: w048 EPAS3 sversion mismatch";
CM_ SG_ 62 GTW_w049_corruptedManifest "Gateway: w049 corrupted manifest";
CM_ SG_ 62 GTW_w050_sdCardInitFailure "Gateway: w050 sd card init failure";
CM_ SG_ 62 GTW_w051_sdCardFileSystemFailure "Gateway: w051 sd card file system failure";
CM_ SG_ 62 GTW_w052_ifTxSpans "Gateway: w052 if tx spans";
CM_ SG_ 62 GTW_w053_busSleepFailure "Gateway: w053 bus sleep failure";
CM_ SG_ 62 GTW_w054_OPCRversionMismatch "Gateway: w054 OPC rversion mismatch";
CM_ SG_ 62 GTW_w055_OPCFversionMismatch "Gateway: w055 OPC fversion mismatch";
CM_ SG_ 62 GTW_w057_i2cFailure "Gateway: w057 i2c failure";
CM_ SG_ 62 GTW_w058_rtcAlarmFailure "Gateway: w058 rtc alarm failure";
CM_ SG_ 62 GTW_w059_inFactoryMode "Gateway: w059 in factory mode";
CM_ SG_ 62 GTW_w060_unFused "Gateway: w060 un fused";
CM_ SG_ 62 GTW_w061_bmpSleepFailure "Gateway: w061 bmp sleep failure";
CM_ SG_ 62 GTW_w062_bmpWatchdog "Gateway: w062 bmp watchdog";
CM_ SG_ 62 GTW_w063_VEH_canFault "Gateway: w063 VEH can fault";
CM_ SG_ 62 GTW_w064_CH_canFault "Gateway: w064 CH can fault";
CM_ SG_ 62 GTW_w065_PARTY_canFault "Gateway: w065 PARTY can fault";
CM_ SG_ 62 GTW_w066_exception "Gateway: w066 exception";
CM_ SG_ 62 GTW_w067_tcpDebug "Gateway: w067 tcp debug";
CM_ SG_ 62 GTW_w068_prodKeyMissing "Gateway: w068 prod key missing";
CM_ SG_ 62 GTW_w069_diskioErr "Gateway: w069 diskio err";
CM_ SG_ 62 GTW_w070_hrlDump "Gateway: w070 hrl dump";
CM_ SG_ 62 GTW_w071_hrlTrigger "Gateway: w071 hrl trigger";
CM_ SG_ 62 GTW_w072_updateFailure "Gateway: w072 update failure";
CM_ SG_ 62 GTW_w073_steeringWheelReset "Gateway: w073 steering wheel reset";
CM_ SG_ 62 GTW_w074_epas3pMIA "Gateway: w074 epas3p MIA";
CM_ SG_ 62 GTW_w075_epas3sMIA "Gateway: w075 epas3s MIA";
CM_ SG_ 62 GTW_w076_ethInterfaceReset "Gateway: w076 eth interface reset";
CM_ SG_ 62 GTW_w077_bmpPmicError "Gateway: w077 bmp pmic error";
CM_ SG_ 62 GTW_w078_VEHbusOverloaded "Gateway: w078 VE hbus overloaded";
CM_ SG_ 62 GTW_w079_PARTYbusOverloaded "Gateway: w079 PART ybus overloaded";
CM_ SG_ 62 GTW_w080_CHbusOverloaded "Gateway: w080 c hbus overloaded";
CM_ SG_ 62 GTW_w081_udsMessageRejected "Gateway: w081 uds message rejected";
CM_ SG_ 62 GTW_w082_sdCardBSCorrupted "Gateway: w082 sd card BS corrupted";
CM_ SG_ 62 GTW_w083_udsMsgDroppedByTcpStack "Gateway: w083 uds msg dropped by tcp stack";
CM_ SG_ 62 GTW_w084_canFrameDropped "Gateway: w084 can frame dropped";
CM_ SG_ 62 GTW_w085_fuseStateUnknown "Gateway: w085 fuse state unknown";
CM_ SG_ 62 GTW_w086_ocu "Gateway: w086 ocu";
CM_ SG_ 62 GTW_w087_ocuInProgress "Gateway: w087 ocu in progress";
CM_ SG_ 62 GTW_w088_sdCardInvReqParallel "Gateway: w088 sd card inv req parallel";
CM_ SG_ 62 GTW_w089_sdCardWatchdog "Gateway: w089 sd card watchdog";
CM_ SG_ 62 GTW_w090_ocuFailed "Gateway: w090 ocu failed";
CM_ SG_ 62 GTW_w091_lowStack "Gateway: w091 low stack";
CM_ SG_ 62 GTW_w092_sdCardInvReqZero "Gateway: w092 sd card inv req zero";
CM_ SG_ 62 GTW_w093_sdCardInvReqOverflowBas "Gateway: w093 sd card inv req overflow base";
CM_ SG_ 62 GTW_w094_sdCardInvReqOverflowCou "Gateway: w094 sd card inv req overflow count";
CM_ SG_ 62 GTW_w095_sdCardFull "Gateway: w095 sd card full";
CM_ SG_ 62 GTW_w096_sdCardFatCorrupted "Gateway: w096 sd card fat corrupted";
CM_ SG_ 62 GTW_w097_HCMLversionMismatch "Gateway: w097 HCM lversion mismatch";
CM_ SG_ 62 GTW_w098_HCMRversionMismatch "Gateway: w098 HCM rversion mismatch";
CM_ SG_ 62 GTW_w099_SWCversionMismatch "Gateway: w099 SW cversion mismatch";
CM_ SG_ 62 GTW_w100_CBCversionMismatch "Gateway: w100 CB cversion mismatch";
CM_ SG_ 62 GTW_w101_switchWatchdog "Gateway: w101 switch watchdog";
CM_ SG_ 62 GTW_w103_sdCardFormatted "Gateway: w103 sd card formatted";
CM_ SG_ 62 GTW_w104_sdCardDriverArgCorrupte "Gateway: w104 sd card driver arg corrupted";
CM_ SG_ 62 GTW_w105_eBuckConfigured "Gateway: w105 e buck configured";
CM_ SG_ 62 GTW_w106_BLEEPLEFTversionMismatc "Gateway: w106 BLEEPLEF tversion mismatch";
CM_ SG_ 62 GTW_w107_BLEEPRIGHTversionMismat "Gateway: w107 BLEEPRIGH tversion mismatch";
CM_ SG_ 62 GTW_w108_BLEEPREARversionMismatc "Gateway: w108 BLEEPREA rversion mismatch";
CM_ SG_ 62 GTW_w109_failedToStartUpdater "Gateway: w109 failed to start updater";
CM_ SG_ 62 GTW_w110_readMdioFailed "Gateway: w110 read mdio failed";
CM_ SG_ 62 GTW_w111_writeMdioFailed "Gateway: w111 write mdio failed";
CM_ SG_ 62 GTW_w112_z4bDisabled "Gateway: w112 z4b disabled";
CM_ SG_ 62 GTW_w113_unrecognizedCanMessage "Gateway: w113 unrecognized can message";
CM_ SG_ 62 GTW_w114_updtRetried "Gateway: w114 updt retried";
CM_ SG_ 62 GTW_w115_hrlEventFileAvail "Gateway: w115 hrl event file avail";
CM_ SG_ 62 GTW_w116_switchInitFailed "Gateway: w116 switch init failed";
CM_ SG_ 62 GTW_w117_unexpectedDestructiveRe "Gateway: w117 unexpected destructive reset status";
CM_ SG_ 62 GTW_w118_unexpectedFunctionalRes "Gateway: w118 unexpected functional reset status";
CM_ SG_ 62 GTW_w120_switchUnlocked "Gateway: w120 switch unlocked";
CM_ SG_ 62 GTW_w122_BDY_canFault "Gateway: w122 BDY can fault";
CM_ SG_ 62 GTW_w123_BDYbusOverloaded "Gateway: w123 BD ybus overloaded";
CM_ SG_ 62 GTW_w125_switchReplayUnlocked "Gateway: w125 switch replay unlocked";
CM_ SG_ 62 GTW_w127_noFilePointersAvailable "Gateway: w127 no file pointers available";
CM_ SG_ 62 GTW_w129_ICRversionMismatch "Gateway: w129 IC rversion mismatch";
CM_ SG_ 62 GTW_w133_adspFaultDetected "Gateway: w133 adsp fault detected";
CM_ SG_ 62 GTW_w134_disableFeatureFailed "Gateway: w134 disable feature failed";
CM_ SG_ 62 GTW_w135_canLogQueueFull "Gateway: w135 can log queue full";
CM_ SG_ 62 GTW_w136_hrlGameModeFileAvail "Gateway: w136 hrl game mode file avail";
CM_ SG_ 62 GTW_w137_lowHeap "Gateway: w137 low heap";
CM_ SG_ 62 GTW_w138_sdCardEndOfLife "Gateway: w138 sd card end of life";
CM_ SG_ 62 GTW_w139_CMPDversionMismatch "Gateway: w139 CMP dversion mismatch";
CM_ SG_ 62 GTW_w140_cancoreHeartbeat "Gateway: w140 cancore heartbeat";
CM_ SG_ 62 GTW_w141_teleCANETHis "Gateway: w141 tele CANET his";
CM_ SG_ 62 GTW_w143_possibleCanWakeIssue "Gateway: w143 possible can wake issue";
CM_ SG_ 62 GTW_w144_hrlStateMachine "Gateway: w144 hrl state machine";
CM_ SG_ 62 GTW_w145_carConfigsNotWritten "Gateway: w145 car configs not written";
CM_ SG_ 62 GTW_w146_performancePackageMisma "Gateway: w146 performance package mismatch";
CM_ SG_ 62 GTW_w147_updateAbortFor12v "Gateway: w147 update abort for12v";
CM_ SG_ 62 GTW_w149_rtcTimeSetInPast "Gateway: w149 rtc time set in past";
CM_ SG_ 62 GTW_w150_HCM3LversionMismatch "Gateway: w150 HCM3 lversion mismatch";
CM_ SG_ 62 GTW_w151_HCM3RversionMismatch "Gateway: w151 HCM3 rversion mismatch";
CM_ SG_ 62 GTW_w153_externalRtcAlarmFailure "Gateway: w153 external rtc alarm failure";
CM_ SG_ 62 GTW_w155_PMversionMismatch "Gateway: w155 p mversion mismatch";
CM_ SG_ 62 GTW_w164_VCBATTversionMismatch "Gateway: w164 VCBAT tversion mismatch";
CM_ SG_ 62 GTW_w165_USMversionMismatch "Gateway: w165 US mversion mismatch";
CM_ SG_ 62 GTW_w166_nErrCanFaultVeh "Gateway: w166 n err can fault veh";
CM_ SG_ 62 GTW_w167_nErrCanFaultCh "Gateway: w167 n err can fault ch";
CM_ SG_ 62 GTW_w168_nErrCanFaultParty "Gateway: w168 n err can fault party";
CM_ SG_ 62 GTW_w169_TPMSsoftWarnFrontLeft "Gateway: w169 TPM ssoft warn front left";
CM_ SG_ 62 GTW_w170_TPMSsoftWarnFrontRight "Gateway: w170 TPM ssoft warn front right";
CM_ SG_ 62 GTW_w171_TPMSsoftWarnRearLeft "Gateway: w171 TPM ssoft warn rear left";
CM_ SG_ 62 GTW_w172_TPMSsoftWarnRearRight "Gateway: w172 TPM ssoft warn rear right";
CM_ SG_ 62 GTW_w173_TPMShardWarnFrontLeft "Gateway: w173 TPM shard warn front left";
CM_ SG_ 62 GTW_w174_TPMShardWarnFrontRight "Gateway: w174 TPM shard warn front right";
CM_ SG_ 62 GTW_w175_TPMShardWarnRearLeft "Gateway: w175 TPM shard warn rear left";
CM_ SG_ 62 GTW_w176_TPMShardWarnRearRight "Gateway: w176 TPM shard warn rear right";
CM_ SG_ 62 GTW_w186_swrPrecaution "Gateway: w186 swr precaution";
CM_ SG_ 62 GTW_w218_switchOTPIncorrect "Gateway: w218 switch OTP incorrect";
CM_ SG_ 62 GTW_w219_CMPSversionMismatch "Gateway: w219 CMP sversion mismatch";
CM_ SG_ 62 GTW_w223_LVBMSversionMismatch "Gateway: w223 LVBM sversion mismatch";
CM_ SG_ 62 GTW_w224_sdCardUpgradeNeeded "Gateway: w224 sd card upgrade needed";
CM_ SG_ 62 GTW_w225_resetOnSleepWake "Gateway: w225 reset on sleep wake";
CM_ SG_ 62 GTW_w226_DISPversionMismatch "Gateway: w226 DIS pversion mismatch";
CM_ SG_ 62 GTW_w227_DISPTOUCHversionMismatc "Gateway: w227 DISPTOUC hversion mismatch";
CM_ SG_ 62 GTW_w228_DISPOSDversionMismatch "Gateway: w228 DISPOS dversion mismatch";
CM_ SG_ 62 GTW_w229_displaySoftsetConnectio "Gateway: w229 display softset connection";
CM_ SG_ 62 GTW_w230_touchInterruptStorm "Gateway: w230 touch interrupt storm";
CM_ SG_ 62 GTW_w244_SDCRversionMismatch "Gateway: w244 SDC rversion mismatch";
CM_ SG_ 62 GTW_w245_apsNotDisabled "Gateway: w245 aps not disabled";
CM_ SG_ 62 GTW_w246_touchcoreHeartbeat "Gateway: w246 touchcore heartbeat";
CM_ SG_ 62 GTW_w255_rtc32KHzWatchdog "Gateway: w255 rtc32 k hz watchdog";
CM_ SG_ 62 GTW_w260_unknownPN "Gateway: w260 unknown PN";
CM_ SG_ 62 GTW_w261_adspWatchdog "Gateway: w261 adsp watchdog";
CM_ SG_ 62 GTW_w262_canLogBlockDropped "Gateway: w262 can log block dropped";
CM_ SG_ 62 GTW_w263_hrlUdpFileAvail "Gateway: w263 hrl udp file avail";
CM_ SG_ 62 GTW_w264_hrlPseudoFileAvail "Gateway: w264 hrl pseudo file avail";
CM_ SG_ 62 GTW_w265_optionFlagsError "Gateway: w265 option flags error";
CM_ SG_ 62 GTW_w266_dpp1MIA "Gateway: w266 dpp1 MIA";
CM_ SG_ 62 GTW_w267_dpp2MIA "Gateway: w267 dpp2 MIA";
CM_ SG_ 62 GTW_w268_stoMIA "Gateway: w268 sto MIA";
CM_ SG_ 62 GTW_w273_BLEEPREARLEFTversionMis "Gateway: w273 BLEEPREARLEF tversion mismatch";
CM_ SG_ 62 GTW_w274_BLEEPREARRIGHTversionMi "Gateway: w274 BLEEPREARRIGH tversion mismatch";
CM_ SG_ 62 GTW_w275_VDDCORE_DrMOS_Fault "Gateway: w275 VDDCORE dr MOS fault";
CM_ SG_ 62 GTW_w276_VDDSOC_DrMOS_Fault "Gateway: w276 VDDSOC dr MOS fault";
CM_ SG_ 62 GTW_w277_NonRevCDrMOSMitigationF "Gateway: w277 non rev c dr MOS mitigation failed";
CM_ SG_ 62 GTW_w278_ethSwitchCongested "Gateway: w278 eth switch congested";
CM_ SG_ 62 GTW_w279_adspRepeatedWatchdog "Gateway: w279 adsp repeated watchdog";
CM_ SG_ 62 GTW_w280_hrlFrameDropped "Gateway: w280 hrl frame dropped";
CM_ SG_ 62 GTW_w281_likelyMissedPoke "Gateway: w281 likely missed poke";
CM_ SG_ 62 GTW_w282_tcuPhyConfigurationFail "Gateway: w282 tcu phy configuration failed";
CM_ SG_ 62 GTW_w309_VCUSBversionMismatch "Gateway: w309 VCUS bversion mismatch";
CM_ SG_ 62 GTW_w311_canLogQueueFullBeforeFs "Gateway: w311 can log queue full before fs init";
CM_ SG_ 62 GTW_w312_hrlFileIncomplete "Gateway: w312 hrl file incomplete";
CM_ SG_ 62 GTW_w313_OSDActive "Gateway: w313 OSD active";
CM_ SG_ 62 GTW_w314_canLogBlockWriteErr "Gateway: w314 can log block write err";
CM_ SG_ 62 GTW_w316_sdCardChkdskRepair "Gateway: w316 sd card chkdsk repair";
CM_ SG_ 62 GTW_w317_sdCardChkdskRepairFaile "Gateway: w317 sd card chkdsk repair failed";
CM_ SG_ 62 GTW_w322_gestureUnrecognizedFrom "Gateway: w322 gesture unrecognized from moving";
CM_ SG_ 62 GTW_w323_gestureStartOutOfStrip "Gateway: w323 gesture start out of strip";
CM_ SG_ 62 GTW_w328_smartShiftDisabled "Gateway: w328 smart shift disabled";
CM_ SG_ 62 GTW_w329_FOHMversionMismatch "Gateway: w329 FOH mversion mismatch";
CM_ SG_ 62 GTW_w330_SWSLversionMismatch "Gateway: w330 SWS lversion mismatch";
CM_ SG_ 62 GTW_w331_SWSRversionMismatch "Gateway: w331 SWS rversion mismatch";
CM_ SG_ 62 GTW_w332_unknownDisplayPN "Gateway: w332 unknown display PN";
CM_ SG_ 62 GTW_w334_hrlFolderSpaceLow "Gateway: w334 hrl folder space low";
CM_ SG_ 62 GTW_w336_possibleCanTxIssue "Gateway: w336 possible can tx issue";
CM_ SG_ 62 GTW_w342_VCBLDCPPversionMismatch "Gateway: w342 VCBLDCP pversion mismatch";
CM_ SG_ 62 GTW_w348_VCBLDCFversionMismatch "Gateway: w348 VCBLDC fversion mismatch";
CM_ SG_ 62 GTW_w349_VCBLDCPBversionMismatch "Gateway: w349 VCBLDCP bversion mismatch";
CM_ SG_ 62 GTW_w350_mOSDCrcCheck "Gateway: w350 m OSD crc check";
CM_ SG_ 62 GTW_w351_sOSDCrcCheck "Gateway: w351 s OSD crc check";
CM_ SG_ 62 GTW_w352_mASILStatusCheck "Gateway: w352 m ASIL status check";
CM_ SG_ 62 GTW_w353_sASILStatusCheck "Gateway: w353 s ASIL status check";
CM_ SG_ 62 GTW_w354_EPASTPversionMismatch "Gateway: w354 EPAST pversion mismatch";
CM_ SG_ 62 GTW_w355_EPASTSversionMismatch "Gateway: w355 EPAST sversion mismatch";
CM_ SG_ 62 GTW_w356_touchGPIOStatusCheck "Gateway: w356 touch GPIO status check";
CM_ SG_ 62 GTW_w358_RGBIPFLversionMismatch "Gateway: w358 RGBIPF lversion mismatch";
CM_ SG_ 62 GTW_w359_RGBIPFRversionMismatch "Gateway: w359 RGBIPF rversion mismatch";
CM_ SG_ 62 GTW_w360_RGBDOORFLversionMismatc "Gateway: w360 RGBDOORF lversion mismatch";
CM_ SG_ 62 GTW_w361_RGBDOORRLversionMismatc "Gateway: w361 RGBDOORR lversion mismatch";
CM_ SG_ 62 GTW_w362_RGBDOORFRversionMismatc "Gateway: w362 RGBDOORF rversion mismatch";
CM_ SG_ 62 GTW_w363_RGBDOORRRversionMismatc "Gateway: w363 RGBDOORR rversion mismatch";
CM_ SG_ 62 GTW_w364_BLEEPCRADLEversionMisma "Gateway: w364 BLEEPCRADL eversion mismatch";
CM_ SG_ 62 GTW_w366_uiGearRequestMismatch "Gateway: w366 ui gear request mismatch";
CM_ SG_ 62 GTW_w376_blFailedToExecBootImg "Gateway: w376 bl failed to exec boot img";
CM_ SG_ 62 GTW_w380_DPBversionMismatch "Gateway: w380 DP bversion mismatch";
CM_ SG_ 62 GTW_w381_DPBCALversionMismatch "Gateway: w381 DPBCA lversion mismatch";
CM_ SG_ 62 GTW_w382_IDBversionMismatch "Gateway: w382 ID bversion mismatch";
CM_ SG_ 62 GTW_w383_IDB1versionMismatch "Gateway: w383 idb1version mismatch";
CM_ SG_ 62 GTW_w384_IDBCALversionMismatch "Gateway: w384 IDBCA lversion mismatch";
CM_ SG_ 62 GTW_w385_RCUversionMismatch "Gateway: w385 RC uversion mismatch";
CM_ SG_ 62 GTW_w386_RCUCALversionMismatch "Gateway: w386 RCUCA lversion mismatch";
CM_ SG_ 62 GTW_w387_externalRtcReadFailure "Gateway: w387 external rtc read failure";
CM_ SG_ 62 GTW_w388_adspWatchdogSkipped "Gateway: w388 adsp watchdog skipped";
CM_ SG_ 62 GTW_w389_rcmEventDetected "Gateway: w389 rcm event detected";
CM_ SG_ 62 GTW_w390_displayFwQueryFailed "Gateway: w390 display fw query failed";
CM_ SG_ 62 GTW_w391_adspMacAddrCheckFailed "Gateway: w391 adsp mac addr check failed";
CM_ SG_ 62 GTW_w393_osdSramCrcMismatch "Gateway: w393 osd sram crc mismatch";
CM_ SG_ 62 GTW_w394_WIPERversionMismatch "Gateway: w394 WIPE rversion mismatch";
CM_ SG_ 62 GTW_w395_lwipIcmpError "Gateway: w395 lwip icmp error";
CM_ SG_ 62 GTW_w396_alreadyInReverse "Gateway: w396 already in reverse";
CM_ SG_ 62 GTW_w397_alreadyInDrive "Gateway: w397 already in drive";
CM_ SG_ 62 GTW_w398_awakeForExtendedTime "Gateway: w398 awake for extended time";
CM_ SG_ 62 GTW_w399_ethIfRxTcpipQueueDrop "Gateway: w399 eth if rx tcpip queue drop";
CM_ SG_ 62 GTW_w400_ethlSwitchOTPIncorrect "Gateway: w400 ethl switch OTP incorrect";
CM_ SG_ 62 GTW_w401_VCSEAT2LversionMismatch "Gateway: w401 VCSEAT2 lversion mismatch";
CM_ SG_ 62 GTW_w402_VCSEAT2RversionMismatch "Gateway: w402 VCSEAT2 rversion mismatch";
CM_ SG_ 62 GTW_w409_unexpectedResetCause "Gateway: w409 unexpected reset cause";
CM_ SG_ 62 GTW_w410_unexpectedResetCause2 "Gateway: w410 unexpected reset cause2";
CM_ SG_ 62 GTW_w411_tASILStatusCheck "Gateway: w411 t ASIL status check";
CM_ SG_ 62 GTW_w414_socHeldInReset "Gateway: w414 soc held in reset";
CM_ SG_ 62 GTW_w418_TRCMversionMismatch "Gateway: w418 TRC mversion mismatch";
CM_ SG_ 62 GTW_w420_unexpectedCanMessageLen "Gateway: w420 unexpected can message length";
CM_ SG_ 62 GTW_w421_ModemEthLinkDown "Gateway: w421 modem eth link down";
CM_ SG_ 62 GTW_w422_ethSwitchSevereCongesti "Gateway: w422 eth switch severe congestion watchdog";
CM_ SG_ 62 GTW_w427_DISPBRIDGEversionMismat "Gateway: w427 DISPBRIDG eversion mismatch";
CM_ SG_ 62 GTW_w428_LUMBAR32LversionMismatc "Gateway: w428 LUMBAR32 lversion mismatch";
CM_ SG_ 62 GTW_w429_LUMBAR32RversionMismatc "Gateway: w429 LUMBAR32 rversion mismatch";
CM_ SG_ 62 GTW_w436_possibleCanRxIssue "Gateway: w436 possible can rx issue";
CM_ SG_ 62 GTW_w437_softFlowControlNotRunni "Gateway: w437 soft flow control not running";
CM_ SG_ 62 GTW_w438_wakeSourceUnknown "Gateway: w438 wake source unknown";
CM_ SG_ 62 GTW_w439_VCCCversionMismatch "Gateway: w439 VCC cversion mismatch";
CM_ SG_ 62 GTW_w450_unexpectedAutopilotCont "Gateway: w450 unexpected autopilot control can message";
CM_ SG_ 62 GTW_w451_diagCanBufferExhausted "Gateway: w451 diag can buffer exhausted";
CM_ SG_ 62 GTW_w452_diagCanStaleSocket "Gateway: w452 diag can stale socket";
CM_ SG_ 62 GTW_w453_diagCanFdSetDesync "Gateway: w453 diag can fd set desync";
CM_ SG_ 62 GTW_w454_diagCanFrameOverread "Gateway: w454 diag can frame overread";
CM_ SG_ 62 GTW_w455_hrlDumpPageOwnershipErr "Gateway: w455 hrl dump page ownership error";
CM_ SG_ 62 GTW_w456_hrlStateMachinePageOwne "Gateway: w456 hrl state machine page ownership error";
CM_ SG_ 62 GTW_w463_displayEdidReadFailed "Gateway: w463 display edid read failed";
CM_ SG_ 62 GTW_w469_backlightFsmUnhealthy "Gateway: w469 backlight fsm unhealthy";
CM_ BO_ 838 "Gateway message: autopilot override";
CM_ SG_ 838 GTW_autopilotOverrideState "Signals whether an autopilot trial or subscription is active";
CM_ SG_ 838 GTW_autopilotConfig "Current level of permanent Autopilot firmware";
CM_ SG_ 838 GTW_autopilotOverrideConfig "Current level of trial or subscription Autopilot firmware";
CM_ SG_ 838 GTW_autopilotConfigSource "Source of Autopilot configuration broadcast by Gateway";
CM_ SG_ 838 GTW_autopilotOverrideExpireTime "Expiration time for the currently active autopilot trial or subscription";
CM_ BO_ 904 "Gateway message: can status";
CM_ SG_ 904 GTW_VEH_canBusActivity "Active if any frame detected on the bus";
CM_ SG_ 904 GTW_PARTY_canBusActivity "Active if any frame detected on the bus";
CM_ SG_ 904 GTW_CH_canBusActivity "Active if any frame detected on the bus";
CM_ SG_ 904 GTW_VEH_txWarning "Gateway: VEH tx warning";
CM_ SG_ 904 GTW_PARTY_txWarning "Gateway: PARTY tx warning";
CM_ SG_ 904 GTW_CH_txWarning "Gateway: CH tx warning";
CM_ SG_ 904 GTW_VEH_rxWarning "Gateway: VEH rx warning";
CM_ SG_ 904 GTW_PARTY_rxWarning "Gateway: PARTY rx warning";
CM_ SG_ 904 GTW_CH_rxWarning "Gateway: CH rx warning";
CM_ SG_ 904 GTW_VEH_faultConfinement "Fault confinement as per CAN spec";
CM_ SG_ 904 GTW_PARTY_faultConfinement "Fault confinement as per CAN spec";
CM_ SG_ 904 GTW_CH_faultConfinement "Fault confinement as per CAN spec";
CM_ SG_ 904 GTW_BDY_canBusActivity "Active if any frame detected on the bus";
CM_ SG_ 904 GTW_BDY_txWarning "Gateway: BDY tx warning";
CM_ SG_ 904 GTW_BDY_rxWarning "Gateway: BDY rx warning";
CM_ SG_ 904 GTW_BDY_faultConfinement "Fault confinement as per CAN spec";
CM_ BO_ 792 "Gateway message: car state";
CM_ SG_ 792 GTW_factoryGated "Gateway: factory gated";
CM_ BO_ 1080 "Gateway message: eth nm";
CM_ SG_ 1080 GTW_ethGotoSleep "ETH bus sleep commanded";
CM_ SG_ 1080 GTW_ethWakeUpBus "Gateway: eth wake up bus";
CM_ SG_ 1080 GTW_vehBusAsleep "VEH bus sleep state";
CM_ SG_ 1080 GTW_ethHeartBeatCounter "Gateway: eth heart beat counter";
CM_ SG_ 1080 GTW_ethWakeUpReason "Tracks the cause of why the gateway wakes up the ethernet bus";
CM_ BO_ 1376 "Gateway message: factory ecu present";
CM_ SG_ 1376 GTW_OCS1Ppresent "Gateway: OCS1 ppresent";
CM_ SG_ 1376 GTW_PCSpresent "Gateway: PC spresent";
CM_ SG_ 1376 GTW_HVPpresent "Gateway: HV ppresent";
CM_ SG_ 1376 GTW_BMSpresent "Gateway: BM spresent";
CM_ SG_ 1376 GTW_CPpresent "Gateway: c ppresent";
CM_ SG_ 1376 GTW_RCMpresent "Gateway: RC mpresent";
CM_ SG_ 1376 GTW_SCCMpresent "Gateway: SCC mpresent";
CM_ SG_ 1376 GTW_VCSECpresent "Gateway: VCSE cpresent";
CM_ SG_ 1376 GTW_EPAS3Ppresent "Gateway: EPAS3 ppresent";
CM_ SG_ 1376 GTW_EPBLpresent "Gateway: EPB lpresent";
CM_ SG_ 1376 GTW_EPBRpresent "Gateway: EPB rpresent";
CM_ SG_ 1376 GTW_ESPpresent "Gateway: ES ppresent";
CM_ SG_ 1376 GTW_IBSTpresent "Gateway: IBS tpresent";
CM_ SG_ 1376 GTW_PARKpresent "Gateway: PAR kpresent";
CM_ SG_ 1376 GTW_RADCpresent "Gateway: RAD cpresent";
CM_ SG_ 1376 GTW_TPMSpresent "Gateway: TPM spresent";
CM_ SG_ 1376 GTW_VCFRONTpresent "Gateway: VCFRON tpresent";
CM_ SG_ 1376 GTW_VCLEFTpresent "Gateway: VCLEF tpresent";
CM_ SG_ 1376 GTW_VCRIGHTpresent "Gateway: VCRIGH tpresent";
CM_ SG_ 1376 GTW_EPAS3Spresent "Gateway: EPAS3 spresent";
CM_ SG_ 1376 GTW_CMPpresent "Gateway: CM ppresent";
CM_ SG_ 1376 GTW_DASpresent "Gateway: DA spresent";
CM_ SG_ 1376 GTW_PTCpresent "Gateway: PT cpresent";
CM_ SG_ 1376 GTW_SWCpresent "Gateway: SW cpresent";
CM_ SG_ 1376 GTW_PMRpresent "Gateway: PM rpresent";
CM_ SG_ 1376 GTW_PMFpresent "Gateway: PM fpresent";
CM_ SG_ 1376 GTW_DIRpresent "Gateway: DI rpresent";
CM_ SG_ 1376 GTW_DIFpresent "Gateway: DI fpresent";
CM_ BO_ 1656 "Gateway message: gear control";
CM_ SG_ 1656 GTW_gearControlChecksum "Gateway: gear control checksum";
CM_ SG_ 1656 GTW_gearControlCounter "Gateway: gear control counter";
CM_ SG_ 1656 GTW_gearShiftRequest "Request to change gear state from center display UI control; raw 0 = signal not available (SNA)";
CM_ SG_ 1656 GTW_osdActive "Whether OSD is active";
CM_ SG_ 1656 GTW_primaryGearControlStatus "Status of the center display UI control";
CM_ SG_ 1656 GTW_gearStripEnable "UI control for showing and or activating the primary gear strip interface";
CM_ SG_ 1656 GTW_showNeutralButton "Tell UI that it is time to animate the N button to be shown";
CM_ SG_ 1656 GTW_showAutoParkButton "Tell UI that it is time to animate the autopark button to be shown";
CM_ SG_ 1656 GTW_autoParkRequest "Request to auto park from center display UI control";
CM_ SG_ 1656 GTW_smartShiftStatus "Based on the status of the infotainment system smart shift feature should be disabled; raw 0 = signal not available (SNA)";
CM_ SG_ 1656 GTW_processingRDgestures "Is GTW processing R and D swipe gestures";
CM_ SG_ 1656 GTW_processingTapPgestures "Is GTW processing contextual tap-to-park gestures";
CM_ SG_ 1656 GTW_gearStripChangeReason "Gateway: gear strip change reason; raw 0 = signal not available (SNA)";
CM_ SG_ 1656 GTW_touchActive "User present as touch on display is active";
CM_ SG_ 1656 GTW_steamOff "Let UI know to turn Steam off";
CM_ SG_ 1656 GTW_screenPCBTemperature "Reading from display i2c temperature sensor; raw 2047 = signal not available (SNA)";
BA_DEF_ BO_ "GenMsgCycleTime" INT 0 3600000;
BA_DEF_ BO_ "GenMsgSendType" ENUM "Cyclic","NotUsed","NotUsed","NotUsed","NotUsed","NotUsed","NotUsed","IfActive","NoMsgSendType","NotUsed";
BA_DEF_ BO_ "VFrameFormat" ENUM "StandardCAN","ExtendedCAN","reserved","J1939PG","reserved","reserved","reserved","reserved","reserved","reserved","reserved","reserved","reserved","reserved","StandardCAN_FD","ExtendedCAN_FD";
BA_DEF_ BO_ "CANFD_BRS" ENUM "0","1";
BA_DEF_ SG_ "GenSigSNA" STRING;
BA_DEF_ SG_ "SystemSignalLongSymbol" STRING;
BA_DEF_ SG_ "Confidence" ENUM "validated","plausible","layout-only","contradicted";
BA_DEF_DEF_ "GenMsgCycleTime" 0;
BA_DEF_DEF_ "GenMsgSendType" "NoMsgSendType";
BA_DEF_DEF_ "VFrameFormat" "StandardCAN";
BA_DEF_DEF_ "CANFD_BRS" "1";
BA_DEF_DEF_ "GenSigSNA" "";
BA_DEF_DEF_ "SystemSignalLongSymbol" "";
BA_DEF_DEF_ "Confidence" "layout-only";
BA_ "GenMsgCycleTime" BO_ 971 500;
BA_ "GenMsgSendType" BO_ 971 0;
BA_ "GenMsgCycleTime" BO_ 845 1000;
BA_ "GenMsgSendType" BO_ 845 0;
BA_ "GenMsgCycleTime" BO_ 1143 1000;
BA_ "GenMsgSendType" BO_ 1143 0;
BA_ "GenMsgCycleTime" BO_ 942 1000;
BA_ "GenMsgSendType" BO_ 942 0;
BA_ "GenMsgCycleTime" BO_ 976 1000;
BA_ "GenMsgSendType" BO_ 976 0;
BA_ "GenMsgCycleTime" BO_ 1003 1000;
BA_ "GenMsgSendType" BO_ 1003 0;
BA_ "GenMsgCycleTime" BO_ 551 100;
BA_ "GenMsgSendType" BO_ 551 0;
BA_ "GenMsgCycleTime" BO_ 778 30;
BA_ "GenMsgSendType" BO_ 778 0;
BA_ "GenMsgCycleTime" BO_ 781 250;
BA_ "GenMsgSendType" BO_ 781 0;
BA_ "GenMsgCycleTime" BO_ 1548 5;
BA_ "GenMsgSendType" BO_ 1548 0;
BA_ "GenMsgCycleTime" BO_ 888 1000;
BA_ "GenMsgSendType" BO_ 888 0;
BA_ "GenMsgCycleTime" BO_ 282 1000;
BA_ "GenMsgSendType" BO_ 282 0;
BA_ "GenMsgCycleTime" BO_ 62 100;
BA_ "GenMsgSendType" BO_ 62 0;
BA_ "GenMsgCycleTime" BO_ 838 1000;
BA_ "GenMsgSendType" BO_ 838 0;
BA_ "GenMsgCycleTime" BO_ 904 1000;
BA_ "GenMsgSendType" BO_ 904 0;
BA_ "GenMsgCycleTime" BO_ 792 100;
BA_ "GenMsgSendType" BO_ 792 0;
BA_ "GenMsgCycleTime" BO_ 1080 100;
BA_ "GenMsgSendType" BO_ 1080 0;
BA_ "GenMsgCycleTime" BO_ 1376 1000;
BA_ "GenMsgSendType" BO_ 1376 0;
BA_ "GenMsgCycleTime" BO_ 1656 100;
BA_ "GenMsgSendType" BO_ 1656 0;
BA_ "Confidence" SG_ 971 APSB_appStatusMonitorState 1;
BA_ "Confidence" SG_ 971 APSB_vehBehaviorState 1;
BA_ "Confidence" SG_ 971 APSB_canMaster 1;
BA_ "GenSigSNA" SG_ 971 APSB_canMaster "3";
BA_ "Confidence" SG_ 971 APSB_appGpioState 1;
BA_ "Confidence" SG_ 971 APSB_eacInternalState 1;
BA_ "Confidence" SG_ 971 APSB_apbStatusMonitorState 1;
BA_ "Confidence" SG_ 971 APSB_apbGpioState 1;
BA_ "Confidence" SG_ 971 APSB_locLimitReason 1;
BA_ "Confidence" SG_ 971 APSB_appPowerStateRequest 1;
BA_ "Confidence" SG_ 971 APSB_appPowerStateReason 1;
BA_ "Confidence" SG_ 971 APSB_apbPowerStateRequest 1;
BA_ "Confidence" SG_ 971 APSB_apbPowerStateReason 1;
BA_ "Confidence" SG_ 971 APSB_heaterStateDebug 1;
BA_ "GenSigSNA" SG_ 971 APSB_heaterStateDebug "7";
BA_ "Confidence" SG_ 971 APSB_gpsAntennaState 1;
BA_ "Confidence" SG_ 971 APSB_arbState 1;
BA_ "Confidence" SG_ 971 APSB_socPowerOperatingMode 1;
BA_ "SystemSignalLongSymbol" SG_ 845 APSB_w040_autopilotAngleSaturate "APSB_w040_autopilotAngleSaturated";
BA_ "SystemSignalLongSymbol" SG_ 1143 APSB_w065_deserializerOvercurren "APSB_w065_deserializerOvercurrent";
BA_ "SystemSignalLongSymbol" SG_ 976 APSB_w215_contDriverNotIntractin "APSB_w215_contDriverNotIntracting";
BA_ "SystemSignalLongSymbol" SG_ 976 APSB_w245_eloopRxFromUnexpectedS "APSB_w245_eloopRxFromUnexpectedSourceMAC";
BA_ "SystemSignalLongSymbol" SG_ 976 APSB_w246_ethloopSwitchPortLinkD "APSB_w246_ethloopSwitchPortLinkDown";
BA_ "SystemSignalLongSymbol" SG_ 976 APSB_w250_ethloopSwitchMemUsageT "APSB_w250_ethloopSwitchMemUsageTooHighPort2";
BA_ "SystemSignalLongSymbol" SG_ 976 APSB_w251_ethloopSwitchMemUsageT "APSB_w251_ethloopSwitchMemUsageTooHighPort3";
BA_ "SystemSignalLongSymbol" SG_ 1003 APSB_w258_qspiFlashSectorChecksu "APSB_w258_qspiFlashSectorChecksumMismatch";
BA_ "SystemSignalLongSymbol" SG_ 1003 APSB_w269_ethSwitchRxPageCountTo "APSB_w269_ethSwitchRxPageCountTooHighPort0_3";
BA_ "SystemSignalLongSymbol" SG_ 1003 APSB_w270_ethSwitchRxPageCountTo "APSB_w270_ethSwitchRxPageCountTooHighPort4_7";
BA_ "SystemSignalLongSymbol" SG_ 1003 APSB_w284_cam12VBuckBoostAPwrIss "APSB_w284_cam12VBuckBoostAPwrIssue";
BA_ "SystemSignalLongSymbol" SG_ 1003 APSB_w285_cam12VBuckBoostBPwrIss "APSB_w285_cam12VBuckBoostBPwrIssue";
BA_ "SystemSignalLongSymbol" SG_ 1003 APSB_w286_cam12VEFuseAPrimaryIss "APSB_w286_cam12VEFuseAPrimaryIssue";
BA_ "SystemSignalLongSymbol" SG_ 1003 APSB_w287_cam12VEFuseASecondaryI "APSB_w287_cam12VEFuseASecondaryIssue";
BA_ "SystemSignalLongSymbol" SG_ 1003 APSB_w289_turboTemperatureWarnin "APSB_w289_turboTemperatureWarning";
BA_ "SystemSignalLongSymbol" SG_ 1003 APSB_w290_cam12VBuckBoostBPwrRin "APSB_w290_cam12VBuckBoostBPwrRinging";
BA_ "SystemSignalLongSymbol" SG_ 1003 APSB_w296_wdogMonTaskDeadlineMis "APSB_w296_wdogMonTaskDeadlineMiss";
BA_ "SystemSignalLongSymbol" SG_ 1003 APSB_w298_cpuToApCanSharedMemErr "APSB_w298_cpuToApCanSharedMemError";
BA_ "SystemSignalLongSymbol" SG_ 1003 APSB_w299_apToCpuCanSharedMemErr "APSB_w299_apToCpuCanSharedMemError";
BA_ "SystemSignalLongSymbol" SG_ 1003 APSB_w300_sharedMemoryAccessErro "APSB_w300_sharedMemoryAccessError";
BA_ "SystemSignalLongSymbol" SG_ 1003 APSB_w318_ethernetNetworkBufferH "APSB_w318_ethernetNetworkBufferHighWatermark";
BA_ "SystemSignalLongSymbol" SG_ 1003 APSB_w320_eplannerPreconditionsM "APSB_w320_eplannerPreconditionsMet";
BA_ "Confidence" SG_ 551 CMP_inputHVVoltage 1;
BA_ "Confidence" SG_ 551 CMP_inputLVVoltage 1;
BA_ "Confidence" SG_ 551 CMP_inputHVCurrent 1;
BA_ "Confidence" SG_ 551 CMP_inputHVPower 1;
BA_ "Confidence" SG_ 778 DAS_objectId 1;
BA_ "Confidence" SG_ 778 DAS_leadVehType 1;
BA_ "Confidence" SG_ 778 DAS_leadVehDx 1;
BA_ "GenSigSNA" SG_ 778 DAS_leadVehDx "255";
BA_ "Confidence" SG_ 778 DAS_leadVehVxRel 1;
BA_ "GenSigSNA" SG_ 778 DAS_leadVehVxRel "15";
BA_ "Confidence" SG_ 778 DAS_leadVehDy 1;
BA_ "Confidence" SG_ 778 DAS_leadVehId 1;
BA_ "GenSigSNA" SG_ 778 DAS_leadVehId "127";
BA_ "Confidence" SG_ 778 DAS_leadVeh2Type 1;
BA_ "Confidence" SG_ 778 DAS_leadVeh2Dx 1;
BA_ "GenSigSNA" SG_ 778 DAS_leadVeh2Dx "255";
BA_ "Confidence" SG_ 778 DAS_leadVeh2VxRel 1;
BA_ "GenSigSNA" SG_ 778 DAS_leadVeh2VxRel "15";
BA_ "Confidence" SG_ 778 DAS_leadVeh2Dy 1;
BA_ "Confidence" SG_ 778 DAS_leadVeh2Id 1;
BA_ "GenSigSNA" SG_ 778 DAS_leadVeh2Id "0";
BA_ "Confidence" SG_ 778 DAS_leftVehType 1;
BA_ "Confidence" SG_ 778 DAS_leftVehDx 1;
BA_ "GenSigSNA" SG_ 778 DAS_leftVehDx "255";
BA_ "Confidence" SG_ 778 DAS_leftVehVxRel 1;
BA_ "GenSigSNA" SG_ 778 DAS_leftVehVxRel "15";
BA_ "Confidence" SG_ 778 DAS_leftVehDy 1;
BA_ "Confidence" SG_ 778 DAS_leftVehId 1;
BA_ "GenSigSNA" SG_ 778 DAS_leftVehId "127";
BA_ "Confidence" SG_ 778 DAS_leftVeh2Type 1;
BA_ "Confidence" SG_ 778 DAS_leftVeh2Dx 1;
BA_ "GenSigSNA" SG_ 778 DAS_leftVeh2Dx "255";
BA_ "Confidence" SG_ 778 DAS_leftVeh2VxRel 1;
BA_ "GenSigSNA" SG_ 778 DAS_leftVeh2VxRel "15";
BA_ "Confidence" SG_ 778 DAS_leftVeh2Dy 1;
BA_ "Confidence" SG_ 778 DAS_leftVeh2Id 1;
BA_ "GenSigSNA" SG_ 778 DAS_leftVeh2Id "0";
BA_ "Confidence" SG_ 778 DAS_rightVehType 1;
BA_ "Confidence" SG_ 778 DAS_rightVehDx 1;
BA_ "GenSigSNA" SG_ 778 DAS_rightVehDx "255";
BA_ "Confidence" SG_ 778 DAS_rightVehVxRel 1;
BA_ "GenSigSNA" SG_ 778 DAS_rightVehVxRel "15";
BA_ "Confidence" SG_ 778 DAS_rightVehDy 1;
BA_ "Confidence" SG_ 778 DAS_rightVehId 1;
BA_ "GenSigSNA" SG_ 778 DAS_rightVehId "127";
BA_ "Confidence" SG_ 778 DAS_rightVeh2Type 1;
BA_ "Confidence" SG_ 778 DAS_rightVeh2Dx 1;
BA_ "GenSigSNA" SG_ 778 DAS_rightVeh2Dx "255";
BA_ "Confidence" SG_ 778 DAS_rightVeh2VxRel 1;
BA_ "GenSigSNA" SG_ 778 DAS_rightVeh2VxRel "15";
BA_ "Confidence" SG_ 778 DAS_rightVeh2Dy 1;
BA_ "Confidence" SG_ 778 DAS_rightVeh2Id 1;
BA_ "GenSigSNA" SG_ 778 DAS_rightVeh2Id "0";
BA_ "Confidence" SG_ 778 DAS_cutinVehType 1;
BA_ "Confidence" SG_ 778 DAS_cutinVehDx 1;
BA_ "GenSigSNA" SG_ 778 DAS_cutinVehDx "255";
BA_ "Confidence" SG_ 778 DAS_cutinVehVxRel 1;
BA_ "GenSigSNA" SG_ 778 DAS_cutinVehVxRel "15";
BA_ "Confidence" SG_ 778 DAS_cutinVehDy 1;
BA_ "Confidence" SG_ 778 DAS_cutinVehId 1;
BA_ "GenSigSNA" SG_ 778 DAS_cutinVehId "127";
BA_ "Confidence" SG_ 778 DAS_roadSignColor 1;
BA_ "Confidence" SG_ 778 DAS_roadSignId 1;
BA_ "GenSigSNA" SG_ 778 DAS_roadSignId "255";
BA_ "Confidence" SG_ 778 DAS_roadSignStopLineDist 1;
BA_ "GenSigSNA" SG_ 778 DAS_roadSignStopLineDist "1023";
BA_ "Confidence" SG_ 778 DAS_roadSignSource 1;
BA_ "Confidence" SG_ 778 DAS_roadSignArrow 1;
BA_ "Confidence" SG_ 778 DAS_roadSignOrientation 1;
BA_ "Confidence" SG_ 781 DAS_positioningEngineStatusMulti 1;
BA_ "SystemSignalLongSymbol" SG_ 781 DAS_positioningEngineStatusMulti "DAS_positioningEngineStatusMultiplexer";
BA_ "Confidence" SG_ 781 DAS_meoSolverNumRuns 1;
BA_ "Confidence" SG_ 781 DAS_meoSolverReportTerminationTy 1;
BA_ "SystemSignalLongSymbol" SG_ 781 DAS_meoSolverReportTerminationTy "DAS_meoSolverReportTerminationType";
BA_ "Confidence" SG_ 781 DAS_meoSolverReportTotalTimeS 1;
BA_ "Confidence" SG_ 781 DAS_meoHorizontalAccuracyM 1;
BA_ "Confidence" SG_ 781 DAS_meoVerticalAccuracyM 1;
BA_ "Confidence" SG_ 781 DAS_meoHeadingAccuracyDeg 1;
BA_ "Confidence" SG_ 781 DAS_meoHeadingValid 1;
BA_ "Confidence" SG_ 781 DAS_meoGpsQualityLevel 1;
BA_ "Confidence" SG_ 781 DAS_meoFixType 1;
BA_ "Confidence" SG_ 781 DAS_lastMeoResetReason 1;
BA_ "Confidence" SG_ 781 DAS_vioMultiGpsSelectedSource 1;
BA_ "Confidence" SG_ 781 DAS_vioMultiGpsPeCooldownActive 1;
BA_ "Confidence" SG_ 781 DAS_vioMultiGpsPeSppTdcpConsiste 1;
BA_ "SystemSignalLongSymbol" SG_ 781 DAS_vioMultiGpsPeSppTdcpConsiste "DAS_vioMultiGpsPeSppTdcpConsistentWithRawGps";
BA_ "Confidence" SG_ 781 DAS_vioMultiGpsPeMeoConsistentWi 1;
BA_ "SystemSignalLongSymbol" SG_ 781 DAS_vioMultiGpsPeMeoConsistentWi "DAS_vioMultiGpsPeMeoConsistentWithRawGps";
BA_ "Confidence" SG_ 781 DAS_vioMultiGpsPeSppTdcpVsR_0001 1;
BA_ "SystemSignalLongSymbol" SG_ 781 DAS_vioMultiGpsPeSppTdcpVsR_0001 "DAS_vioMultiGpsPeSppTdcpVsRawGpsTransDiscrepM";
BA_ "Confidence" SG_ 781 DAS_vioMultiGpsPeMeoVsRawGpsTran 1;
BA_ "SystemSignalLongSymbol" SG_ 781 DAS_vioMultiGpsPeMeoVsRawGpsTran "DAS_vioMultiGpsPeMeoVsRawGpsTransDiscrepM";
BA_ "Confidence" SG_ 781 DAS_vioMultiGpsPeSppTdcpVsRawGps 1;
BA_ "SystemSignalLongSymbol" SG_ 781 DAS_vioMultiGpsPeSppTdcpVsRawGps "DAS_vioMultiGpsPeSppTdcpVsRawGpsRotDiscrepDeg";
BA_ "Confidence" SG_ 781 DAS_vioMultiGpsPeMeoVsRawGpsRotD 1;
BA_ "SystemSignalLongSymbol" SG_ 781 DAS_vioMultiGpsPeMeoVsRawGpsRotD "DAS_vioMultiGpsPeMeoVsRawGpsRotDiscrepDeg";
BA_ "Confidence" SG_ 781 DAS_publishedGpsSource 1;
BA_ "Confidence" SG_ 781 DAS_bluefinEnabled 1;
BA_ "Confidence" SG_ 781 DAS_orioleDisabled 1;
BA_ "Confidence" SG_ 781 DAS_disableMonarch 1;
BA_ "Confidence" SG_ 1548 DAS_TR_ObjIndex 1;
BA_ "Confidence" SG_ 1548 DAS_TR_Obj00_Class 1;
BA_ "Confidence" SG_ 1548 DAS_TR_Obj00_Dx 1;
BA_ "Confidence" SG_ 1548 DAS_TR_Obj00_Dy 1;
BA_ "Confidence" SG_ 1548 DAS_TR_Obj00_Vx 1;
BA_ "Confidence" SG_ 1548 DAS_TR_Obj00_RCS 1;
BA_ "Confidence" SG_ 1548 DAS_TR_Obj00_Length 1;
BA_ "Confidence" SG_ 1548 DAS_TR_Obj00_MovingState 1;
BA_ "Confidence" SG_ 1548 DAS_TR_Obj00_Dz 1;
BA_ "Confidence" SG_ 1548 DAS_TR_Obj00_Exist 1;
BA_ "Confidence" SG_ 1592 EPAS3P_udsResponseDataCH 1;
BA_ "Confidence" SG_ 888 GTW_GTW_SOS_ECALL_RQST 1;
BA_ "Confidence" SG_ 888 GTW_LTE_ECALL_LOCK 1;
BA_ "Confidence" SG_ 282 GTW_BKP_BATT_MON 1;
BA_ "GenSigSNA" SG_ 282 GTW_BKP_BATT_MON "4095";
BA_ "Confidence" SG_ 282 GTW_BKP_BATT_NTC_P 1;
BA_ "GenSigSNA" SG_ 282 GTW_BKP_BATT_NTC_P "4095";
BA_ "Confidence" SG_ 282 GTW_ECALL_GPS_ANT_BIAS 1;
BA_ "GenSigSNA" SG_ 282 GTW_ECALL_GPS_ANT_BIAS "4095";
BA_ "Confidence" SG_ 282 GTW_ECALL_MIC_DIAG 1;
BA_ "GenSigSNA" SG_ 282 GTW_ECALL_MIC_DIAG "4095";
BA_ "Confidence" SG_ 282 GTW_SOS_ECALL_nRQST_BUF 1;
BA_ "GenSigSNA" SG_ 282 GTW_SOS_ECALL_nRQST_BUF "4095";
BA_ "Confidence" SG_ 1384 GTW_alertID 1;
BA_ "Confidence" SG_ 1384 GTW_alertState 1;
BA_ "Confidence" SG_ 1384 GTW_a049_headerError 1;
BA_ "Confidence" SG_ 1384 GTW_a062_bmpWatchdogReason 1;
BA_ "Confidence" SG_ 1384 GTW_a063_VEH_faultConfinement 1;
BA_ "Confidence" SG_ 1384 GTW_a064_CH_faultConfinement 1;
BA_ "Confidence" SG_ 1384 GTW_a065_PARTY_faultConfinement 1;
BA_ "Confidence" SG_ 1384 GTW_a073_SOCResetRequestor 1;
BA_ "Confidence" SG_ 1384 GTW_a077_bmpPmicErrorType 1;
BA_ "Confidence" SG_ 1384 GTW_a122_BDY_faultConfinement 1;
BA_ "Confidence" SG_ 1384 GTW_a261_failureReason 1;
BA_ "Confidence" SG_ 1384 GTW_a277_mitigationFailureReason 1;
BA_ "Confidence" SG_ 1384 GTW_a279_failureReason 1;
BA_ "Confidence" SG_ 1384 GTW_a317_status 1;
BA_ "Confidence" SG_ 1384 GTW_a317_errorCode 1;
BA_ "Confidence" SG_ 62 GTW_matrixIndex 1;
BA_ "SystemSignalLongSymbol" SG_ 62 GTW_w016_BLEEPCENTERversionMisma "GTW_w016_BLEEPCENTERversionMismatch";
BA_ "SystemSignalLongSymbol" SG_ 62 GTW_w093_sdCardInvReqOverflowBas "GTW_w093_sdCardInvReqOverflowBase";
BA_ "SystemSignalLongSymbol" SG_ 62 GTW_w094_sdCardInvReqOverflowCou "GTW_w094_sdCardInvReqOverflowCount";
BA_ "SystemSignalLongSymbol" SG_ 62 GTW_w104_sdCardDriverArgCorrupte "GTW_w104_sdCardDriverArgCorrupted";
BA_ "SystemSignalLongSymbol" SG_ 62 GTW_w106_BLEEPLEFTversionMismatc "GTW_w106_BLEEPLEFTversionMismatch";
BA_ "SystemSignalLongSymbol" SG_ 62 GTW_w107_BLEEPRIGHTversionMismat "GTW_w107_BLEEPRIGHTversionMismatch";
BA_ "SystemSignalLongSymbol" SG_ 62 GTW_w108_BLEEPREARversionMismatc "GTW_w108_BLEEPREARversionMismatch";
BA_ "SystemSignalLongSymbol" SG_ 62 GTW_w117_unexpectedDestructiveRe "GTW_w117_unexpectedDestructiveResetStatus";
BA_ "SystemSignalLongSymbol" SG_ 62 GTW_w118_unexpectedFunctionalRes "GTW_w118_unexpectedFunctionalResetStatus";
BA_ "SystemSignalLongSymbol" SG_ 62 GTW_w146_performancePackageMisma "GTW_w146_performancePackageMismatch";
BA_ "SystemSignalLongSymbol" SG_ 62 GTW_w227_DISPTOUCHversionMismatc "GTW_w227_DISPTOUCHversionMismatch";
BA_ "SystemSignalLongSymbol" SG_ 62 GTW_w229_displaySoftsetConnectio "GTW_w229_displaySoftsetConnection";
BA_ "SystemSignalLongSymbol" SG_ 62 GTW_w273_BLEEPREARLEFTversionMis "GTW_w273_BLEEPREARLEFTversionMismatch";
BA_ "SystemSignalLongSymbol" SG_ 62 GTW_w274_BLEEPREARRIGHTversionMi "GTW_w274_BLEEPREARRIGHTversionMismatch";
BA_ "SystemSignalLongSymbol" SG_ 62 GTW_w277_NonRevCDrMOSMitigationF "GTW_w277_NonRevCDrMOSMitigationFailed";
BA_ "SystemSignalLongSymbol" SG_ 62 GTW_w282_tcuPhyConfigurationFail "GTW_w282_tcuPhyConfigurationFailed";
BA_ "SystemSignalLongSymbol" SG_ 62 GTW_w311_canLogQueueFullBeforeFs "GTW_w311_canLogQueueFullBeforeFsInit";
BA_ "SystemSignalLongSymbol" SG_ 62 GTW_w317_sdCardChkdskRepairFaile "GTW_w317_sdCardChkdskRepairFailed";
BA_ "SystemSignalLongSymbol" SG_ 62 GTW_w322_gestureUnrecognizedFrom "GTW_w322_gestureUnrecognizedFromMoving";
BA_ "SystemSignalLongSymbol" SG_ 62 GTW_w360_RGBDOORFLversionMismatc "GTW_w360_RGBDOORFLversionMismatch";
BA_ "SystemSignalLongSymbol" SG_ 62 GTW_w361_RGBDOORRLversionMismatc "GTW_w361_RGBDOORRLversionMismatch";
BA_ "SystemSignalLongSymbol" SG_ 62 GTW_w362_RGBDOORFRversionMismatc "GTW_w362_RGBDOORFRversionMismatch";
BA_ "SystemSignalLongSymbol" SG_ 62 GTW_w363_RGBDOORRRversionMismatc "GTW_w363_RGBDOORRRversionMismatch";
BA_ "SystemSignalLongSymbol" SG_ 62 GTW_w364_BLEEPCRADLEversionMisma "GTW_w364_BLEEPCRADLEversionMismatch";
BA_ "SystemSignalLongSymbol" SG_ 62 GTW_w420_unexpectedCanMessageLen "GTW_w420_unexpectedCanMessageLength";
BA_ "SystemSignalLongSymbol" SG_ 62 GTW_w422_ethSwitchSevereCongesti "GTW_w422_ethSwitchSevereCongestionWatchdog";
BA_ "SystemSignalLongSymbol" SG_ 62 GTW_w427_DISPBRIDGEversionMismat "GTW_w427_DISPBRIDGEversionMismatch";
BA_ "SystemSignalLongSymbol" SG_ 62 GTW_w428_LUMBAR32LversionMismatc "GTW_w428_LUMBAR32LversionMismatch";
BA_ "SystemSignalLongSymbol" SG_ 62 GTW_w429_LUMBAR32RversionMismatc "GTW_w429_LUMBAR32RversionMismatch";
BA_ "SystemSignalLongSymbol" SG_ 62 GTW_w437_softFlowControlNotRunni "GTW_w437_softFlowControlNotRunning";
BA_ "SystemSignalLongSymbol" SG_ 62 GTW_w450_unexpectedAutopilotCont "GTW_w450_unexpectedAutopilotControlCanMessage";
BA_ "SystemSignalLongSymbol" SG_ 62 GTW_w455_hrlDumpPageOwnershipErr "GTW_w455_hrlDumpPageOwnershipError";
BA_ "SystemSignalLongSymbol" SG_ 62 GTW_w456_hrlStateMachinePageOwne "GTW_w456_hrlStateMachinePageOwnershipError";
BA_ "Confidence" SG_ 838 GTW_autopilotOverrideState 1;
BA_ "Confidence" SG_ 838 GTW_autopilotConfig 1;
BA_ "Confidence" SG_ 838 GTW_autopilotOverrideConfig 1;
BA_ "Confidence" SG_ 838 GTW_autopilotConfigSource 1;
BA_ "Confidence" SG_ 838 GTW_autopilotOverrideExpireTime 1;
BA_ "Confidence" SG_ 904 GTW_VEH_canBusActivity 1;
BA_ "Confidence" SG_ 904 GTW_PARTY_canBusActivity 1;
BA_ "Confidence" SG_ 904 GTW_CH_canBusActivity 1;
BA_ "Confidence" SG_ 904 GTW_VEH_faultConfinement 1;
BA_ "Confidence" SG_ 904 GTW_PARTY_faultConfinement 1;
BA_ "Confidence" SG_ 904 GTW_CH_faultConfinement 1;
BA_ "Confidence" SG_ 904 GTW_BDY_canBusActivity 1;
BA_ "Confidence" SG_ 904 GTW_BDY_faultConfinement 1;
BA_ "Confidence" SG_ 1080 GTW_ethGotoSleep 1;
BA_ "Confidence" SG_ 1080 GTW_vehBusAsleep 1;
BA_ "Confidence" SG_ 1080 GTW_ethWakeUpReason 1;
BA_ "Confidence" SG_ 1656 GTW_gearShiftRequest 1;
BA_ "GenSigSNA" SG_ 1656 GTW_gearShiftRequest "0";
BA_ "Confidence" SG_ 1656 GTW_osdActive 1;
BA_ "Confidence" SG_ 1656 GTW_primaryGearControlStatus 1;
BA_ "Confidence" SG_ 1656 GTW_gearStripEnable 1;
BA_ "Confidence" SG_ 1656 GTW_showNeutralButton 1;
BA_ "Confidence" SG_ 1656 GTW_showAutoParkButton 1;
BA_ "Confidence" SG_ 1656 GTW_autoParkRequest 1;
BA_ "Confidence" SG_ 1656 GTW_smartShiftStatus 1;
BA_ "GenSigSNA" SG_ 1656 GTW_smartShiftStatus "0";
BA_ "Confidence" SG_ 1656 GTW_processingRDgestures 1;
BA_ "Confidence" SG_ 1656 GTW_processingTapPgestures 1;
BA_ "Confidence" SG_ 1656 GTW_gearStripChangeReason 1;
BA_ "GenSigSNA" SG_ 1656 GTW_gearStripChangeReason "0";
BA_ "Confidence" SG_ 1656 GTW_touchActive 1;
BA_ "Confidence" SG_ 1656 GTW_steamOff 1;
BA_ "Confidence" SG_ 1656 GTW_screenPCBTemperature 1;
BA_ "GenSigSNA" SG_ 1656 GTW_screenPCBTemperature "2047";
VAL_ 971 APSB_appStatusMonitorState 7 "STATUS_MONITOR_NUM_STATES" 6 "STATUS_MONITOR_STATE_RECOVERY" 5 "STATUS_MONITOR_STATE_SHUTTING_DOWN" 4 "STATUS_MONITOR_STATE_CRITICAL" 3 "STATUS_MONITOR_STATE_NOMINAL" 2 "STATUS_MONITOR_STATE_INIT" 1 "STATUS_MONITOR_STATE_PWR_OFF" 0 "STATUS_MONITOR_STATE_UNKNOWN" ;
VAL_ 971 APSB_vehBehaviorState 8 "VEH_BEHAVIOR_NUM_STATES" 7 "VEH_BEHAVIOR_STATE_SYSTEM_FAULT" 6 "VEH_BEHAVIOR_STATE_APS_OVERRIDE" 5 "VEH_BEHAVIOR_STATE_APS_FAIL_SAFE" 4 "VEH_BEHAVIOR_STATE_APS_BRIDGE_APB" 3 "VEH_BEHAVIOR_STATE_APS_BRIDGE_APP" 2 "VEH_BEHAVIOR_STATE_APS_CONTROL" 1 "VEH_BEHAVIOR_STATE_APS_AVAILABLE" 0 "VEH_BEHAVIOR_STATE_UNKNOWN" ;
VAL_ 971 APSB_canMaster 3 "CAN_MASTER_SNA" 2 "CAN_MASTER_APB" 1 "CAN_MASTER_APP" 0 "CAN_MASTER_APS" ;
VAL_ 971 APSB_appGpioState 3 "AP_GPIO_STATE_HEALTHY" 2 "AP_GPIO_STATE_CRITICAL" 1 "AP_GPIO_STATE_DISABLED" 0 "AP_GPIO_STATE_PWR_DOWN_REBOOT" ;
VAL_ 971 APSB_eacInternalState 7 "APS_EAC_NUM_STATES" 6 "APS_EAC_STATE_LSS" 5 "APS_EAC_STATE_OVERRIDE" 4 "APS_EAC_STATE_INHIBIT" 3 "APS_EAC_STATE_AUTOPARK" 2 "APS_EAC_STATE_CONTINUOUS" 1 "APS_EAC_STATE_MOMENTARY" 0 "APS_EAC_STATE_INIT" ;
VAL_ 971 APSB_apbStatusMonitorState 7 "STATUS_MONITOR_NUM_STATES" 6 "STATUS_MONITOR_STATE_RECOVERY" 5 "STATUS_MONITOR_STATE_SHUTTING_DOWN" 4 "STATUS_MONITOR_STATE_CRITICAL" 3 "STATUS_MONITOR_STATE_NOMINAL" 2 "STATUS_MONITOR_STATE_INIT" 1 "STATUS_MONITOR_STATE_PWR_OFF" 0 "STATUS_MONITOR_STATE_UNKNOWN" ;
VAL_ 971 APSB_apbGpioState 3 "AP_GPIO_STATE_HEALTHY" 2 "AP_GPIO_STATE_CRITICAL" 1 "AP_GPIO_STATE_DISABLED" 0 "AP_GPIO_STATE_PWR_DOWN_REBOOT" ;
VAL_ 971 APSB_locLimitReason 7 "LOC_LIMITS_EXTENDED" 6 "LOC_MONITOR_UNAVAILABLE" 5 "NO_RADAR_TARGET" 4 "RADAR_NOT_HEALTHY" 3 "PRIMARY_AP_NOT_HEALTHY" 2 "ACC_AND_AEB_UNAVAILABLE" 1 "NOT_IN_DRIVE" 0 "NOMINAL_DEFAULT" ;
VAL_ 971 APSB_appPowerStateRequest 3 "AP_POWER_STATE_SLEEP" 2 "AP_POWER_STATE_SUSPEND" 1 "AP_POWER_STATE_SENTRY" 0 "AP_POWER_STATE_NOMINAL" ;
VAL_ 971 APSB_appPowerStateReason 12 "UI_SUMMON_STANDBY_MODE_ENABLED" 11 "SLEEP_REQUEST_RECVD" 10 "AP_POWER_REQUEST_OVERHEATED" 9 "LOADSHED_POWER_REQUEST_PENDING" 8 "VC_POWER_REQUEST" 7 "AP_POWER_REQUEST_OVERRIDE" 6 "AP_POWER_REQUEST_OVERHEATING" 5 "AP_POWER_REQUEST_HYSTERESIS" 4 "GTW_GOTO_FULL_POWER" 3 "AP_NOT_IN_PARK" 2 "AP_NM_REASON_SET" 1 "AP_WDOG_UNHEALTHY" 0 "UI_POWER_STATE_REQUEST" ;
VAL_ 971 APSB_apbPowerStateRequest 3 "AP_POWER_STATE_SLEEP" 2 "AP_POWER_STATE_SUSPEND" 1 "AP_POWER_STATE_SENTRY" 0 "AP_POWER_STATE_NOMINAL" ;
VAL_ 971 APSB_apbPowerStateReason 12 "UI_SUMMON_STANDBY_MODE_ENABLED" 11 "SLEEP_REQUEST_RECVD" 10 "AP_POWER_REQUEST_OVERHEATED" 9 "LOADSHED_POWER_REQUEST_PENDING" 8 "VC_POWER_REQUEST" 7 "AP_POWER_REQUEST_OVERRIDE" 6 "AP_POWER_REQUEST_OVERHEATING" 5 "AP_POWER_REQUEST_HYSTERESIS" 4 "GTW_GOTO_FULL_POWER" 3 "AP_NOT_IN_PARK" 2 "AP_NM_REASON_SET" 1 "AP_WDOG_UNHEALTHY" 0 "UI_POWER_STATE_REQUEST" ;
VAL_ 971 APSB_heaterStateDebug 7 "APS_HEATER_SNA" 4 "APS_HEATER_FAULT_SHORT" 3 "APS_HEATER_FAULT_OPEN" 2 "APS_HEATER_ON_NOT_HEATING" 1 "APS_HEATER_ON_HEATING" 0 "APS_HEATER_OFF" ;
VAL_ 971 APSB_gpsAntennaState 2 "GPS_ANTENNA_CONNECTED" 1 "GPS_ANTENNA_UNKNOWN" 0 "GPS_ANTENNA_DISCONNECTED" ;
VAL_ 971 APSB_arbState 7 "ARB_STATE_N_COUNT" 6 "ARB_STATE_N_UNKNOWN" 5 "ARB_STATE_N_MIA" 4 "ARB_STATE_N_FAULT" 3 "ARB_STATE_N_SECONDARY" 2 "ARB_STATE_N_PRIMARY" 1 "ARB_STATE_N_IDLE" 0 "ARB_STATE_N_INIT" ;
VAL_ 971 APSB_socPowerOperatingMode 2 "APS_DUAL_SOC" 1 "APS_SINGLE_SOC" 0 "APS_UNKNOWN" ;
VAL_ 778 DAS_objectId 5 "VEHICLE_HEADINGS" 4 "ROAD_SIGN" 3 "CUTIN_VEHICLE" 2 "RIGHT_VEHICLES" 1 "LEFT_VEHICLES" 0 "LEAD_VEHICLES" ;
VAL_ 778 DAS_leadVehType 6 "IPSO" 5 "PEDESTRIAN" 4 "BICYCLE" 3 "MOTORCYCLE" 2 "CAR" 1 "TRUCK" 0 "UNKNOWN" ;
VAL_ 778 DAS_leadVehDx 255 "SNA" ;
VAL_ 778 DAS_leadVehVxRel 15 "SNA" ;
VAL_ 778 DAS_leadVehId 127 "SNA" ;
VAL_ 778 DAS_leadVeh2Type 5 "PEDESTRIAN" 4 "BICYCLE" 3 "MOTORCYCLE" 2 "CAR" 1 "TRUCK" 0 "UNKNOWN" ;
VAL_ 778 DAS_leadVeh2Dx 255 "SNA" ;
VAL_ 778 DAS_leadVeh2VxRel 15 "SNA" ;
VAL_ 778 DAS_leadVeh2Id 0 "SNA" ;
VAL_ 778 DAS_leftVehType 5 "PEDESTRIAN" 4 "BICYCLE" 3 "MOTORCYCLE" 2 "CAR" 1 "TRUCK" 0 "UNKNOWN" ;
VAL_ 778 DAS_leftVehDx 255 "SNA" ;
VAL_ 778 DAS_leftVehVxRel 15 "SNA" ;
VAL_ 778 DAS_leftVehId 127 "SNA" ;
VAL_ 778 DAS_leftVeh2Type 5 "PEDESTRIAN" 4 "BICYCLE" 3 "MOTORCYCLE" 2 "CAR" 1 "TRUCK" 0 "UNKNOWN" ;
VAL_ 778 DAS_leftVeh2Dx 255 "SNA" ;
VAL_ 778 DAS_leftVeh2VxRel 15 "SNA" ;
VAL_ 778 DAS_leftVeh2Id 0 "SNA" ;
VAL_ 778 DAS_rightVehType 5 "PEDESTRIAN" 4 "BICYCLE" 3 "MOTORCYCLE" 2 "CAR" 1 "TRUCK" 0 "UNKNOWN" ;
VAL_ 778 DAS_rightVehDx 255 "SNA" ;
VAL_ 778 DAS_rightVehVxRel 15 "SNA" ;
VAL_ 778 DAS_rightVehId 127 "SNA" ;
VAL_ 778 DAS_rightVeh2Type 5 "PEDESTRIAN" 4 "BICYCLE" 3 "MOTORCYCLE" 2 "CAR" 1 "TRUCK" 0 "UNKNOWN" ;
VAL_ 778 DAS_rightVeh2Dx 255 "SNA" ;
VAL_ 778 DAS_rightVeh2VxRel 15 "SNA" ;
VAL_ 778 DAS_rightVeh2Id 0 "SNA" ;
VAL_ 778 DAS_cutinVehType 5 "PEDESTRIAN" 4 "BICYCLE" 3 "MOTORCYCLE" 2 "CAR" 1 "TRUCK" 0 "UNKNOWN" ;
VAL_ 778 DAS_cutinVehDx 255 "SNA" ;
VAL_ 778 DAS_cutinVehVxRel 15 "SNA" ;
VAL_ 778 DAS_cutinVehId 127 "SNA" ;
VAL_ 778 DAS_roadSignColor 4 "RED_YELLOW" 3 "GREEN" 2 "YELLOW" 1 "RED" 0 "NONE" ;
VAL_ 778 DAS_roadSignId 255 "SNA" 1 "TRAFFIC_LIGHT" 0 "STOP_SIGN" ;
VAL_ 778 DAS_roadSignStopLineDist 1023 "SNA" ;
VAL_ 778 DAS_roadSignSource 2 "VISION" 1 "NAV" 0 "NONE" ;
VAL_ 778 DAS_roadSignArrow 4 "UNKNOWN" 3 "STRAIGHT" 2 "RIGHT" 1 "LEFT" 0 "CIRCLE" ;
VAL_ 778 DAS_roadSignOrientation 2 "HORIZONTAL_3_LIGHT" 1 "VERTICAL_3_LIGHT" 0 "UNKNOWN" ;
VAL_ 781 DAS_positioningEngineStatusMulti 3 "Mux3" 2 "Mux2" 1 "Mux1" 0 "Mux0" ;
VAL_ 781 DAS_meoSolverNumRuns 3 "101_AND_ABOVE" 2 "11_TO_100" 1 "1_TO_10" 0 "0" ;
VAL_ 781 DAS_meoSolverReportTerminationTy 4 "USER_SUCCESS" 3 "USER_FAILURE" 2 "NO_CONVERGENCE" 1 "FAILURE" 0 "CONVERGENCE" ;
VAL_ 781 DAS_meoSolverReportTotalTimeS 6 "0_5_AND_ABOVE" 5 "0_4_TO_0_5" 4 "0_3_TO_0_4" 3 "0_2_TO_0_3" 2 "0_1_TO_0_2" 1 "0_TO_0_1" 0 "0" ;
VAL_ 781 DAS_meoHeadingValid 1 "TRUE" 0 "FALSE" ;
VAL_ 781 DAS_meoGpsQualityLevel 6 "GPS_QUALITY_SUB_LANE" 5 "GPS_QUALITY_LANE" 4 "GPS_QUALITY_ROAD" 3 "GPS_QUALITY_POOR" 2 "GPS_QUALITY_UNKNOWN" 1 "GPS_OUTPUT_UNAVAILABLE" 0 "GPS_NO_COMMUNICATION" ;
VAL_ 781 DAS_meoFixType 5 "TIME_ONLY_FIX" 4 "GNSS_DEAD_RECKONING_COMBINED" 3 "FIX_3D" 2 "FIX_2D" 1 "DEAD_RECKONING_ONLY" 0 "NO_FIX" ;
VAL_ 781 DAS_lastMeoResetReason 3 "EXTRAPOLATION_DEVIATES_FROM_SPP" 2 "SLAM_ANCHOR_NODE_OUT_OF_ORDER" 1 "INITIALIZE_STATE_FROM_CONTEXT_FAILED" 0 "UNKNOWN" ;
VAL_ 781 DAS_vioMultiGpsSelectedSource 5 "SEEDED_ORIGIN" 4 "RELOCALIZATION" 3 "BLUEFIN_SPP_TDCP" 2 "BLUEFIN_MEO" 1 "RAW_GPS" 0 "INVALID" ;
VAL_ 781 DAS_vioMultiGpsPeCooldownActive 1 "TRUE" 0 "FALSE" ;
VAL_ 781 DAS_vioMultiGpsPeSppTdcpConsiste 1 "TRUE" 0 "FALSE" ;
VAL_ 781 DAS_vioMultiGpsPeMeoConsistentWi 1 "TRUE" 0 "FALSE" ;
VAL_ 781 DAS_publishedGpsSource 3 "VIO_MULTI_GPS" 2 "VIO_GEODETIC_POSE" 1 "RAW_GPS_PASSTHROUGH" 0 "INVALID" ;
VAL_ 781 DAS_bluefinEnabled 1 "TRUE" 0 "FALSE" ;
VAL_ 781 DAS_orioleDisabled 1 "TRUE" 0 "FALSE" ;
VAL_ 781 DAS_disableMonarch 1 "TRUE" 0 "FALSE" ;
VAL_ 1548 DAS_TR_ObjIndex 31 "Mux31" 30 "Mux30" 29 "Mux29" 28 "Mux28" 27 "Mux27" 26 "Mux26" 25 "Mux25" 24 "Mux24" 23 "Mux23" 22 "Mux22" 21 "Mux21" 20 "Mux20" 19 "Mux19" 18 "Mux18" 17 "Mux17" 16 "Mux16" 15 "Mux15" 14 "Mux14" 13 "Mux13" 12 "Mux12" 11 "Mux11" 10 "Mux10" 9 "Mux9" 8 "Mux8" 7 "Mux7" 6 "Mux6" 5 "Mux5" 4 "Mux4" 3 "Mux3" 2 "Mux2" 1 "Mux1" 0 "Mux0" ;
VAL_ 1548 DAS_TR_Obj00_Class 4 "RADAR_CLASS_CONSTRUCTION_ELEMENT" 3 "RADAR_CLASS_MOVING_PEDESTRIAN" 2 "RADAR_CLASS_MOVING_TWO_WHEEL_VEHICLE" 1 "RADAR_CLASS_MOVING_FOUR_WHEEL_VEHICLE" 0 "RADAR_CLASS_UNKNOWN" ;
VAL_ 1548 DAS_TR_Obj00_MovingState 3 "RADAR_MOVESTATE_STANDING" 2 "RADAR_MOVESTATE_STOPPED" 1 "RADAR_MOVESTATE_MOVING" 0 "RADAR_MOVESTATE_INDETERMINATE" ;
VAL_ 282 GTW_BKP_BATT_MON 4095 "SNA" ;
VAL_ 282 GTW_BKP_BATT_NTC_P 4095 "SNA" ;
VAL_ 282 GTW_ECALL_GPS_ANT_BIAS 4095 "SNA" ;
VAL_ 282 GTW_ECALL_MIC_DIAG 4095 "SNA" ;
VAL_ 282 GTW_SOS_ECALL_nRQST_BUF 4095 "SNA" ;
VAL_ 1384 GTW_alertID 469 "a469_backlightFsmUnhealthy" 463 "a463_displayEdidReadFailed" 456 "a456_hrlStateMachinePageOwnershipError" 455 "a455_hrlDumpPageOwnershipError" 454 "a454_diagCanFrameOverread" 453 "a453_diagCanFdSetDesync" 452 "a452_diagCanStaleSocket" 451 "a451_diagCanBufferExhausted" 450 "a450_unexpectedAutopilotControlCanMessage" 439 "a439_VCCCversionMismatch" 438 "a438_wakeSourceUnknown" 437 "a437_softFlowControlNotRunning" 436 "a436_possibleCanRxIssue" 429 "a429_LUMBAR32RversionMismatch" 428 "a428_LUMBAR32LversionMismatch" 427 "a427_DISPBRIDGEversionMismatch" 422 "a422_ethSwitchSevereCongestionWatchdog" 421 "a421_ModemEthLinkDown" 420 "a420_unexpectedCanMessageLength" 418 "a418_TRCMversionMismatch" 414 "a414_socHeldInReset" 411 "a411_tASILStatusCheck" 410 "a410_unexpectedResetCause2" 409 "a409_unexpectedResetCause" 402 "a402_VCSEAT2RversionMismatch" 401 "a401_VCSEAT2LversionMismatch" 400 "a400_ethlSwitchOTPIncorrect" 399 "a399_ethIfRxTcpipQueueDrop" 398 "a398_awakeForExtendedTime" 397 "a397_alreadyInDrive" 396 "a396_alreadyInReverse" 395 "a395_lwipIcmpError" 394 "a394_WIPERversionMismatch" 393 "a393_osdSramCrcMismatch" 391 "a391_adspMacAddrCheckFailed" 390 "a390_displayFwQueryFailed" 389 "a389_rcmEventDetected" 388 "a388_adspWatchdogSkipped" 387 "a387_externalRtcReadFailure" 386 "a386_RCUCALversionMismatch" 385 "a385_RCUversionMismatch" 384 "a384_IDBCALversionMismatch" 383 "a383_IDB1versionMismatch" 382 "a382_IDBversionMismatch" 381 "a381_DPBCALversionMismatch" 380 "a380_DPBversionMismatch" 376 "a376_blFailedToExecBootImg" 366 "a366_uiGearRequestMismatch" 364 "a364_BLEEPCRADLEversionMismatch" 363 "a363_RGBDOORRRversionMismatch" 362 "a362_RGBDOORFRversionMismatch" 361 "a361_RGBDOORRLversionMismatch" 360 "a360_RGBDOORFLversionMismatch" 359 "a359_RGBIPFRversionMismatch" 358 "a358_RGBIPFLversionMismatch" 356 "a356_touchGPIOStatusCheck" 355 "a355_EPASTSversionMismatch" 354 "a354_EPASTPversionMismatch" 353 "a353_sASILStatusCheck" 352 "a352_mASILStatusCheck" 351 "a351_sOSDCrcCheck" 350 "a350_mOSDCrcCheck" 349 "a349_VCBLDCPBversionMismatch" 348 "a348_VCBLDCFversionMismatch" 342 "a342_VCBLDCPPversionMismatch" 336 "a336_possibleCanTxIssue" 334 "a334_hrlFolderSpaceLow" 332 "a332_unknownDisplayPN" 331 "a331_SWSRversionMismatch" 330 "a330_SWSLversionMismatch" 329 "a329_FOHMversionMismatch" 328 "a328_smartShiftDisabled" 323 "a323_gestureStartOutOfStrip" 322 "a322_gestureUnrecognizedFromMoving" 317 "a317_sdCardChkdskRepairFailed" 316 "a316_sdCardChkdskRepair" 314 "a314_canLogBlockWriteErr" 313 "a313_OSDActive" 312 "a312_hrlFileIncomplete" 311 "a311_canLogQueueFullBeforeFsInit" 309 "a309_VCUSBversionMismatch" 282 "a282_tcuPhyConfigurationFailed" 281 "a281_likelyMissedPoke" 280 "a280_hrlFrameDropped" 279 "a279_adspRepeatedWatchdog" 278 "a278_ethSwitchCongested" 277 "a277_NonRevCDrMOSMitigationFailed" 276 "a276_VDDSOC_DrMOS_Fault" 275 "a275_VDDCORE_DrMOS_Fault" 274 "a274_BLEEPREARRIGHTversionMismatch" 273 "a273_BLEEPREARLEFTversionMismatch" 268 "a268_stoMIA" 267 "a267_dpp2MIA" 266 "a266_dpp1MIA" 265 "a265_optionFlagsError" 264 "a264_hrlPseudoFileAvail" 263 "a263_hrlUdpFileAvail" 262 "a262_canLogBlockDropped" 261 "a261_adspWatchdog" 260 "a260_unknownPN" 255 "a255_rtc32KHzWatchdog" 246 "a246_touchcoreHeartbeat" 245 "a245_apsNotDisabled" 244 "a244_SDCRversionMismatch" 230 "a230_touchInterruptStorm" 229 "a229_displaySoftsetConnection" 228 "a228_DISPOSDversionMismatch" 227 "a227_DISPTOUCHversionMismatch" 226 "a226_DISPversionMismatch" 225 "a225_resetOnSleepWake" 224 "a224_sdCardUpgradeNeeded" 223 "a223_LVBMSversionMismatch" 219 "a219_CMPSversionMismatch" 218 "a218_switchOTPIncorrect" 186 "a186_swrPrecaution" 176 "a176_TPMShardWarnRearRight" 175 "a175_TPMShardWarnRearLeft" 174 "a174_TPMShardWarnFrontRight" 173 "a173_TPMShardWarnFrontLeft" 172 "a172_TPMSsoftWarnRearRight" 171 "a171_TPMSsoftWarnRearLeft" 170 "a170_TPMSsoftWarnFrontRight" 169 "a169_TPMSsoftWarnFrontLeft" 168 "a168_nErrCanFaultParty" 167 "a167_nErrCanFaultCh" 166 "a166_nErrCanFaultVeh" 165 "a165_USMversionMismatch" 164 "a164_VCBATTversionMismatch" 155 "a155_PMversionMismatch" 153 "a153_externalRtcAlarmFailure" 151 "a151_HCM3RversionMismatch" 150 "a150_HCM3LversionMismatch" 149 "a149_rtcTimeSetInPast" 147 "a147_updateAbortFor12v" 146 "a146_performancePackageMismatch" 145 "a145_carConfigsNotWritten" 144 "a144_hrlStateMachine" 143 "a143_possibleCanWakeIssue" 141 "a141_teleCANETHis" 140 "a140_cancoreHeartbeat" 139 "a139_CMPDversionMismatch" 138 "a138_sdCardEndOfLife" 137 "a137_lowHeap" 136 "a136_hrlGameModeFileAvail" 135 "a135_canLogQueueFull" 134 "a134_disableFeatureFailed" 133 "a133_adspFaultDetected" 129 "a129_ICRversionMismatch" 127 "a127_noFilePointersAvailable" 125 "a125_switchReplayUnlocked" 123 "a123_BDYbusOverloaded" 122 "a122_BDY_canFault" 120 "a120_switchUnlocked" 118 "a118_unexpectedFunctionalResetStatus" 117 "a117_unexpectedDestructiveResetStatus" 116 "a116_switchInitFailed" 115 "a115_hrlEventFileAvail" 114 "a114_updtRetried" 113 "a113_unrecognizedCanMessage" 112 "a112_z4bDisabled" 111 "a111_writeMdioFailed" 110 "a110_readMdioFailed" 109 "a109_failedToStartUpdater" 108 "a108_BLEEPREARversionMismatch" 107 "a107_BLEEPRIGHTversionMismatch" 106 "a106_BLEEPLEFTversionMismatch" 105 "a105_eBuckConfigured" 104 "a104_sdCardDriverArgCorrupted" 103 "a103_sdCardFormatted" 101 "a101_switchWatchdog" 100 "a100_CBCversionMismatch" 99 "a099_SWCversionMismatch" 98 "a098_HCMRversionMismatch" 97 "a097_HCMLversionMismatch" 96 "a096_sdCardFatCorrupted" 95 "a095_sdCardFull" 94 "a094_sdCardInvReqOverflowCount" 93 "a093_sdCardInvReqOverflowBase" 92 "a092_sdCardInvReqZero" 91 "a091_lowStack" 90 "a090_ocuFailed" 89 "a089_sdCardWatchdog" 88 "a088_sdCardInvReqParallel" 87 "a087_ocuInProgress" 86 "a086_ocu" 85 "a085_fuseStateUnknown" 84 "a084_canFrameDropped" 83 "a083_udsMsgDroppedByTcpStack" 82 "a082_sdCardBSCorrupted" 81 "a081_udsMessageRejected" 80 "a080_CHbusOverloaded" 79 "a079_PARTYbusOverloaded" 78 "a078_VEHbusOverloaded" 77 "a077_bmpPmicError" 76 "a076_ethInterfaceReset" 75 "a075_epas3sMIA" 74 "a074_epas3pMIA" 73 "a073_steeringWheelReset" 72 "a072_updateFailure" 71 "a071_hrlTrigger" 70 "a070_hrlDump" 69 "a069_diskioErr" 68 "a068_prodKeyMissing" 67 "a067_tcpDebug" 66 "a066_exception" 65 "a065_PARTY_canFault" 64 "a064_CH_canFault" 63 "a063_VEH_canFault" 62 "a062_bmpWatchdog" 61 "a061_bmpSleepFailure" 60 "a060_unFused" 59 "a059_inFactoryMode" 58 "a058_rtcAlarmFailure" 57 "a057_i2cFailure" 55 "a055_OPCFversionMismatch" 54 "a054_OPCRversionMismatch" 53 "a053_busSleepFailure" 52 "a052_ifTxSpans" 51 "a051_sdCardFileSystemFailure" 50 "a050_sdCardInitFailure" 49 "a049_corruptedManifest" 48 "a048_EPAS3SversionMismatch" 47 "a047_VCRIGHTversionMismatch" 46 "a046_VCLEFTversionMismatch" 45 "a045_VCFRONTversionMismatch" 43 "a043_THSversionMismatch" 42 "a042_TASversionMismatch" 41 "a041_VCSECversionMismatch" 40 "a040_SCCMversionMismatch" 39 "a039_RCMCALversionMismatch" 38 "a038_RCMversionMismatch" 37 "a037_RADCversionMismatch" 36 "a036_PTCversionMismatch" 35 "a035_PMFversionMismatch" 34 "a034_PMRversionMismatch" 33 "a033_PCSCPU2versionMismatch" 32 "a032_PCSversionMismatch" 31 "a031_PARKversionMismatch" 30 "a030_OCS1PversionMismatch" 29 "a029_IBSTCALversionMismatch" 28 "a028_IBSTversionMismatch" 27 "a027_HVPversionMismatch" 26 "a026_GTWversionMismatch" 25 "a025_ESPCALversionMismatch" 24 "a024_ESPversionMismatch" 23 "a023_EPBRversionMismatch" 22 "a022_EPBLversionMismatch" 21 "a021_EPAS3PversionMismatch" 20 "a020_DIRversionMismatch" 19 "a019_CPversionMismatch" 18 "a018_CMPversionMismatch" 17 "a017_BMSversionMismatch" 16 "a016_BLEEPCENTERversionMismatch" 15 "a015_DIFversionMismatch" 14 "a014_APSversionMismatch" 12 "a012_maincoreWatchdog" 11 "a011_cancoreWatchdog" 10 "a010_wdTaskCount" 9 "a009_lateTask" 8 "a008_ifPbufAllocError" 7 "a007_ifRxBufError" 6 "a006_ifTxOutputFull" 5 "a005_stackOverflowHook" 4 "a004_mallocHook" 3 "a003_logWriteRecord" 2 "a002_taskError" 1 "a001_canEthTxQueue" 0 "ALERT_DO_NOT_USE_ZERO" ;
VAL_ 1384 GTW_alertState 1 "SET" 0 "CLEARED" ;
VAL_ 1384 GTW_a049_headerError 3 "HEADER_READ_FAIL" 2 "MUID_LIST_UNEXPECTED" 1 "HEADER_INFO_BAD" 0 "HEADER_OK" ;
VAL_ 1384 GTW_a062_bmpWatchdogReason 4 "THERMAL_TRIP" 3 "SLEEP_FAILURE" 2 "WAKE_FAILURE" 1 "RUNTIME_FAILURE" 0 "WATCHDOG_NONE" ;
VAL_ 1384 GTW_a063_VEH_faultConfinement 2 "BUS_OFF" 1 "ERROR_PASSIVE" 0 "ERROR_ACTIVE" ;
VAL_ 1384 GTW_a064_CH_faultConfinement 2 "BUS_OFF" 1 "ERROR_PASSIVE" 0 "ERROR_ACTIVE" ;
VAL_ 1384 GTW_a065_PARTY_faultConfinement 2 "BUS_OFF" 1 "ERROR_PASSIVE" 0 "ERROR_ACTIVE" ;
VAL_ 1384 GTW_a073_SOCResetRequestor 4 "DAS" 3 "VCSEC" 2 "FORCE" 1 "BUTTONS" 0 "UNKNOWN" ;
VAL_ 1384 GTW_a077_bmpPmicErrorType 4 "INTERNAL_SM" 3 "OT" 2 "MEM_CORRUPT" 1 "OC_OV_CC" 0 "NONE" ;
VAL_ 1384 GTW_a122_BDY_faultConfinement 2 "BUS_OFF" 1 "ERROR_PASSIVE" 0 "ERROR_ACTIVE" ;
VAL_ 1384 GTW_a261_failureReason 6 "INCORRECT_TYPE" 5 "INCORRECT_SEQ_NO" 4 "INCORRECT_ID" 3 "INCORRECT_ADDRESS" 2 "INCORRECT_LENGTH" 1 "RECEIVE_ERROR" 0 "NO_ERROR" ;
VAL_ 1384 GTW_a277_mitigationFailureReason 7 "FAILED_NVRAM_WRITE" 6 "FAILED_NVRAM_WRITE_PROTECTED" 5 "FAILED_REGISTERS_WRITE_PROTECTED" 4 "FAILED_REGISTER_WRITE" 3 "FAILED_REGISTER_READ" 2 "FAILED_ICE_NOT_AWAKE" 1 "NOT_NEEDED" 0 "APPLIED_SUCCESSFULLY" ;
VAL_ 1384 GTW_a279_failureReason 6 "INCORRECT_TYPE" 5 "INCORRECT_SEQ_NO" 4 "INCORRECT_ID" 3 "INCORRECT_ADDRESS" 2 "INCORRECT_LENGTH" 1 "RECEIVE_ERROR" 0 "NO_ERROR" ;
VAL_ 1384 GTW_a317_status 7 "MASK" 4 "PARTIAL" 3 "FAILED" 2 "SUCCESS" 1 "NOT_NEEDED" ;
VAL_ 1384 GTW_a317_errorCode 19 "FS_INFO_INVALID_SIG" 18 "FS_INFO_SECTOR_NOT_FOUND" 17 "FS_INFO_READ_FAILED" 16 "FS_INFO_WRITE_FAILED" 15 "INVALID_CLUSTER" 14 "DIR_TOO_DEEP" 13 "UNKNOWN_FS" 12 "CLUSTER_IN_USE" 11 "FAT_MISMATCHED" 10 "FAT_READ_FAILED" 9 "FAT_WRITE_FAILED" 8 "NOT_FAT32" 7 "BAD_SECTOR_SIZE" 6 "BR_READ_FAILED" 5 "MBR_READ_FAILED" 4 "DISK_INIT_FAILED" 3 "INSUFFICIENT_MEMORY" 2 "ERROR_FOUND_FIXED" 1 "ERROR_FOUND" 0 "NO_ERROR" ;
VAL_ 62 GTW_matrixIndex 7 "AlertMatrix7" 6 "AlertMatrix6" 5 "AlertMatrix5" 4 "AlertMatrix4" 3 "AlertMatrix3" 2 "AlertMatrix2" 1 "AlertMatrix1" 0 "AlertMatrix0" ;
VAL_ 838 GTW_autopilotOverrideState 8 "UNKNOWN" 7 "VEHICLE_MANAGED" 6 "OPTION_OVERRIDE" 5 "OPTION_CODE" 4 "TIMEBOUND_TRIAL" 3 "TIMEBOUND_SUBSCRIPTION" 2 "TRIAL" 1 "SUBSCRIPTION" 0 "BASE" ;
VAL_ 838 GTW_autopilotConfig 4 "BASIC" 3 "SELF_DRIVING" 2 "ENHANCED" 1 "HIGHWAY" 0 "NONE" ;
VAL_ 838 GTW_autopilotOverrideConfig 4 "BASIC" 3 "SELF_DRIVING" 2 "ENHANCED" 1 "HIGHWAY" 0 "NONE" ;
VAL_ 838 GTW_autopilotConfigSource 2 "AUTOPILOT_NOT_UPDATED" 1 "AUTOPILOT" 0 "GATEWAY" ;
VAL_ 904 GTW_VEH_faultConfinement 2 "BUS_OFF" 1 "ERROR_PASSIVE" 0 "ERROR_ACTIVE" ;
VAL_ 904 GTW_PARTY_faultConfinement 2 "BUS_OFF" 1 "ERROR_PASSIVE" 0 "ERROR_ACTIVE" ;
VAL_ 904 GTW_CH_faultConfinement 2 "BUS_OFF" 1 "ERROR_PASSIVE" 0 "ERROR_ACTIVE" ;
VAL_ 904 GTW_BDY_faultConfinement 2 "BUS_OFF" 1 "ERROR_PASSIVE" 0 "ERROR_ACTIVE" ;
VAL_ 1080 GTW_ethWakeUpReason 17 "GTW_WAKEUP_REASON_TCU_TC10_VERSION_CHECK" 16 "GTW_WAKEUP_REASON_EGGLEFT_LINK_DOWN" 15 "GTW_WAKEUP_REASON_RCMPRIVATE_CAN" 14 "GTW_WAKEUP_REASON_VCLEFT" 13 "GTW_WAKEUP_REASON_LOOP" 12 "GTW_WAKEUP_REASON_DISPLAY_TAP" 11 "GTW_WAKEUP_REASON_URGENT_TRANSMIT_ALERT" 10 "GTW_WAKEUP_REASON_BDY_CAN" 9 "GTW_WAKEUP_REASON_PT_CAN" 8 "GTW_WAKEUP_REASON_UI_SCHEDULED" 7 "GTW_WAKEUP_REASON_RTC_ALARM" 6 "GTW_WAKEUP_REASON_VCFRONT" 5 "GTW_WAKEUP_REASON_VEH_CAN" 4 "GTW_WAKEUP_REASON_ETH_CAN" 3 "GTW_WAKEUP_REASON_CH_CAN" 2 "GTW_WAKEUP_REASON_GSM_RI" 1 "GTW_WAKEUP_REASON_RESET" 0 "GTW_WAKEUP_REASON_NONE" ;
VAL_ 1656 GTW_gearShiftRequest 4 "GEAR_REQUEST_DRIVE" 3 "GEAR_REQUEST_NEUTRAL" 2 "GEAR_REQUEST_REVERSE" 1 "GEAR_REQUEST_PARK" 0 "GEAR_REQUEST_IDLE_SNA" ;
VAL_ 1656 GTW_primaryGearControlStatus 14 "NOT_QUALIFIED_RHD_CONFIG_UNAVAILABLE" 13 "NOT_QUALIFIED_DISPLAY_KNOWN_FROZEN_SCREEN" 12 "NOT_QUALIFIED_DISPLAY_ASIL_VIDEO_ERROR" 11 "NOT_QUALIFIED_GEAR_STRIP_MISMATCH" 10 "NOT_QUALIFIED_DISPLAY_UNTRAINED" 9 "NOT_QUALIFIED_UI_NO_RESP_GEAR_STRIP" 8 "NOT_QUALIFIED_CENTER_DISP_UI_UNHEALTHY" 7 "NOT_QUALIFIED_DISPLAY_FROZEN_ON_GESTURE" 6 "NOT_QUALIFIED_LOW_BRIGHTNESS" 5 "NOT_QUALIFIED_FALSE_TOUCH" 4 "NOT_QUALIFIED_MANUAL" 3 "NOT_QUALIFIED_DISPLAY_ERRS" 2 "NOT_QUALIFIED_FULLSCREEN" 1 "QUALIFIED" 0 "NOT_QUALIFIED" ;
VAL_ 1656 GTW_autoParkRequest 1 "ACTIVE" 0 "IDLE" ;
VAL_ 1656 GTW_smartShiftStatus 9 "DISABLED_AUDIO_NOT_READY" 8 "DISABLED_OSD_ACTIVATED" 7 "DISABLED_DISQUALIFIED" 6 "DISABLED_FULLSCREEN" 5 "DISABLED_UI_MIA" 4 "DISABLED_CLUSTER_DISP_ERR" 3 "DISABLED_CENTER_DISP_ERR" 2 "DISABLED_UI_CONFIG" 1 "ENABLED" 0 "DISABLED_SNA" ;
VAL_ 1656 GTW_gearStripChangeReason 27 "EBUCK_DISABLE" 26 "SLEEP_DISABLE" 25 "VC_MIA_GRACE_DISABLE" 24 "VC_MIA_ENABLE" 23 "DRIVERLESS_NO_TAKEOVER_DISABLE" 22 "EMERGENCY_OPERATION_ENABLE" 21 "WOT_ENABLE" 20 "PARK_ENGAGED_ENABLE" 19 "MISSING_SPEED_OR_STEERING_ESTIMATE_IN_D_ENABLE" 18 "UI_MIA_ENABLE" 16 "NOT_DRIVE_STATE_DISABLE" 15 "FULLSCREEN_DISABLE" 14 "DEFAULT_DISABLE" 13 "REVERSE_ENABLE" 12 "NEUTRAL_ENABLE" 11 "P_AND_BRAKE_ENABLE" 10 "CHARGING_DISABLE" 9 "CRUISE_ACTIVE_DISABLE" 8 "DI_MIA_ENABLE" 7 "HIGH_ACCEL_DISABLE" 6 "MEDIUM_SPEED_DISABLE" 5 "TRAFFIC_CONTROL_NO_CHANGE" 4 "VERY_LOW_SPEED_ENABLE" 3 "HIGH_STEERING_ANGLE_ENABLE" 2 "HIGH_JERK_ENABLE" 1 "DRIVER_BRAKE_APPLY_ENABLE" 0 "SNA" ;
VAL_ 1656 GTW_screenPCBTemperature 2047 "GTW_I2C_TEMP_SNA" ;
